VERSION "dbc-export 1 2025.20.8"

NS_ :

BS_:

BU_: APP APS DAS EPAS3S EPASTS ESP GTW IBST IDB PARK RADC RCM RCM3 RCU TPMS USM

BO_ 841 DAS_warningMatrix2: 8 DAS
 SG_ DAS_w129_mainCamExtNotCal : 0|1@1+ (1,0) [0|1] "" Vector__XXX
 SG_ DAS_w130_narrowCamExtNotCal : 1|1@1+ (1,0) [0|1] "" Vector__XXX
 SG_ DAS_w131_mainCamCalSaved : 2|1@1+ (1,0) [0|1] "" Vector__XXX
 SG_ DAS_w132_narrowCamCalSaved : 3|1@1+ (1,0) [0|1] "" Vector__XXX
 SG_ DAS_w133_mainCamInitFault : 4|1@1+ (1,0) [0|1] "" Vector__XXX
 SG_ DAS_w134_narrowCamInitFault : 5|1@1+ (1,0) [0|1] "" Vector__XXX
 SG_ DAS_w135_fisheyeCamInitFault : 6|1@1+ (1,0) [0|1] "" Vector__XXX
 SG_ DAS_w136_lPillarCamInitFault : 7|1@1+ (1,0) [0|1] "" Vector__XXX
 SG_ DAS_w137_rPillarCamInitFault : 8|1@1+ (1,0) [0|1] "" Vector__XXX
 SG_ DAS_w138_lRepeatCamInitFault : 9|1@1+ (1,0) [0|1] "" Vector__XXX
 SG_ DAS_w139_rRepeatCamInitFault : 10|1@1+ (1,0) [0|1] "" Vector__XXX
 SG_ DAS_w140_backupCamInitFault : 11|1@1+ (1,0) [0|1] "" Vector__XXX
 SG_ DAS_w141_ECU_Thermal_Issue : 12|1@1+ (1,0) [0|1] "" Vector__XXX
 SG_ DAS_w142_fwdCamPitchProblem : 13|1@1+ (1,0) [0|1] "" Vector__XXX
 SG_ DAS_w143_IDF_event : 14|1@1+ (1,0) [0|1] "" Vector__XXX
 SG_ DAS_w144_selfieCamInitFault : 15|1@1+ (1,0) [0|1] "" Vector__XXX
 SG_ DAS_w171_fisheyeCamExtNotCal : 42|1@1+ (1,0) [0|1] "" Vector__XXX
 SG_ DAS_w172_lPillarCamExtNotCal : 43|1@1+ (1,0) [0|1] "" Vector__XXX
 SG_ DAS_w173_rPillarCamExtNotCal : 44|1@1+ (1,0) [0|1] "" Vector__XXX
 SG_ DAS_w174_lRepeatCamExtNotCal : 45|1@1+ (1,0) [0|1] "" Vector__XXX
 SG_ DAS_w175_rRepeatCamExtNotCal : 46|1@1+ (1,0) [0|1] "" Vector__XXX
 SG_ DAS_w177_fisheyeCamCalSaved : 48|1@1+ (1,0) [0|1] "" Vector__XXX
 SG_ DAS_w178_lPillarCamCalSaved : 49|1@1+ (1,0) [0|1] "" Vector__XXX
 SG_ DAS_w179_rPillarCamCalSaved : 50|1@1+ (1,0) [0|1] "" Vector__XXX
 SG_ DAS_w180_lRepeatCamCalSaved : 51|1@1+ (1,0) [0|1] "" Vector__XXX
 SG_ DAS_w181_rRepeatCamCalSaved : 52|1@1+ (1,0) [0|1] "" Vector__XXX

BO_ 1082 DAS_warningMatrix3: 8 DAS
 SG_ DAS_w193_camWindshieldUnclean : 0|1@1+ (1,0) [0|1] "" Vector__XXX
 SG_ DAS_w194_accDriverResumeRqrd : 1|1@1+ (1,0) [0|1] "" Vector__XXX
 SG_ DAS_w195_scwUnavailable : 2|1@1+ (1,0) [0|1] "" Vector__XXX
 SG_ DAS_w196_stopSignWarning : 3|1@1+ (1,0) [0|1] "" Vector__XXX
 SG_ DAS_w197_redLightWarning : 4|1@1+ (1,0) [0|1] "" Vector__XXX
 SG_ DAS_w198_tsrUnavailable : 5|1@1+ (1,0) [0|1] "" Vector__XXX
 SG_ DAS_w199_apcAbort : 6|1@1+ (1,0) [0|1] "" Vector__XXX
 SG_ DAS_w200_lcSlowdown : 7|1@1+ (1,0) [0|1] "" Vector__XXX
 SG_ DAS_w201_lcAborting : 8|1@1+ (1,0) [0|1] "" Vector__XXX
 SG_ DAS_w202_scwNoisyEnvironment : 9|1@1+ (1,0) [0|1] "" Vector__XXX
 SG_ DAS_w203_apcActivation : 10|1@1+ (1,0) [0|1] "" Vector__XXX
 SG_ DAS_w204_apcFinalFront : 11|1@1+ (1,0) [0|1] "" Vector__XXX
 SG_ DAS_w205_apcFinalRear : 12|1@1+ (1,0) [0|1] "" Vector__XXX
 SG_ DAS_w206_autosteerNotEnabled : 13|1@1+ (1,0) [0|1] "" Vector__XXX
 SG_ DAS_w207_autosteerUnavailable : 14|1@1+ (1,0) [0|1] "" Vector__XXX
 SG_ DAS_w208_rackDetected : 15|1@1+ (1,0) [0|1] "" Vector__XXX
 SG_ DAS_w209_autoSummonRequest : 16|1@1+ (1,0) [0|1] "" Vector__XXX
 SG_ DAS_w210_camObstrcted : 17|1@1+ (1,0) [0|1] "" Vector__XXX
 SG_ DAS_w211_accNoSeatBelt : 18|1@1+ (1,0) [0|1] "" Vector__XXX
 SG_ DAS_w212_lcUnavailableStrikeOut : 19|1@1+ (1,0) [0|1] "" Vector__XXX
 SG_ DAS_w213_autosteerStruckOut : 20|1@1+ (1,0) [0|1] "" Vector__XXX
 SG_ DAS_w214_driverNotIntracting : 21|1@1+ (1,0) [0|1] "" Vector__XXX
 SG_ DAS_w215_contDriverNotIntracting : 22|1@1+ (1,0) [0|1] "" Vector__XXX
 SG_ DAS_w216_driverOverriding : 23|1@1+ (1,0) [0|1] "" Vector__XXX
 SG_ DAS_w217_lcUnavailableSpeeding : 24|1@1+ (1,0) [0|1] "" Vector__XXX
 SG_ DAS_w218_lcSpeedExceededLimit : 25|1@1+ (1,0) [0|1] "" Vector__XXX
 SG_ DAS_w219_lcTempUnavailableSpeed : 26|1@1+ (1,0) [0|1] "" Vector__XXX
 SG_ DAS_w220_lcTempUnavailableRoad : 27|1@1+ (1,0) [0|1] "" Vector__XXX
 SG_ DAS_w221_accRadarBlind : 28|1@1+ (1,0) [0|1] "" Vector__XXX
 SG_ DAS_w222_accCameraBlind : 29|1@1+ (1,0) [0|1] "" Vector__XXX
 SG_ DAS_w223_accObjectInPath : 30|1@1+ (1,0) [0|1] "" Vector__XXX
 SG_ DAS_w224_accCameraCalibration : 31|1@1+ (1,0) [0|1] "" Vector__XXX
 SG_ DAS_w225_lcDegradedVisSpeedLmt : 32|1@1+ (1,0) [0|1] "" Vector__XXX
 SG_ DAS_w226_lcCamCalNeededSpeedLmt : 33|1@1+ (1,0) [0|1] "" Vector__XXX
 SG_ DAS_w227_virtualWallBlocked : 34|1@1+ (1,0) [0|1] "" Vector__XXX
 SG_ DAS_w228_DEPRECATED : 35|1@1+ (1,0) [0|1] "" Vector__XXX
 SG_ DAS_w229_alcUltrasoundDamaged : 36|1@1+ (1,0) [0|1] "" Vector__XXX
 SG_ DAS_w230_alcUltrasoundBlocked : 37|1@1+ (1,0) [0|1] "" Vector__XXX
 SG_ DAS_w231_idfEvent : 38|1@1+ (1,0) [0|1] "" Vector__XXX
 SG_ DAS_w232_laneChangeRequested : 39|1@1+ (1,0) [0|1] "" Vector__XXX

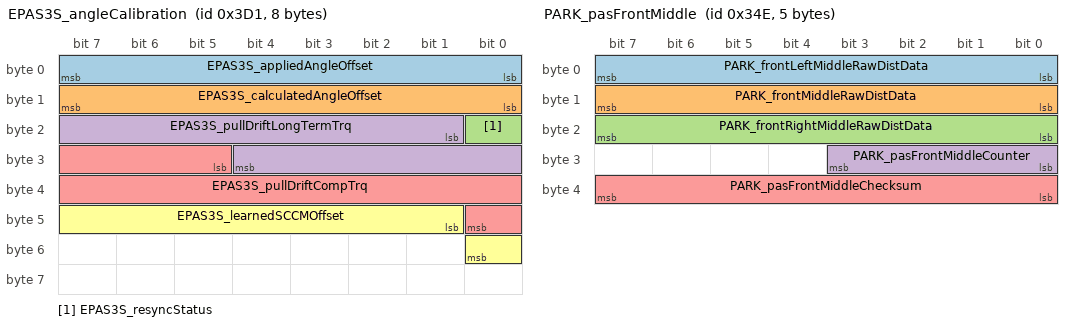
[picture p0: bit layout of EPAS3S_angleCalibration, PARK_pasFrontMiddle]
BO_ 977 EPAS3S_angleCalibration: 8 EPAS3S
 SG_ EPAS3S_appliedAngleOffset : 0|8@1+ (0.1,-12.8) [-12.8|12.7] "deg" Vector__XXX
 SG_ EPAS3S_calculatedAngleOffset : 8|8@1+ (0.1,-12.8) [-12.8|12.7] "deg" Vector__XXX
 SG_ EPAS3S_resyncStatus : 16|1@1+ (1,0) [0|1] "" Vector__XXX
 SG_ EPAS3S_pullDriftLongTermTrq : 17|12@1+ (0.01,-10) [-10|10] "Nm" Vector__XXX
 SG_ EPAS3S_pullDriftCompTrq : 29|12@1+ (0.01,-10) [-10|10] "Nm" Vector__XXX
 SG_ EPAS3S_learnedSCCMOffset : 41|8@1+ (0.1,-12.8) [-12.8|12.7] "deg" Vector__XXX

BO_ 785 EPAS3S_info: 8 EPAS3S
 SG_ EPAS3S_infoIndex M : 0|8@1+ (1,0) [0|255] "" Vector__XXX
 SG_ EPAS3S_infoBuildType m10 : 8|8@1+ (1,0) [0|255] "" Vector__XXX
 SG_ EPAS3S_infoComponentID m10 : 48|16@1+ (1,0) [0|65535] "" Vector__XXX
 SG_ EPAS3S_infoPcbaID m11 : 16|8@1+ (1,0) [0|255] "" Vector__XXX
 SG_ EPAS3S_infoAssemblyID m11 : 24|8@1+ (1,0) [0|255] "" Vector__XXX
 SG_ EPAS3S_infoUsageID m11 : 32|16@1+ (1,0) [0|65535] "" Vector__XXX
 SG_ EPAS3S_infoApplicationCRC m13 : 32|32@1+ (1,0) [0|4294967295] "" Vector__XXX
 SG_ EPAS3S_infoBootUdsProtoVersion m20 : 8|8@1+ (1,0) [0|255] "" Vector__XXX
 SG_ EPAS3S_infoBootloaderCRC m20 : 32|32@1+ (1,0) [0|4294967295] "" Vector__XXX
 SG_ EPAS3S_infoSubcomponent2 m23 : 32|32@1+ (1,0) [0|4294967295] "" Vector__XXX

BO_ 920 EPASTS_alertMatrix: 8 EPASTS
 SG_ EPASTS_matrixIndex M : 0|4@1+ (1,0) [0|15] "" Vector__XXX
 SG_ EPASTS_a001_adcCalibrationOrInit m0 : 4|1@1+ (1,0) [0|1] "" Vector__XXX
 SG_ EPASTS_a002_adcMuxErr m0 : 5|1@1+ (1,0) [0|1] "" Vector__XXX
 SG_ EPASTS_a003_pspInvalidParamset m0 : 6|1@1+ (1,0) [0|1] "" Vector__XXX
 SG_ EPASTS_a004_scpInputMia m0 : 7|1@1+ (1,0) [0|1] "" Vector__XXX
 SG_ EPASTS_a005_scpUnknownResetSourc m0 : 8|1@1+ (1,0) [0|1] "" Vector__XXX
 SG_ EPASTS_a006_swrhResetByInvalidEr m0 : 9|1@1+ (1,0) [0|1] "" Vector__XXX
 SG_ EPASTS_a007_tsmcCoreTempDiff m0 : 10|1@1+ (1,0) [0|1] "" Vector__XXX
 SG_ EPASTS_a008_psdcPlatformShutdown m0 : 11|1@1+ (1,0) [0|1] "" Vector__XXX
 SG_ EPASTS_a009_mcusscLbistPermanent m0 : 12|1@1+ (1,0) [0|1] "" Vector__XXX
 SG_ EPASTS_a010_svcIncompatibleSwVer m0 : 13|1@1+ (1,0) [0|1] "" Vector__XXX
 SG_ EPASTS_a011_mcusscMonbistErr m0 : 14|1@1+ (1,0) [0|1] "" Vector__XXX
 SG_ EPASTS_a012_mcusscMbistEccErr m0 : 15|1@1+ (1,0) [0|1] "" Vector__XXX
 SG_ EPASTS_a013_mcusscSffMonitoringF m0 : 16|1@1+ (1,0) [0|1] "" Vector__XXX
 SG_ EPASTS_a014_mcusscSffMonitoringM m0 : 17|1@1+ (1,0) [0|1] "" Vector__XXX
 SG_ EPASTS_a015_mcusscCsErrorCheckFa m0 : 18|1@1+ (1,0) [0|1] "" Vector__XXX
 SG_ EPASTS_a016_mcufcCsErrorCheckFai m0 : 19|1@1+ (1,0) [0|1] "" Vector__XXX
 SG_ EPASTS_a017_stmdStmPlausibilityC m0 : 20|1@1+ (1,0) [0|1] "" Vector__XXX
 SG_ EPASTS_a018_exchCsErrorCheck m0 : 21|1@1+ (1,0) [0|1] "" Vector__XXX
 SG_ EPASTS_a019_rsthHwResetInfoCorru m0 : 22|1@1+ (1,0) [0|1] "" Vector__XXX
 SG_ EPASTS_a020_mcusscEolEcuIdIntegr m0 : 23|1@1+ (1,0) [0|1] "" Vector__XXX
 SG_ EPASTS_a021_osehCsErrorCheck m0 : 24|1@1+ (1,0) [0|1] "" Vector__XXX
 SG_ EPASTS_a022_swrhSwResetInfoCorru m0 : 25|1@1+ (1,0) [0|1] "" Vector__XXX
 SG_ EPASTS_a023_btarcCorruptionCheck m0 : 26|1@1+ (1,0) [0|1] "" Vector__XXX
 SG_ EPASTS_a024_srhCsErrorCheckFail m0 : 27|1@1+ (1,0) [0|1] "" Vector__XXX
 SG_ EPASTS_a025_btarcCorruptionCheck m0 : 28|1@1+ (1,0) [0|1] "" Vector__XXX
 SG_ EPASTS_a026_mrccCsErrorCheckFail m0 : 29|1@1+ (1,0) [0|1] "" Vector__XXX
 SG_ EPASTS_a027_mcusscDmuHfErr m0 : 30|1@1+ (1,0) [0|1] "" Vector__XXX
 SG_ EPASTS_a028_smuhNonInitDataCorru m0 : 31|1@1+ (1,0) [0|1] "" Vector__XXX
 SG_ EPASTS_a029_smuhSmuCoreCntErrorT m0 : 32|1@1+ (1,0) [0|1] "" Vector__XXX
 SG_ EPASTS_a030_rsthClockReset m0 : 33|1@1+ (1,0) [0|1] "" Vector__XXX
 SG_ EPASTS_a031_pmsProductionModeFai m0 : 34|1@1+ (1,0) [0|1] "" Vector__XXX
 SG_ EPASTS_a032_eolpEolCheckFailed m0 : 35|1@1+ (1,0) [0|1] "" Vector__XXX
 SG_ EPASTS_a033_icsvcPswVersionMisma m0 : 36|1@1+ (1,0) [0|1] "" Vector__XXX
 SG_ EPASTS_a034_sbchReadbackRegFail m0 : 37|1@1+ (1,0) [0|1] "" Vector__XXX
 SG_ EPASTS_a035_sbchChipIdFail m0 : 38|1@1+ (1,0) [0|1] "" Vector__XXX
 SG_ EPASTS_a036_sbcmSbcBistFailed m0 : 39|1@1+ (1,0) [0|1] "" Vector__XXX
 SG_ EPASTS_a037_epmV5P2Fail m0 : 40|1@1+ (1,0) [0|1] "" Vector__XXX
 SG_ EPASTS_a038_csohCh1CsErrorErrAtR m0 : 41|1@1+ (1,0) [0|1] "" Vector__XXX
 SG_ EPASTS_a039_csohCh2CsErrorErrAtR m0 : 42|1@1+ (1,0) [0|1] "" Vector__XXX
 SG_ EPASTS_a040_swrhLimitedResetRetr m0 : 43|1@1+ (1,0) [0|1] "" Vector__XXX
 SG_ EPASTS_a041_imcmCoreConfiguratio m0 : 44|1@1+ (1,0) [0|1] "" Vector__XXX
 SG_ EPASTS_a042_wdhWdTestFail m0 : 45|1@1+ (1,0) [0|1] "" Vector__XXX
 SG_ EPASTS_a043_sbcmWdStateDisabled m0 : 46|1@1+ (1,0) [0|1] "" Vector__XXX
 SG_ EPASTS_a044_sbcmSbcEepromFail m0 : 47|1@1+ (1,0) [0|1] "" Vector__XXX
 SG_ EPASTS_a045_psumSbcBandgapVoltEr m0 : 48|1@1+ (1,0) [0|1] "" Vector__XXX
 SG_ EPASTS_a046_mcusscOscillatorNotR m0 : 49|1@1+ (1,0) [0|1] "" Vector__XXX
 SG_ EPASTS_a047_epmVregVoltFail m0 : 50|1@1+ (1,0) [0|1] "" Vector__XXX
 SG_ EPASTS_a048_epmVcpVoltFail m0 : 51|1@1+ (1,0) [0|1] "" Vector__XXX
 SG_ EPASTS_a049_epmLgFail m0 : 52|1@1+ (1,0) [0|1] "" Vector__XXX
 SG_ EPASTS_a050_erlErr m0 : 53|1@1+ (1,0) [0|1] "" Vector__XXX
 SG_ EPASTS_a051_ermMessageErr m0 : 54|1@1+ (1,0) [0|1] "" Vector__XXX
 SG_ EPASTS_a052_ermSdcInputBufferOve m0 : 55|1@1+ (1,0) [0|1] "" Vector__XXX
 SG_ EPASTS_a053_adcUnexpectedNumOfDa m0 : 56|1@1+ (1,0) [0|1] "" Vector__XXX
 SG_ EPASTS_a054_adcUnexpectedData m0 : 57|1@1+ (1,0) [0|1] "" Vector__XXX
 SG_ EPASTS_a055_amExtendedGduTest m0 : 58|1@1+ (1,0) [0|1] "" Vector__XXX
 SG_ EPASTS_a056_amGduConfigCsErrorCh m0 : 59|1@1+ (1,0) [0|1] "" Vector__XXX
 SG_ EPASTS_a057_amGduVds m0 : 60|1@1+ (1,0) [0|1] "" Vector__XXX
 SG_ EPASTS_a058_amIntVgsUndervtgErr m0 : 61|1@1+ (1,0) [0|1] "" Vector__XXX
 SG_ EPASTS_a059_amStartupTestFailed m0 : 62|1@1+ (1,0) [0|1] "" Vector__XXX
 SG_ EPASTS_a060_amGduFail m0 : 63|1@1+ (1,0) [0|1] "" Vector__XXX
 SG_ EPASTS_a061_amIntSerialErr m1 : 4|1@1+ (1,0) [0|1] "" Vector__XXX
 SG_ EPASTS_a062_amPhaseBridgeCheck m1 : 5|1@1+ (1,0) [0|1] "" Vector__XXX
 SG_ EPASTS_a063_amIntRegulatorErr m1 : 6|1@1+ (1,0) [0|1] "" Vector__XXX
 SG_ EPASTS_a064_amBridgeShort m1 : 7|1@1+ (1,0) [0|1] "" Vector__XXX
 SG_ EPASTS_a065_amGduJuncTemp m1 : 8|1@1+ (1,0) [0|1] "" Vector__XXX
 SG_ EPASTS_a066_amVoltQfErr m1 : 9|1@1+ (1,0) [0|1] "" Vector__XXX
 SG_ EPASTS_a067_tspmPowermoduleTempI m1 : 10|1@1+ (1,0) [0|1] "" Vector__XXX
 SG_ EPASTS_a068_rsthCoreRedundancyEr m1 : 11|1@1+ (1,0) [0|1] "" Vector__XXX
 SG_ EPASTS_a069_rsthCoreTempOutOfRan m1 : 12|1@1+ (1,0) [0|1] "" Vector__XXX
 SG_ EPASTS_a070_rsthInternalLowVolt m1 : 13|1@1+ (1,0) [0|1] "" Vector__XXX
 SG_ EPASTS_a071_rsthInternalHighVolt m1 : 14|1@1+ (1,0) [0|1] "" Vector__XXX
 SG_ EPASTS_a072_rsthFlashUncorrEccOr m1 : 15|1@1+ (1,0) [0|1] "" Vector__XXX
 SG_ EPASTS_a073_rsthOtherEdcEcc m1 : 16|1@1+ (1,0) [0|1] "" Vector__XXX
 SG_ EPASTS_a074_rsthUnexpectedAlarm m1 : 17|1@1+ (1,0) [0|1] "" Vector__XXX
 SG_ EPASTS_a075_rsthUnusedOtherModul m1 : 18|1@1+ (1,0) [0|1] "" Vector__XXX
 SG_ EPASTS_a076_exchGeneralException m1 : 19|1@1+ (1,0) [0|1] "" Vector__XXX
 SG_ EPASTS_a077_dmDeadlineViolation m1 : 20|1@1+ (1,0) [0|1] "" Vector__XXX
 SG_ EPASTS_a078_dmDeadlineViolation m1 : 21|1@1+ (1,0) [0|1] "" Vector__XXX
 SG_ EPASTS_a079_gduhComErr m1 : 22|1@1+ (1,0) [0|1] "" Vector__XXX
 SG_ EPASTS_a080_pwmTimerSyncCheck m1 : 23|1@1+ (1,0) [0|1] "" Vector__XXX
 SG_ EPASTS_a081_exchFloatingPointExc m1 : 24|1@1+ (1,0) [0|1] "" Vector__XXX
 SG_ EPASTS_a082_adcTriggerTimeChk m1 : 25|1@1+ (1,0) [0|1] "" Vector__XXX
 SG_ EPASTS_a083_tdaDclinkcapacitorTe m1 : 26|1@1+ (1,0) [0|1] "" Vector__XXX
 SG_ EPASTS_a084_adcTriggerCheck m1 : 27|1@1+ (1,0) [0|1] "" Vector__XXX
 SG_ EPASTS_a085_amGduSwitchOffTestBy m1 : 28|1@1+ (1,0) [0|1] "" Vector__XXX
 SG_ EPASTS_a086_rsthRamUncorrEcc m1 : 29|1@1+ (1,0) [0|1] "" Vector__XXX
 SG_ EPASTS_a087_rsthFlashConfigErr m1 : 30|1@1+ (1,0) [0|1] "" Vector__XXX
 SG_ EPASTS_a088_tedMainboardTempChec m1 : 31|1@1+ (1,0) [0|1] "" Vector__XXX
 SG_ EPASTS_a089_tedRevercebattfetjun m1 : 32|1@1+ (1,0) [0|1] "" Vector__XXX
 SG_ EPASTS_a090_etsmWarning m1 : 33|1@1+ (1,0) [0|1] "" Vector__XXX
 SG_ EPASTS_a091_bvpBattVoltCrossChkF m1 : 34|1@1+ (1,0) [0|1] "" Vector__XXX
 SG_ EPASTS_a092_amGduSwitchOffTestBy m1 : 35|1@1+ (1,0) [0|1] "" Vector__XXX
 SG_ EPASTS_a093_sctpTsuSingleStaticF m1 : 36|1@1+ (1,0) [0|1] "" Vector__XXX
 SG_ EPASTS_a094_sctpTsuMultipleStati m1 : 37|1@1+ (1,0) [0|1] "" Vector__XXX
 SG_ EPASTS_a095_mdModelBasedMotorInt m1 : 38|1@1+ (1,0) [0|1] "" Vector__XXX
 SG_ EPASTS_a096_rppRpsSingleStaticFa m1 : 39|1@1+ (1,0) [0|1] "" Vector__XXX
 SG_ EPASTS_a097_rppRpsMultipleStatic m1 : 40|1@1+ (1,0) [0|1] "" Vector__XXX
 SG_ EPASTS_a098_invErr m1 : 41|1@1+ (1,0) [0|1] "" Vector__XXX
 SG_ EPASTS_a099_mcdTorqueMismatchFau m1 : 42|1@1+ (1,0) [0|1] "" Vector__XXX
 SG_ EPASTS_a100_amVbrgLssFault m1 : 43|1@1+ (1,0) [0|1] "" Vector__XXX
 SG_ EPASTS_a101_sdrvSpcIdMismatch m1 : 44|1@1+ (1,0) [0|1] "" Vector__XXX
 SG_ EPASTS_a102_amPhasecurrentQosErr m1 : 45|1@1+ (1,0) [0|1] "" Vector__XXX
 SG_ EPASTS_a103_exhaUnusedInterruptC m1 : 46|1@1+ (1,0) [0|1] "" Vector__XXX
 SG_ EPASTS_a104_exhaBusMpuException m1 : 47|1@1+ (1,0) [0|1] "" Vector__XXX
 SG_ EPASTS_a105_exhaSriBusErrExcepti m1 : 48|1@1+ (1,0) [0|1] "" Vector__XXX
 SG_ EPASTS_a106_exhaSpbBusErrExcepti m1 : 49|1@1+ (1,0) [0|1] "" Vector__XXX
 SG_ EPASTS_a107_exhaOtherNmiExceptio m1 : 50|1@1+ (1,0) [0|1] "" Vector__XXX
 SG_ EPASTS_a108_exhaInternalProtecti m1 : 51|1@1+ (1,0) [0|1] "" Vector__XXX
 SG_ EPASTS_a109_exhaSysBusOrPeriphEr m1 : 52|1@1+ (1,0) [0|1] "" Vector__XXX
 SG_ EPASTS_a110_amPhaseRelaySwitchOf m1 : 53|1@1+ (1,0) [0|1] "" Vector__XXX
 SG_ EPASTS_a111_amCurrentSensingDisc m1 : 54|1@1+ (1,0) [0|1] "" Vector__XXX
 SG_ EPASTS_a112_rsthSafetyFlipflopEr m1 : 55|1@1+ (1,0) [0|1] "" Vector__XXX
 SG_ EPASTS_a113_rsthUncorrectableEnd m1 : 56|1@1+ (1,0) [0|1] "" Vector__XXX
 SG_ EPASTS_a114_osehOsErr m1 : 57|1@1+ (1,0) [0|1] "" Vector__XXX
 SG_ EPASTS_a115_mcusscLbistSingleFai m1 : 58|1@1+ (1,0) [0|1] "" Vector__XXX
 SG_ EPASTS_a116_mrccStartupRegCsErro m1 : 59|1@1+ (1,0) [0|1] "" Vector__XXX
 SG_ EPASTS_a117_mrccStartupRegCsErro m1 : 60|1@1+ (1,0) [0|1] "" Vector__XXX
 SG_ EPASTS_a118_mcusscFlashCsErrorEr m1 : 61|1@1+ (1,0) [0|1] "" Vector__XXX
 SG_ EPASTS_a119_mcusscFlashEccCritic m1 : 62|1@1+ (1,0) [0|1] "" Vector__XXX
 SG_ EPASTS_a120_mcusscFlashEccLatent m1 : 63|1@1+ (1,0) [0|1] "" Vector__XXX
 SG_ EPASTS_a121_mcusscMbistEccErr m2 : 4|1@1+ (1,0) [0|1] "" Vector__XXX
 SG_ EPASTS_a122_pcpBridgeFetShort m2 : 5|1@1+ (1,0) [0|1] "" Vector__XXX
 SG_ EPASTS_a123_imcmCommErr m2 : 6|1@1+ (1,0) [0|1] "" Vector__XXX
 SG_ EPASTS_a124_mcusscMbistEccTransi m2 : 7|1@1+ (1,0) [0|1] "" Vector__XXX
 SG_ EPASTS_a125_mcusscMbistMiaErr m2 : 8|1@1+ (1,0) [0|1] "" Vector__XXX
 SG_ EPASTS_a126_mcusscMonbistMiaErr m2 : 9|1@1+ (1,0) [0|1] "" Vector__XXX
 SG_ EPASTS_a127_exchAdditionalExcept m2 : 10|1@1+ (1,0) [0|1] "" Vector__XXX
 SG_ EPASTS_a128_exchExceptionStopRes m2 : 11|1@1+ (1,0) [0|1] "" Vector__XXX
 SG_ EPASTS_a129_exchAdditionalExcept m2 : 12|1@1+ (1,0) [0|1] "" Vector__XXX
 SG_ EPASTS_a130_mrccConfigCsErrorErr m2 : 13|1@1+ (1,0) [0|1] "" Vector__XXX
 SG_ EPASTS_a131_exchGuardedResetAfte m2 : 14|1@1+ (1,0) [0|1] "" Vector__XXX
 SG_ EPASTS_a132_mcusscNotSupportedMc m2 : 15|1@1+ (1,0) [0|1] "" Vector__XXX
 SG_ EPASTS_a133_mcusscLbistEcuIdIsNo m2 : 16|1@1+ (1,0) [0|1] "" Vector__XXX
 SG_ EPASTS_a134_osehGuardedResetAfte m2 : 17|1@1+ (1,0) [0|1] "" Vector__XXX
 SG_ EPASTS_a135_tmpsfetjCalculationO m2 : 18|1@1+ (1,0) [0|1] "" Vector__XXX
 SG_ EPASTS_a136_ftElectricalAngleQf m2 : 19|1@1+ (1,0) [0|1] "" Vector__XXX
 SG_ EPASTS_a137_osehErrWithoutImmedi m2 : 20|1@1+ (1,0) [0|1] "" Vector__XXX
 SG_ EPASTS_a138_osehAdditionalErrWit m2 : 21|1@1+ (1,0) [0|1] "" Vector__XXX
 SG_ EPASTS_a139_osehAdditionalOsErr m2 : 22|1@1+ (1,0) [0|1] "" Vector__XXX
 SG_ EPASTS_a140_imcmConfigurationErr m2 : 23|1@1+ (1,0) [0|1] "" Vector__XXX
 SG_ EPASTS_a141_amFetShortTest m2 : 24|1@1+ (1,0) [0|1] "" Vector__XXX
 SG_ EPASTS_a142_tedEmifilterDmcTempC m2 : 25|1@1+ (1,0) [0|1] "" Vector__XXX
 SG_ EPASTS_a143_tedEmifilterCmcTempC m2 : 26|1@1+ (1,0) [0|1] "" Vector__XXX
 SG_ EPASTS_a144_mriCoreRaminitFailed m2 : 27|1@1+ (1,0) [0|1] "" Vector__XXX
 SG_ EPASTS_a145_mriPeripheralRaminit m2 : 28|1@1+ (1,0) [0|1] "" Vector__XXX
 SG_ EPASTS_a146_btarcRcCircuitCheck m2 : 29|1@1+ (1,0) [0|1] "" Vector__XXX
 SG_ EPASTS_a147_amDcLinkShortedFail m2 : 30|1@1+ (1,0) [0|1] "" Vector__XXX
 SG_ EPASTS_a148_mrccExitFromStandbyD m2 : 31|1@1+ (1,0) [0|1] "" Vector__XXX
 SG_ EPASTS_a149_amReversibleEmergenc m2 : 32|1@1+ (1,0) [0|1] "" Vector__XXX
 SG_ EPASTS_a150_amExternalEmergencyO m2 : 33|1@1+ (1,0) [0|1] "" Vector__XXX
 SG_ EPASTS_a151_amPermanentEmergency m2 : 34|1@1+ (1,0) [0|1] "" Vector__XXX
 SG_ EPASTS_a152_exchFlashEccExceptio m2 : 35|1@1+ (1,0) [0|1] "" Vector__XXX
 SG_ EPASTS_a153_sdsmBlockSelectorInv m2 : 36|1@1+ (1,0) [0|1] "" Vector__XXX
 SG_ EPASTS_a154_sdsmCsErrorInvalidPr m2 : 37|1@1+ (1,0) [0|1] "" Vector__XXX
 SG_ EPASTS_a155_sdsmDataInvalidAll m2 : 38|1@1+ (1,0) [0|1] "" Vector__XXX
 SG_ EPASTS_a156_amIntSerialErrSafety m2 : 39|1@1+ (1,0) [0|1] "" Vector__XXX
 SG_ EPASTS_a157_mcudcpInvalidEcuId m2 : 40|1@1+ (1,0) [0|1] "" Vector__XXX
 SG_ EPASTS_a158_amGduFailDuringRecov m2 : 41|1@1+ (1,0) [0|1] "" Vector__XXX
 SG_ EPASTS_a159_exchFlashWordlineTra m2 : 42|1@1+ (1,0) [0|1] "" Vector__XXX
 SG_ EPASTS_a160_rsthCpu1UnexpectedAl m2 : 43|1@1+ (1,0) [0|1] "" Vector__XXX
 SG_ EPASTS_a161_tdaRelayfetjunctionT m2 : 44|1@1+ (1,0) [0|1] "" Vector__XXX
 SG_ EPASTS_a162_tdaBridgefetjunction m2 : 45|1@1+ (1,0) [0|1] "" Vector__XXX
 SG_ EPASTS_a163_tdaPowermoduleTempCh m2 : 46|1@1+ (1,0) [0|1] "" Vector__XXX
 SG_ EPASTS_a164_tdaBattfetjunctionTe m2 : 47|1@1+ (1,0) [0|1] "" Vector__XXX
 SG_ EPASTS_a165_tdaDcbusshuntTempChe m2 : 48|1@1+ (1,0) [0|1] "" Vector__XXX
 SG_ EPASTS_a166_tdaPhasecurrentshunt m2 : 49|1@1+ (1,0) [0|1] "" Vector__XXX
 SG_ EPASTS_a167_iccd1ErrQueueOverflo m2 : 50|1@1+ (1,0) [0|1] "" Vector__XXX
 SG_ EPASTS_a168_c1csInvalidC1App m2 : 51|1@1+ (1,0) [0|1] "" Vector__XXX
 SG_ EPASTS_a169_scpSafetyReset m2 : 52|1@1+ (1,0) [0|1] "" Vector__XXX
 SG_ EPASTS_a170_pmpDcvoltAge m2 : 53|1@1+ (1,0) [0|1] "" Vector__XXX
 SG_ EPASTS_a171_pmpKgvalueAge m2 : 54|1@1+ (1,0) [0|1] "" Vector__XXX
 SG_ EPASTS_a172_pmpElangMotorcurrent m2 : 55|1@1+ (1,0) [0|1] "" Vector__XXX
 SG_ EPASTS_a173_pmpRotorspeedAge m2 : 56|1@1+ (1,0) [0|1] "" Vector__XXX
 SG_ EPASTS_a174_pmpPhasecurrentAge m2 : 57|1@1+ (1,0) [0|1] "" Vector__XXX
 SG_ EPASTS_a175_exchFlashStoredConfi m2 : 58|1@1+ (1,0) [0|1] "" Vector__XXX
 SG_ EPASTS_a176_exchCpu1ExceptionRes m2 : 59|1@1+ (1,0) [0|1] "" Vector__XXX
 SG_ EPASTS_a177_etsrInvalidated m2 : 60|1@1+ (1,0) [0|1] "" Vector__XXX
 SG_ EPASTS_a178_exchWdtException m2 : 61|1@1+ (1,0) [0|1] "" Vector__XXX
 SG_ EPASTS_a179_tedMotorcoilTempChec m2 : 62|1@1+ (1,0) [0|1] "" Vector__XXX
 SG_ EPASTS_a180_dmDeadlineViolationC m2 : 63|1@1+ (1,0) [0|1] "" Vector__XXX
 SG_ EPASTS_a181_dmDeadlineViolationC m3 : 4|1@1+ (1,0) [0|1] "" Vector__XXX
 SG_ EPASTS_a182_mcdInputMia m3 : 5|1@1+ (1,0) [0|1] "" Vector__XXX
 SG_ EPASTS_a183_sbchCommErrSbcToMcu m3 : 6|1@1+ (1,0) [0|1] "" Vector__XXX
 SG_ EPASTS_a184_sbcmCommBufferOverfl m3 : 7|1@1+ (1,0) [0|1] "" Vector__XXX
 SG_ EPASTS_a185_sbcscpQAWatchdogRese m3 : 8|1@1+ (1,0) [0|1] "" Vector__XXX
 SG_ EPASTS_a186_wdhCommBufferOverflo m3 : 9|1@1+ (1,0) [0|1] "" Vector__XXX
 SG_ EPASTS_a187_epmVoltFail m3 : 10|1@1+ (1,0) [0|1] "" Vector__XXX
 SG_ EPASTS_a188_epmCommBufferOverflo m3 : 11|1@1+ (1,0) [0|1] "" Vector__XXX
 SG_ EPASTS_a189_sbchCommErrMcuToSbc m3 : 12|1@1+ (1,0) [0|1] "" Vector__XXX
 SG_ EPASTS_a190_sbchCommBufferOverfl m3 : 13|1@1+ (1,0) [0|1] "" Vector__XXX
 SG_ EPASTS_a191_sbcscpVcp2VucVoltFai m3 : 14|1@1+ (1,0) [0|1] "" Vector__XXX
 SG_ EPASTS_a192_osumC0CsaNearFull m3 : 15|1@1+ (1,0) [0|1] "" Vector__XXX
 SG_ EPASTS_a193_osumC0StackNearFull m3 : 16|1@1+ (1,0) [0|1] "" Vector__XXX
 SG_ EPASTS_a194_amNvdataLoss m3 : 17|1@1+ (1,0) [0|1] "" Vector__XXX
 SG_ EPASTS_a195_imcmCommErrC1 m3 : 18|1@1+ (1,0) [0|1] "" Vector__XXX
 SG_ EPASTS_a196_topEolTasOffsetInval m3 : 19|1@1+ (1,0) [0|1] "" Vector__XXX
 SG_ EPASTS_a197_difpDifactorInvalid m3 : 20|1@1+ (1,0) [0|1] "" Vector__XXX
 SG_ EPASTS_a198_osumC1CsaNearFull m3 : 21|1@1+ (1,0) [0|1] "" Vector__XXX
 SG_ EPASTS_a199_osumC1StackNearFull m3 : 22|1@1+ (1,0) [0|1] "" Vector__XXX
 SG_ EPASTS_a200_ammInputBufferOverfl m3 : 23|1@1+ (1,0) [0|1] "" Vector__XXX
 SG_ EPASTS_a201_ammOutputBufferOverf m3 : 24|1@1+ (1,0) [0|1] "" Vector__XXX
 SG_ EPASTS_a202_ohnvmpStoredOffsetLo m3 : 25|1@1+ (1,0) [0|1] "" Vector__XXX
 SG_ EPASTS_a203_ctcInterfaceErr m3 : 26|1@1+ (1,0) [0|1] "" Vector__XXX
 SG_ EPASTS_a204_fdpPrevTrqErr m3 : 27|1@1+ (1,0) [0|1] "" Vector__XXX
 SG_ EPASTS_a205_fdrOclFail m3 : 28|1@1+ (1,0) [0|1] "" Vector__XXX
 SG_ EPASTS_a206_fdrOclPartialBlockin m3 : 29|1@1+ (1,0) [0|1] "" Vector__XXX
 SG_ EPASTS_a207_fdrOclFreezing m3 : 30|1@1+ (1,0) [0|1] "" Vector__XXX
 SG_ EPASTS_a208_fdrLowSeverityBlocki m3 : 31|1@1+ (1,0) [0|1] "" Vector__XXX
 SG_ EPASTS_a209_fdrLowSeverityFreezi m3 : 32|1@1+ (1,0) [0|1] "" Vector__XXX
 SG_ EPASTS_a210_fdrTotalBlocking m3 : 33|1@1+ (1,0) [0|1] "" Vector__XXX
 SG_ EPASTS_a211_frmInternalErr m3 : 34|1@1+ (1,0) [0|1] "" Vector__XXX
 SG_ EPASTS_a212_frmDataLost m3 : 35|1@1+ (1,0) [0|1] "" Vector__XXX
 SG_ EPASTS_a213_frmHighFrictionDetec m3 : 36|1@1+ (1,0) [0|1] "" Vector__XXX
 SG_ EPASTS_a214_velInterfaceErr m3 : 37|1@1+ (1,0) [0|1] "" Vector__XXX
 SG_ EPASTS_a215_vsgSafeViolErr m3 : 38|1@1+ (1,0) [0|1] "" Vector__XXX
 SG_ EPASTS_a216_isdgImproperShutdown m3 : 39|1@1+ (1,0) [0|1] "" Vector__XXX
 SG_ EPASTS_a217_msdMasterSilentErr m3 : 40|1@1+ (1,0) [0|1] "" Vector__XXX
 SG_ EPASTS_a218_aadApplicationStateE m3 : 41|1@1+ (1,0) [0|1] "" Vector__XXX
 SG_ EPASTS_a219_frhFastRestartFailed m3 : 42|1@1+ (1,0) [0|1] "" Vector__XXX
 SG_ EPASTS_a220_transceiverInputqueu m3 : 43|1@1+ (1,0) [0|1] "" Vector__XXX
 SG_ EPASTS_a221_apsCntError m3 : 44|1@1+ (1,0) [0|1] "" Vector__XXX
 SG_ EPASTS_a222_apsCsError m3 : 45|1@1+ (1,0) [0|1] "" Vector__XXX
 SG_ EPASTS_a223_apsMia m3 : 46|1@1+ (1,0) [0|1] "" Vector__XXX
 SG_ EPASTS_a224_dasCntError m3 : 47|1@1+ (1,0) [0|1] "" Vector__XXX
 SG_ EPASTS_a225_dasCsError m3 : 48|1@1+ (1,0) [0|1] "" Vector__XXX
 SG_ EPASTS_a226_dasMia m3 : 49|1@1+ (1,0) [0|1] "" Vector__XXX
 SG_ EPASTS_a227_dirTorqueCntError m3 : 50|1@1+ (1,0) [0|1] "" Vector__XXX
 SG_ EPASTS_a228_dirTorqueCsError m3 : 51|1@1+ (1,0) [0|1] "" Vector__XXX
 SG_ EPASTS_a229_dirTorqueMia m3 : 52|1@1+ (1,0) [0|1] "" Vector__XXX
 SG_ EPASTS_a230_diSpdCntError m3 : 53|1@1+ (1,0) [0|1] "" Vector__XXX
 SG_ EPASTS_a231_diSpdCsError m3 : 54|1@1+ (1,0) [0|1] "" Vector__XXX
 SG_ EPASTS_a232_diSpdMia m3 : 55|1@1+ (1,0) [0|1] "" Vector__XXX
 SG_ EPASTS_a233_ecu1StatCntError m3 : 56|1@1+ (1,0) [0|1] "" Vector__XXX
 SG_ EPASTS_a234_ecu1StatCsError m3 : 57|1@1+ (1,0) [0|1] "" Vector__XXX
 SG_ EPASTS_a235_ecu1StatMia m3 : 58|1@1+ (1,0) [0|1] "" Vector__XXX
 SG_ EPASTS_a236_espWrCntError m3 : 59|1@1+ (1,0) [0|1] "" Vector__XXX
 SG_ EPASTS_a237_espWrCsError m3 : 60|1@1+ (1,0) [0|1] "" Vector__XXX
 SG_ EPASTS_a238_espWrMia m3 : 61|1@1+ (1,0) [0|1] "" Vector__XXX
 SG_ EPASTS_a239_espWsCntError m3 : 62|1@1+ (1,0) [0|1] "" Vector__XXX
 SG_ EPASTS_a240_espWsCsError m3 : 63|1@1+ (1,0) [0|1] "" Vector__XXX
 SG_ EPASTS_a241_espWsMia m4 : 4|1@1+ (1,0) [0|1] "" Vector__XXX
 SG_ EPASTS_a242_gtwConfigMia m4 : 5|1@1+ (1,0) [0|1] "" Vector__XXX
 SG_ EPASTS_a243_rcmCntError m4 : 6|1@1+ (1,0) [0|1] "" Vector__XXX
 SG_ EPASTS_a244_rcmCsError m4 : 7|1@1+ (1,0) [0|1] "" Vector__XXX
 SG_ EPASTS_a245_rcmMia m4 : 8|1@1+ (1,0) [0|1] "" Vector__XXX
 SG_ EPASTS_a246_sccmCntError m4 : 9|1@1+ (1,0) [0|1] "" Vector__XXX
 SG_ EPASTS_a247_sccmCsError m4 : 10|1@1+ (1,0) [0|1] "" Vector__XXX
 SG_ EPASTS_a248_sccmMia m4 : 11|1@1+ (1,0) [0|1] "" Vector__XXX
 SG_ EPASTS_a249_uiTuneReqCntError m4 : 12|1@1+ (1,0) [0|1] "" Vector__XXX
 SG_ EPASTS_a250_uiTuneReqCsError m4 : 13|1@1+ (1,0) [0|1] "" Vector__XXX
 SG_ EPASTS_a251_uiTuneReqMia m4 : 14|1@1+ (1,0) [0|1] "" Vector__XXX
 SG_ EPASTS_a252_vcFrontCntError m4 : 15|1@1+ (1,0) [0|1] "" Vector__XXX
 SG_ EPASTS_a253_vcFrontCsError m4 : 16|1@1+ (1,0) [0|1] "" Vector__XXX
 SG_ EPASTS_a254_vcFrontMia m4 : 17|1@1+ (1,0) [0|1] "" Vector__XXX
 SG_ EPASTS_a255_pmState2Mia m4 : 18|1@1+ (1,0) [0|1] "" Vector__XXX
 SG_ EPASTS_a256_dcvmOverVolt m4 : 19|1@1+ (1,0) [0|1] "" Vector__XXX
 SG_ EPASTS_a257_dcvmUnderVolt m4 : 20|1@1+ (1,0) [0|1] "" Vector__XXX
 SG_ EPASTS_a258_pspInvalidProjectPar m4 : 21|1@1+ (1,0) [0|1] "" Vector__XXX
 SG_ EPASTS_a259_scoCanBusOff m4 : 22|1@1+ (1,0) [0|1] "" Vector__XXX
 SG_ EPASTS_a260_scoPrivateBusOff m4 : 23|1@1+ (1,0) [0|1] "" Vector__XXX
 SG_ EPASTS_a261_sccmStatusError m4 : 24|1@1+ (1,0) [0|1] "" Vector__XXX
 SG_ EPASTS_a262_yawRateStatus m4 : 25|1@1+ (1,0) [0|1] "" Vector__XXX
 SG_ EPASTS_a263_espWsStatus m4 : 26|1@1+ (1,0) [0|1] "" Vector__XXX
 SG_ EPASTS_a264_assistTorqueLimited m4 : 27|1@1+ (1,0) [0|1] "" Vector__XXX
 SG_ EPASTS_a265_overheatProtect m4 : 28|1@1+ (1,0) [0|1] "" Vector__XXX
 SG_ EPASTS_a266_overloadProtect m4 : 29|1@1+ (1,0) [0|1] "" Vector__XXX
 SG_ EPASTS_a267_safeSpeedAssist m4 : 30|1@1+ (1,0) [0|1] "" Vector__XXX
 SG_ EPASTS_a268_eacCancelled m4 : 31|1@1+ (1,0) [0|1] "" Vector__XXX
 SG_ EPASTS_a269_assistTorqueDisabled m4 : 32|1@1+ (1,0) [0|1] "" Vector__XXX
 SG_ EPASTS_a270_oscillationCompTrqLi m4 : 33|1@1+ (1,0) [0|1] "" Vector__XXX

BO_ 805 ESP_info: 8 ESP
 SG_ ESP_infoIndex M : 0|8@1+ (1,0) [0|255] "" Vector__XXX
 SG_ ESP_infoBuildType m10 : 8|8@1+ (1,0) [0|255] "" Vector__XXX
 SG_ ESP_vehFlashMode m10 : 24|1@1+ (1,0) [0|1] "" Vector__XXX
 SG_ ESP_infoComponentID m10 : 48|16@1+ (1,0) [0|65535] "" Vector__XXX
 SG_ ESP_infoPcbaID m11 : 16|8@1+ (1,0) [0|255] "" Vector__XXX
 SG_ ESP_infoAssemblyID m11 : 24|8@1+ (1,0) [0|255] "" Vector__XXX
 SG_ ESP_infoUsageID m11 : 32|16@1+ (1,0) [0|65535] "" Vector__XXX
 SG_ ESP_infoSubUsageID m11 : 48|16@1+ (1,0) [0|65535] "" Vector__XXX
 SG_ ESP_infoApplicationCRC m13 : 39|32@0+ (1,0) [0|4294967295] "" Vector__XXX
 SG_ ESP_infoVehicleVariant m16 : 16|8@1+ (1,0) [0|255] "" Vector__XXX
 SG_ ESP_infoSubcomponent1 m16 : 32|32@1+ (1,0) [0|4294967295] "" Vector__XXX
 SG_ ESP_infoBootUdsProtoVersion m20 : 8|8@1+ (1,0) [0|255] "" Vector__XXX
 SG_ ESP_infoBootloaderCRC m20 : 32|32@1+ (1,0) [0|4294967295] "" Vector__XXX
 SG_ ESP_infoVariantCRC m22 : 39|32@0+ (1,0) [0|4294967295] "" Vector__XXX

BO_ 813 IBST_info: 8 IBST
 SG_ IBST_infoIndex M : 0|8@1+ (1,0) [0|255] "" Vector__XXX
 SG_ IBST_infoBuildType m10 : 8|8@1+ (1,0) [0|255] "" Vector__XXX
 SG_ IBST_infoComponentID m10 : 55|16@0+ (1,0) [0|65535] "" Vector__XXX
 SG_ IBST_infoPcbaID m11 : 16|8@1+ (1,0) [0|255] "" Vector__XXX
 SG_ IBST_infoAssemblyID m11 : 24|8@1+ (1,0) [0|255] "" Vector__XXX
 SG_ IBST_infoUsageID m11 : 32|16@1+ (1,0) [0|65535] "" Vector__XXX
 SG_ IBST_infoSubUsageID m11 : 48|16@1+ (1,0) [0|65535] "" Vector__XXX
 SG_ IBST_infoApplicationCRC m13 : 32|32@1+ (1,0) [0|4294967295] "" Vector__XXX
 SG_ IBST_infoBootUdsProtoVersion m20 : 8|8@1+ (1,0) [0|255] "" Vector__XXX
 SG_ IBST_infoBootloaderCRC m20 : 32|32@1+ (1,0) [0|4294967295] "" Vector__XXX
 SG_ IBST_infoVariantCRC m22 : 32|32@1+ (1,0) [0|4294967295] "" Vector__XXX

BO_ 828 IDB_info: 8 IDB
 SG_ IDB_infoIndex M : 0|8@1+ (1,0) [0|255] "" Vector__XXX
 SG_ IDB_infoPcbaID m11 : 16|8@1+ (1,0) [0|255] "" Vector__XXX
 SG_ IDB_infoAssemblyID m11 : 24|8@1+ (1,0) [0|255] "" Vector__XXX
 SG_ IDB_infoUsageID m11 : 32|16@1+ (1,0) [0|65535] "" Vector__XXX
 SG_ IDB_infoSubUsageID m11 : 48|16@1+ (1,0) [0|65535] "" Vector__XXX

BO_ 1486 PARK_alertLog: 8 PARK
 SG_ PARK_alertID M : 0|7@1+ (1,0) [0|127] "" Vector__XXX
 SG_ PARK_alertState : 15|1@1+ (1,0) [0|1] "" Vector__XXX
 SG_ PARK_sw001_sensorTemperature m1 : 16|16@1+ (0.1,-40) [-40|6513.5] "deg" Vector__XXX
 SG_ PARK_sw002_membraneDisconct m2 : 16|1@1+ (1,0) [0|1] "" Vector__XXX
 SG_ PARK_sw002_dampResistorFail m2 : 17|1@1+ (1,0) [0|1] "" Vector__XXX
 SG_ PARK_sw002_resonanceDrift m2 : 18|1@1+ (1,0) [0|1] "" Vector__XXX
 SG_ PARK_sw002_sensorCRC m2 : 19|1@1+ (1,0) [0|1] "" Vector__XXX
 SG_ PARK_sw002_recieveFailure m2 : 20|1@1+ (1,0) [0|1] "" Vector__XXX
 SG_ PARK_sw002_diagnosticTransferErr m2 : 21|1@1+ (1,0) [0|1] "" Vector__XXX
 SG_ PARK_sw003_linError m3 : 16|1@1+ (1,0) [0|1] "" Vector__XXX
 SG_ PARK_sw003_linBusError m3 : 17|1@1+ (1,0) [0|1] "" Vector__XXX
 SG_ PARK_sw003_linFrameCountError m3 : 18|1@1+ (1,0) [0|1] "" Vector__XXX
 SG_ PARK_sw004_reverbPeriod m4 : 16|16@1+ (1,0) [0|65535] "microseconds" Vector__XXX
 SG_ PARK_sw004_reverbTime m4 : 32|16@1+ (1,0) [0|65535] "microseconds" Vector__XXX
 SG_ PARK_sw004_highAttenTime m4 : 48|1@1+ (1,0) [0|1] "" Vector__XXX
 SG_ PARK_sw004_closeConstEcho m4 : 49|1@1+ (1,0) [0|1] "" Vector__XXX
 SG_ PARK_sw004_lowAttenTime m4 : 50|1@1+ (1,0) [0|1] "" Vector__XXX
 SG_ PARK_sw004_attenTimeJitter m4 : 51|1@1+ (1,0) [0|1] "" Vector__XXX
 SG_ PARK_sw004_reverbFreqJitter m4 : 52|1@1+ (1,0) [0|1] "" Vector__XXX
 SG_ PARK_sw006_sensorTemperature m6 : 16|16@1+ (0.1,-40) [-40|6513.5] "deg" Vector__XXX
 SG_ PARK_sw007_membraneDisconct m7 : 16|1@1+ (1,0) [0|1] "" Vector__XXX
 SG_ PARK_sw007_dampResistorFail m7 : 17|1@1+ (1,0) [0|1] "" Vector__XXX
 SG_ PARK_sw007_resonanceDrift m7 : 18|1@1+ (1,0) [0|1] "" Vector__XXX
 SG_ PARK_sw007_sensorCRC m7 : 19|1@1+ (1,0) [0|1] "" Vector__XXX
 SG_ PARK_sw007_recieveFailure m7 : 20|1@1+ (1,0) [0|1] "" Vector__XXX
 SG_ PARK_sw007_diagnosticTransferErr m7 : 21|1@1+ (1,0) [0|1] "" Vector__XXX
 SG_ PARK_sw008_linError m8 : 16|1@1+ (1,0) [0|1] "" Vector__XXX
 SG_ PARK_sw008_linBusError m8 : 17|1@1+ (1,0) [0|1] "" Vector__XXX
 SG_ PARK_sw008_linFrameCountError m8 : 18|1@1+ (1,0) [0|1] "" Vector__XXX
 SG_ PARK_sw009_reverbPeriod m9 : 16|16@1+ (1,0) [0|65535] "microseconds" Vector__XXX
 SG_ PARK_sw009_reverbTime m9 : 32|16@1+ (1,0) [0|65535] "microseconds" Vector__XXX
 SG_ PARK_sw009_highAttenTime m9 : 48|1@1+ (1,0) [0|1] "" Vector__XXX
 SG_ PARK_sw009_closeConstEcho m9 : 49|1@1+ (1,0) [0|1] "" Vector__XXX
 SG_ PARK_sw009_lowAttenTime m9 : 50|1@1+ (1,0) [0|1] "" Vector__XXX
 SG_ PARK_sw009_attenTimeJitter m9 : 51|1@1+ (1,0) [0|1] "" Vector__XXX
 SG_ PARK_sw009_reverbFreqJitter m9 : 52|1@1+ (1,0) [0|1] "" Vector__XXX
 SG_ PARK_sw011_sensorTemperature m11 : 16|16@1+ (0.1,-40) [-40|6513.5] "deg" Vector__XXX
 SG_ PARK_sw012_membraneDisconct m12 : 16|1@1+ (1,0) [0|1] "" Vector__XXX
 SG_ PARK_sw012_dampResistorFail m12 : 17|1@1+ (1,0) [0|1] "" Vector__XXX
 SG_ PARK_sw012_resonanceDrift m12 : 18|1@1+ (1,0) [0|1] "" Vector__XXX
 SG_ PARK_sw012_sensorCRC m12 : 19|1@1+ (1,0) [0|1] "" Vector__XXX
 SG_ PARK_sw012_recieveFailure m12 : 20|1@1+ (1,0) [0|1] "" Vector__XXX
 SG_ PARK_sw012_diagnosticTransferErr m12 : 21|1@1+ (1,0) [0|1] "" Vector__XXX
 SG_ PARK_sw013_linError m13 : 16|1@1+ (1,0) [0|1] "" Vector__XXX
 SG_ PARK_sw013_linBusError m13 : 17|1@1+ (1,0) [0|1] "" Vector__XXX
 SG_ PARK_sw013_linFrameCountError m13 : 18|1@1+ (1,0) [0|1] "" Vector__XXX
 SG_ PARK_sw014_reverbPeriod m14 : 16|16@1+ (1,0) [0|65535] "microseconds" Vector__XXX
 SG_ PARK_sw014_reverbTime m14 : 32|16@1+ (1,0) [0|65535] "microseconds" Vector__XXX
 SG_ PARK_sw014_highAttenTime m14 : 48|1@1+ (1,0) [0|1] "" Vector__XXX
 SG_ PARK_sw014_closeConstEcho m14 : 49|1@1+ (1,0) [0|1] "" Vector__XXX
 SG_ PARK_sw014_lowAttenTime m14 : 50|1@1+ (1,0) [0|1] "" Vector__XXX
 SG_ PARK_sw014_attenTimeJitter m14 : 51|1@1+ (1,0) [0|1] "" Vector__XXX
 SG_ PARK_sw014_reverbFreqJitter m14 : 52|1@1+ (1,0) [0|1] "" Vector__XXX
 SG_ PARK_sw016_sensorTemperature m16 : 16|16@1+ (0.1,-40) [-40|6513.5] "deg" Vector__XXX
 SG_ PARK_sw017_membraneDisconct m17 : 16|1@1+ (1,0) [0|1] "" Vector__XXX
 SG_ PARK_sw017_dampResistorFail m17 : 17|1@1+ (1,0) [0|1] "" Vector__XXX
 SG_ PARK_sw017_resonanceDrift m17 : 18|1@1+ (1,0) [0|1] "" Vector__XXX
 SG_ PARK_sw017_sensorCRC m17 : 19|1@1+ (1,0) [0|1] "" Vector__XXX
 SG_ PARK_sw017_recieveFailure m17 : 20|1@1+ (1,0) [0|1] "" Vector__XXX
 SG_ PARK_sw017_diagnosticTransferErr m17 : 21|1@1+ (1,0) [0|1] "" Vector__XXX
 SG_ PARK_sw018_linError m18 : 16|1@1+ (1,0) [0|1] "" Vector__XXX
 SG_ PARK_sw018_linBusError m18 : 17|1@1+ (1,0) [0|1] "" Vector__XXX
 SG_ PARK_sw018_linFrameCountError m18 : 18|1@1+ (1,0) [0|1] "" Vector__XXX
 SG_ PARK_sw019_reverbPeriod m19 : 16|16@1+ (1,0) [0|65535] "microseconds" Vector__XXX
 SG_ PARK_sw019_reverbTime m19 : 32|16@1+ (1,0) [0|65535] "microseconds" Vector__XXX
 SG_ PARK_sw019_highAttenTime m19 : 48|1@1+ (1,0) [0|1] "" Vector__XXX
 SG_ PARK_sw019_closeConstEcho m19 : 49|1@1+ (1,0) [0|1] "" Vector__XXX
 SG_ PARK_sw019_lowAttenTime m19 : 50|1@1+ (1,0) [0|1] "" Vector__XXX
 SG_ PARK_sw019_attenTimeJitter m19 : 51|1@1+ (1,0) [0|1] "" Vector__XXX
 SG_ PARK_sw019_reverbFreqJitter m19 : 52|1@1+ (1,0) [0|1] "" Vector__XXX
 SG_ PARK_sw021_sensorTemperature m21 : 16|16@1+ (0.1,-40) [-40|6513.5] "deg" Vector__XXX
 SG_ PARK_sw022_membraneDisconct m22 : 16|1@1+ (1,0) [0|1] "" Vector__XXX
 SG_ PARK_sw022_dampResistorFail m22 : 17|1@1+ (1,0) [0|1] "" Vector__XXX
 SG_ PARK_sw022_resonanceDrift m22 : 18|1@1+ (1,0) [0|1] "" Vector__XXX
 SG_ PARK_sw022_sensorCRC m22 : 19|1@1+ (1,0) [0|1] "" Vector__XXX
 SG_ PARK_sw022_recieveFailure m22 : 20|1@1+ (1,0) [0|1] "" Vector__XXX
 SG_ PARK_sw022_diagnosticTransferErr m22 : 21|1@1+ (1,0) [0|1] "" Vector__XXX
 SG_ PARK_sw023_linError m23 : 16|1@1+ (1,0) [0|1] "" Vector__XXX
 SG_ PARK_sw023_linBusError m23 : 17|1@1+ (1,0) [0|1] "" Vector__XXX
 SG_ PARK_sw023_linFrameCountError m23 : 18|1@1+ (1,0) [0|1] "" Vector__XXX
 SG_ PARK_sw024_reverbPeriod m24 : 16|16@1+ (1,0) [0|65535] "microseconds" Vector__XXX
 SG_ PARK_sw024_reverbTime m24 : 32|16@1+ (1,0) [0|65535] "microseconds" Vector__XXX
 SG_ PARK_sw024_highAttenTime m24 : 48|1@1+ (1,0) [0|1] "" Vector__XXX
 SG_ PARK_sw024_closeConstEcho m24 : 49|1@1+ (1,0) [0|1] "" Vector__XXX
 SG_ PARK_sw024_lowAttenTime m24 : 50|1@1+ (1,0) [0|1] "" Vector__XXX
 SG_ PARK_sw024_attenTimeJitter m24 : 51|1@1+ (1,0) [0|1] "" Vector__XXX
 SG_ PARK_sw024_reverbFreqJitter m24 : 52|1@1+ (1,0) [0|1] "" Vector__XXX
 SG_ PARK_sw026_sensorTemperature m26 : 16|16@1+ (0.1,-40) [-40|6513.5] "deg" Vector__XXX
 SG_ PARK_sw027_membraneDisconct m27 : 16|1@1+ (1,0) [0|1] "" Vector__XXX
 SG_ PARK_sw027_dampResistorFail m27 : 17|1@1+ (1,0) [0|1] "" Vector__XXX
 SG_ PARK_sw027_resonanceDrift m27 : 18|1@1+ (1,0) [0|1] "" Vector__XXX
 SG_ PARK_sw027_sensorCRC m27 : 19|1@1+ (1,0) [0|1] "" Vector__XXX
 SG_ PARK_sw027_recieveFailure m27 : 20|1@1+ (1,0) [0|1] "" Vector__XXX
 SG_ PARK_sw027_diagnosticTransferErr m27 : 21|1@1+ (1,0) [0|1] "" Vector__XXX
 SG_ PARK_sw028_linError m28 : 16|1@1+ (1,0) [0|1] "" Vector__XXX
 SG_ PARK_sw028_linBusError m28 : 17|1@1+ (1,0) [0|1] "" Vector__XXX
 SG_ PARK_sw028_linFrameCountError m28 : 18|1@1+ (1,0) [0|1] "" Vector__XXX
 SG_ PARK_sw029_reverbPeriod m29 : 16|16@1+ (1,0) [0|65535] "microseconds" Vector__XXX
 SG_ PARK_sw029_reverbTime m29 : 32|16@1+ (1,0) [0|65535] "microseconds" Vector__XXX
 SG_ PARK_sw029_highAttenTime m29 : 48|1@1+ (1,0) [0|1] "" Vector__XXX
 SG_ PARK_sw029_closeConstEcho m29 : 49|1@1+ (1,0) [0|1] "" Vector__XXX
 SG_ PARK_sw029_lowAttenTime m29 : 50|1@1+ (1,0) [0|1] "" Vector__XXX
 SG_ PARK_sw029_attenTimeJitter m29 : 51|1@1+ (1,0) [0|1] "" Vector__XXX
 SG_ PARK_sw029_reverbFreqJitter m29 : 52|1@1+ (1,0) [0|1] "" Vector__XXX
 SG_ PARK_sw031_sensorTemperature m31 : 16|16@1+ (0.1,-40) [-40|6513.5] "deg" Vector__XXX
 SG_ PARK_sw032_membraneDisconct m32 : 16|1@1+ (1,0) [0|1] "" Vector__XXX
 SG_ PARK_sw032_dampResistorFail m32 : 17|1@1+ (1,0) [0|1] "" Vector__XXX
 SG_ PARK_sw032_resonanceDrift m32 : 18|1@1+ (1,0) [0|1] "" Vector__XXX
 SG_ PARK_sw032_sensorCRC m32 : 19|1@1+ (1,0) [0|1] "" Vector__XXX
 SG_ PARK_sw032_recieveFailure m32 : 20|1@1+ (1,0) [0|1] "" Vector__XXX
 SG_ PARK_sw032_diagnosticTransferErr m32 : 21|1@1+ (1,0) [0|1] "" Vector__XXX
 SG_ PARK_sw033_linError m33 : 16|1@1+ (1,0) [0|1] "" Vector__XXX
 SG_ PARK_sw033_linBusError m33 : 17|1@1+ (1,0) [0|1] "" Vector__XXX
 SG_ PARK_sw033_linFrameCountError m33 : 18|1@1+ (1,0) [0|1] "" Vector__XXX
 SG_ PARK_sw034_reverbPeriod m34 : 16|16@1+ (1,0) [0|65535] "microseconds" Vector__XXX
 SG_ PARK_sw034_reverbTime m34 : 32|16@1+ (1,0) [0|65535] "microseconds" Vector__XXX
 SG_ PARK_sw034_highAttenTime m34 : 48|1@1+ (1,0) [0|1] "" Vector__XXX
 SG_ PARK_sw034_closeConstEcho m34 : 49|1@1+ (1,0) [0|1] "" Vector__XXX
 SG_ PARK_sw034_lowAttenTime m34 : 50|1@1+ (1,0) [0|1] "" Vector__XXX
 SG_ PARK_sw034_attenTimeJitter m34 : 51|1@1+ (1,0) [0|1] "" Vector__XXX
 SG_ PARK_sw034_reverbFreqJitter m34 : 52|1@1+ (1,0) [0|1] "" Vector__XXX
 SG_ PARK_sw036_sensorTemperature m36 : 16|16@1+ (0.1,-40) [-40|6513.5] "deg" Vector__XXX
 SG_ PARK_sw037_membraneDisconct m37 : 16|1@1+ (1,0) [0|1] "" Vector__XXX
 SG_ PARK_sw037_dampResistorFail m37 : 17|1@1+ (1,0) [0|1] "" Vector__XXX
 SG_ PARK_sw037_resonanceDrift m37 : 18|1@1+ (1,0) [0|1] "" Vector__XXX
 SG_ PARK_sw037_sensorCRC m37 : 19|1@1+ (1,0) [0|1] "" Vector__XXX
 SG_ PARK_sw037_recieveFailure m37 : 20|1@1+ (1,0) [0|1] "" Vector__XXX
 SG_ PARK_sw037_diagnosticTransferErr m37 : 21|1@1+ (1,0) [0|1] "" Vector__XXX
 SG_ PARK_sw038_linError m38 : 16|1@1+ (1,0) [0|1] "" Vector__XXX
 SG_ PARK_sw038_linBusError m38 : 17|1@1+ (1,0) [0|1] "" Vector__XXX
 SG_ PARK_sw038_linFrameCountError m38 : 18|1@1+ (1,0) [0|1] "" Vector__XXX
 SG_ PARK_sw039_reverbPeriod m39 : 16|16@1+ (1,0) [0|65535] "microseconds" Vector__XXX
 SG_ PARK_sw039_reverbTime m39 : 32|16@1+ (1,0) [0|65535] "microseconds" Vector__XXX
 SG_ PARK_sw039_highAttenTime m39 : 48|1@1+ (1,0) [0|1] "" Vector__XXX
 SG_ PARK_sw039_closeConstEcho m39 : 49|1@1+ (1,0) [0|1] "" Vector__XXX
 SG_ PARK_sw039_lowAttenTime m39 : 50|1@1+ (1,0) [0|1] "" Vector__XXX
 SG_ PARK_sw039_attenTimeJitter m39 : 51|1@1+ (1,0) [0|1] "" Vector__XXX
 SG_ PARK_sw039_reverbFreqJitter m39 : 52|1@1+ (1,0) [0|1] "" Vector__XXX
 SG_ PARK_sw041_sensorTemperature m41 : 16|16@1+ (0.1,-40) [-40|6513.5] "deg" Vector__XXX
 SG_ PARK_sw042_membraneDisconct m42 : 16|1@1+ (1,0) [0|1] "" Vector__XXX
 SG_ PARK_sw042_dampResistorFail m42 : 17|1@1+ (1,0) [0|1] "" Vector__XXX
 SG_ PARK_sw042_resonanceDrift m42 : 18|1@1+ (1,0) [0|1] "" Vector__XXX
 SG_ PARK_sw042_sensorCRC m42 : 19|1@1+ (1,0) [0|1] "" Vector__XXX
 SG_ PARK_sw042_recieveFailure m42 : 20|1@1+ (1,0) [0|1] "" Vector__XXX
 SG_ PARK_sw042_diagnosticTransferErr m42 : 21|1@1+ (1,0) [0|1] "" Vector__XXX
 SG_ PARK_sw043_linError m43 : 16|1@1+ (1,0) [0|1] "" Vector__XXX
 SG_ PARK_sw043_linBusError m43 : 17|1@1+ (1,0) [0|1] "" Vector__XXX
 SG_ PARK_sw043_linFrameCountError m43 : 18|1@1+ (1,0) [0|1] "" Vector__XXX
 SG_ PARK_sw044_reverbPeriod m44 : 16|16@1+ (1,0) [0|65535] "microseconds" Vector__XXX
 SG_ PARK_sw044_reverbTime m44 : 32|16@1+ (1,0) [0|65535] "microseconds" Vector__XXX
 SG_ PARK_sw044_highAttenTime m44 : 48|1@1+ (1,0) [0|1] "" Vector__XXX
 SG_ PARK_sw044_closeConstEcho m44 : 49|1@1+ (1,0) [0|1] "" Vector__XXX
 SG_ PARK_sw044_lowAttenTime m44 : 50|1@1+ (1,0) [0|1] "" Vector__XXX
 SG_ PARK_sw044_attenTimeJitter m44 : 51|1@1+ (1,0) [0|1] "" Vector__XXX
 SG_ PARK_sw044_reverbFreqJitter m44 : 52|1@1+ (1,0) [0|1] "" Vector__XXX
 SG_ PARK_sw046_sensorTemperature m46 : 16|16@1+ (0.1,-40) [-40|6513.5] "deg" Vector__XXX
 SG_ PARK_sw047_membraneDisconct m47 : 16|1@1+ (1,0) [0|1] "" Vector__XXX
 SG_ PARK_sw047_dampResistorFail m47 : 17|1@1+ (1,0) [0|1] "" Vector__XXX
 SG_ PARK_sw047_resonanceDrift m47 : 18|1@1+ (1,0) [0|1] "" Vector__XXX
 SG_ PARK_sw047_sensorCRC m47 : 19|1@1+ (1,0) [0|1] "" Vector__XXX
 SG_ PARK_sw047_recieveFailure m47 : 20|1@1+ (1,0) [0|1] "" Vector__XXX
 SG_ PARK_sw047_diagnosticTransferErr m47 : 21|1@1+ (1,0) [0|1] "" Vector__XXX
 SG_ PARK_sw048_linError m48 : 16|1@1+ (1,0) [0|1] "" Vector__XXX
 SG_ PARK_sw048_linBusError m48 : 17|1@1+ (1,0) [0|1] "" Vector__XXX
 SG_ PARK_sw048_linFrameCountError m48 : 18|1@1+ (1,0) [0|1] "" Vector__XXX
 SG_ PARK_sw049_reverbPeriod m49 : 16|16@1+ (1,0) [0|65535] "microseconds" Vector__XXX
 SG_ PARK_sw049_reverbTime m49 : 32|16@1+ (1,0) [0|65535] "microseconds" Vector__XXX
 SG_ PARK_sw049_highAttenTime m49 : 48|1@1+ (1,0) [0|1] "" Vector__XXX
 SG_ PARK_sw049_closeConstEcho m49 : 49|1@1+ (1,0) [0|1] "" Vector__XXX
 SG_ PARK_sw049_lowAttenTime m49 : 50|1@1+ (1,0) [0|1] "" Vector__XXX
 SG_ PARK_sw049_attenTimeJitter m49 : 51|1@1+ (1,0) [0|1] "" Vector__XXX
 SG_ PARK_sw049_reverbFreqJitter m49 : 52|1@1+ (1,0) [0|1] "" Vector__XXX
 SG_ PARK_sw051_sensorTemperature m51 : 16|16@1+ (0.1,-40) [-40|6513.5] "deg" Vector__XXX
 SG_ PARK_sw052_membraneDisconct m52 : 16|1@1+ (1,0) [0|1] "" Vector__XXX
 SG_ PARK_sw052_dampResistorFail m52 : 17|1@1+ (1,0) [0|1] "" Vector__XXX
 SG_ PARK_sw052_resonanceDrift m52 : 18|1@1+ (1,0) [0|1] "" Vector__XXX
 SG_ PARK_sw052_sensorCRC m52 : 19|1@1+ (1,0) [0|1] "" Vector__XXX
 SG_ PARK_sw052_recieveFailure m52 : 20|1@1+ (1,0) [0|1] "" Vector__XXX
 SG_ PARK_sw052_diagnosticTransferErr m52 : 21|1@1+ (1,0) [0|1] "" Vector__XXX
 SG_ PARK_sw053_linError m53 : 16|1@1+ (1,0) [0|1] "" Vector__XXX
 SG_ PARK_sw053_linBusError m53 : 17|1@1+ (1,0) [0|1] "" Vector__XXX
 SG_ PARK_sw053_linFrameCountError m53 : 18|1@1+ (1,0) [0|1] "" Vector__XXX
 SG_ PARK_sw054_reverbPeriod m54 : 16|16@1+ (1,0) [0|65535] "microseconds" Vector__XXX
 SG_ PARK_sw054_reverbTime m54 : 32|16@1+ (1,0) [0|65535] "microseconds" Vector__XXX
 SG_ PARK_sw054_highAttenTime m54 : 48|1@1+ (1,0) [0|1] "" Vector__XXX
 SG_ PARK_sw054_closeConstEcho m54 : 49|1@1+ (1,0) [0|1] "" Vector__XXX
 SG_ PARK_sw054_lowAttenTime m54 : 50|1@1+ (1,0) [0|1] "" Vector__XXX
 SG_ PARK_sw054_attenTimeJitter m54 : 51|1@1+ (1,0) [0|1] "" Vector__XXX
 SG_ PARK_sw054_reverbFreqJitter m54 : 52|1@1+ (1,0) [0|1] "" Vector__XXX
 SG_ PARK_sw056_sensorTemperature m56 : 16|16@1+ (0.1,-40) [-40|6513.5] "deg" Vector__XXX
 SG_ PARK_sw057_membraneDisconct m57 : 16|1@1+ (1,0) [0|1] "" Vector__XXX
 SG_ PARK_sw057_dampResistorFail m57 : 17|1@1+ (1,0) [0|1] "" Vector__XXX
 SG_ PARK_sw057_resonanceDrift m57 : 18|1@1+ (1,0) [0|1] "" Vector__XXX
 SG_ PARK_sw057_sensorCRC m57 : 19|1@1+ (1,0) [0|1] "" Vector__XXX
 SG_ PARK_sw057_recieveFailure m57 : 20|1@1+ (1,0) [0|1] "" Vector__XXX
 SG_ PARK_sw057_diagnosticTransferErr m57 : 21|1@1+ (1,0) [0|1] "" Vector__XXX
 SG_ PARK_sw058_linError m58 : 16|1@1+ (1,0) [0|1] "" Vector__XXX
 SG_ PARK_sw058_linBusError m58 : 17|1@1+ (1,0) [0|1] "" Vector__XXX
 SG_ PARK_sw058_linFrameCountError m58 : 18|1@1+ (1,0) [0|1] "" Vector__XXX
 SG_ PARK_sw059_reverbPeriod m59 : 16|16@1+ (1,0) [0|65535] "microseconds" Vector__XXX
 SG_ PARK_sw059_reverbTime m59 : 32|16@1+ (1,0) [0|65535] "microseconds" Vector__XXX
 SG_ PARK_sw059_highAttenTime m59 : 48|1@1+ (1,0) [0|1] "" Vector__XXX
 SG_ PARK_sw059_closeConstEcho m59 : 49|1@1+ (1,0) [0|1] "" Vector__XXX
 SG_ PARK_sw059_lowAttenTime m59 : 50|1@1+ (1,0) [0|1] "" Vector__XXX
 SG_ PARK_sw059_attenTimeJitter m59 : 51|1@1+ (1,0) [0|1] "" Vector__XXX
 SG_ PARK_sw059_reverbFreqJitter m59 : 52|1@1+ (1,0) [0|1] "" Vector__XXX
 SG_ PARK_sw061_voltage m61 : 16|16@1+ (0.1,0) [0|6553.5] "volts" Vector__XXX
 SG_ PARK_sw063_voltage m63 : 16|16@1+ (0.1,0) [0|6553.5] "volts" Vector__XXX
 SG_ PARK_sw064_faultCode m64 : 16|8@1+ (1,0) [0|255] "" Vector__XXX
 SG_ PARK_sw065_expectedCRC m65 : 16|16@1+ (1,0) [0|65535] "" Vector__XXX
 SG_ PARK_sw065_calculatedCRC m65 : 32|16@1+ (1,0) [0|65535] "" Vector__XXX
 SG_ PARK_sw066_placeHolder m66 : 16|1@1+ (1,0) [0|1] "" Vector__XXX
 SG_ PARK_sw068_placeHolder m68 : 16|1@1+ (1,0) [0|1] "" Vector__XXX
 SG_ PARK_sw069_messageID m69 : 16|16@1+ (1,0) [0|65535] "" Vector__XXX
 SG_ PARK_sw070_messageID m70 : 16|16@1+ (1,0) [0|65535] "" Vector__XXX
 SG_ PARK_sw071_messageID m71 : 16|16@1+ (1,0) [0|65535] "" Vector__XXX
 SG_ PARK_sw072_messageID m72 : 16|16@1+ (1,0) [0|65535] "" Vector__XXX
 SG_ PARK_sw073_messageID m73 : 16|16@1+ (1,0) [0|65535] "" Vector__XXX
 SG_ PARK_sw074_messageID m74 : 16|16@1+ (1,0) [0|65535] "" Vector__XXX
 SG_ PARK_sw075_messageID m75 : 16|16@1+ (1,0) [0|65535] "" Vector__XXX
 SG_ PARK_sw076_messageID m76 : 16|16@1+ (1,0) [0|65535] "" Vector__XXX
 SG_ PARK_sw077_errorExp m77 : 16|8@1+ (1,0) [0|255] "" Vector__XXX
 SG_ PARK_sw077_errorRx m77 : 24|8@1+ (1,0) [0|255] "" Vector__XXX
 SG_ PARK_sw077_messageID m77 : 32|12@1+ (1,0) [0|4095] "" Vector__XXX
 SG_ PARK_sw077_errorType m77 : 44|3@1+ (1,0) [0|7] "" Vector__XXX
 SG_ PARK_sw078_errorExp m78 : 16|8@1+ (1,0) [0|255] "" Vector__XXX
 SG_ PARK_sw078_errorRx m78 : 24|8@1+ (1,0) [0|255] "" Vector__XXX
 SG_ PARK_sw078_messageID m78 : 32|12@1+ (1,0) [0|4095] "" Vector__XXX
 SG_ PARK_sw078_errorType m78 : 44|3@1+ (1,0) [0|7] "" Vector__XXX
 SG_ PARK_sw079_errorExp m79 : 16|8@1+ (1,0) [0|255] "" Vector__XXX
 SG_ PARK_sw079_errorRx m79 : 24|8@1+ (1,0) [0|255] "" Vector__XXX
 SG_ PARK_sw079_messageID m79 : 32|12@1+ (1,0) [0|4095] "" Vector__XXX
 SG_ PARK_sw079_errorType m79 : 44|3@1+ (1,0) [0|7] "" Vector__XXX
 SG_ PARK_sw080_errorExp m80 : 16|8@1+ (1,0) [0|255] "" Vector__XXX
 SG_ PARK_sw080_errorRx m80 : 24|8@1+ (1,0) [0|255] "" Vector__XXX
 SG_ PARK_sw080_messageID m80 : 32|12@1+ (1,0) [0|4095] "" Vector__XXX
 SG_ PARK_sw080_errorType m80 : 44|3@1+ (1,0) [0|7] "" Vector__XXX
 SG_ PARK_sw081_errorExp m81 : 16|8@1+ (1,0) [0|255] "" Vector__XXX
 SG_ PARK_sw081_errorRx m81 : 24|8@1+ (1,0) [0|255] "" Vector__XXX
 SG_ PARK_sw081_messageID m81 : 32|12@1+ (1,0) [0|4095] "" Vector__XXX
 SG_ PARK_sw081_errorType m81 : 44|3@1+ (1,0) [0|7] "" Vector__XXX
 SG_ PARK_sw082_errorExp m82 : 16|8@1+ (1,0) [0|255] "" Vector__XXX
 SG_ PARK_sw082_errorRx m82 : 24|8@1+ (1,0) [0|255] "" Vector__XXX
 SG_ PARK_sw082_messageID m82 : 32|12@1+ (1,0) [0|4095] "" Vector__XXX
 SG_ PARK_sw082_errorType m82 : 44|3@1+ (1,0) [0|7] "" Vector__XXX
 SG_ PARK_sw083_errorExp m83 : 16|8@1+ (1,0) [0|255] "" Vector__XXX
 SG_ PARK_sw083_errorRx m83 : 24|8@1+ (1,0) [0|255] "" Vector__XXX
 SG_ PARK_sw083_messageID m83 : 32|12@1+ (1,0) [0|4095] "" Vector__XXX
 SG_ PARK_sw083_errorType m83 : 44|3@1+ (1,0) [0|7] "" Vector__XXX
 SG_ PARK_sw084_errorExp m84 : 16|8@1+ (1,0) [0|255] "" Vector__XXX
 SG_ PARK_sw084_errorRx m84 : 24|8@1+ (1,0) [0|255] "" Vector__XXX
 SG_ PARK_sw084_messageID m84 : 32|12@1+ (1,0) [0|4095] "" Vector__XXX
 SG_ PARK_sw084_errorType m84 : 44|3@1+ (1,0) [0|7] "" Vector__XXX
 SG_ PARK_sw086_writeRetryCounter m86 : 16|8@1+ (1,0) [0|255] "" Vector__XXX
 SG_ PARK_sw086_readRetryCounter m86 : 24|8@1+ (1,0) [0|255] "" Vector__XXX
 SG_ PARK_sw086_currentErrorCode m86 : 32|8@1+ (1,0) [0|255] "" Vector__XXX
 SG_ PARK_sw087_s1_sensorType m87 : 16|2@1+ (1,0) [0|2] "" Vector__XXX
 SG_ PARK_sw087_s2_sensorType m87 : 18|2@1+ (1,0) [0|2] "" Vector__XXX
 SG_ PARK_sw087_s3_sensorType m87 : 20|2@1+ (1,0) [0|2] "" Vector__XXX
 SG_ PARK_sw087_s4_sensorType m87 : 22|2@1+ (1,0) [0|2] "" Vector__XXX
 SG_ PARK_sw087_s5_sensorType m87 : 24|2@1+ (1,0) [0|2] "" Vector__XXX
 SG_ PARK_sw087_s6_sensorType m87 : 26|2@1+ (1,0) [0|2] "" Vector__XXX
 SG_ PARK_sw087_s7_sensorType m87 : 28|2@1+ (1,0) [0|2] "" Vector__XXX
 SG_ PARK_sw087_s8_sensorType m87 : 30|2@1+ (1,0) [0|2] "" Vector__XXX
 SG_ PARK_sw087_s9_sensorType m87 : 32|2@1+ (1,0) [0|2] "" Vector__XXX
 SG_ PARK_sw087_s10_sensorType m87 : 34|2@1+ (1,0) [0|2] "" Vector__XXX
 SG_ PARK_sw087_s11_sensorType m87 : 36|2@1+ (1,0) [0|2] "" Vector__XXX
 SG_ PARK_sw087_s12_sensorType m87 : 38|2@1+ (1,0) [0|2] "" Vector__XXX

BO_ 806 PARK_info: 8 PARK
 SG_ PARK_infoIndex M : 0|8@1+ (1,0) [0|255] "" Vector__XXX
 SG_ PARK_infoBuildType m10 : 8|8@1+ (1,0) [0|255] "" Vector__XXX
 SG_ PARK_infoComponentID m10 : 48|16@1+ (1,0) [0|65535] "" Vector__XXX
 SG_ PARK_infoPcbaID m11 : 16|8@1+ (1,0) [0|255] "" Vector__XXX
 SG_ PARK_infoAssemblyID m11 : 24|8@1+ (1,0) [0|255] "" Vector__XXX
 SG_ PARK_infoUsageID m11 : 32|16@1+ (1,0) [0|65535] "" Vector__XXX
 SG_ PARK_infoApplicationCRC m13 : 32|32@1+ (1,0) [0|4294967295] "" Vector__XXX
 SG_ PARK_infoBootUdsProtoVersion m20 : 8|8@1+ (1,0) [0|255] "" Vector__XXX
 SG_ PARK_infoBootloaderCRC m20 : 32|32@1+ (1,0) [0|4294967295] "" Vector__XXX

BO_ 846 PARK_pasFrontMiddle: 5 PARK
 SG_ PARK_frontLeftMiddleRawDistData : 0|8@1+ (1,0) [0|254] "cm" Vector__XXX
 SG_ PARK_frontMiddleRawDistData : 8|8@1+ (1,0) [0|254] "cm" Vector__XXX
 SG_ PARK_frontRightMiddleRawDistData : 16|8@1+ (1,0) [0|254] "cm" Vector__XXX
 SG_ PARK_pasFrontMiddleCounter : 24|4@1+ (1,0) [0|15] "" Vector__XXX
 SG_ PARK_pasFrontMiddleChecksum : 32|8@1+ (1,0) [0|255] "" Vector__XXX

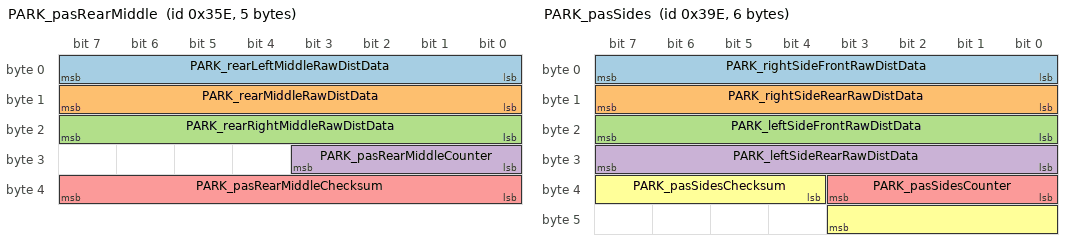
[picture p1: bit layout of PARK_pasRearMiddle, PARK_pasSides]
BO_ 862 PARK_pasRearMiddle: 5 PARK
 SG_ PARK_rearLeftMiddleRawDistData : 0|8@1+ (1,0) [0|254] "cm" Vector__XXX
 SG_ PARK_rearMiddleRawDistData : 8|8@1+ (1,0) [0|254] "cm" Vector__XXX
 SG_ PARK_rearRightMiddleRawDistData : 16|8@1+ (1,0) [0|254] "cm" Vector__XXX
 SG_ PARK_pasRearMiddleCounter : 24|4@1+ (1,0) [0|15] "" Vector__XXX
 SG_ PARK_pasRearMiddleChecksum : 32|8@1+ (1,0) [0|255] "" Vector__XXX

BO_ 926 PARK_pasSides: 6 PARK
 SG_ PARK_rightSideFrontRawDistData : 0|8@1+ (1,0) [0|254] "cm" Vector__XXX
 SG_ PARK_rightSideRearRawDistData : 8|8@1+ (1,0) [0|254] "cm" Vector__XXX
 SG_ PARK_leftSideFrontRawDistData : 16|8@1+ (1,0) [0|254] "cm" Vector__XXX
 SG_ PARK_leftSideRearRawDistData : 24|8@1+ (1,0) [0|254] "cm" Vector__XXX
 SG_ PARK_pasSidesCounter : 32|4@1+ (1,0) [0|15] "" Vector__XXX
 SG_ PARK_pasSidesChecksum : 36|8@1+ (1,0) [0|255] "" Vector__XXX

BO_ 606 PARK_pscEnvSlot: 8 PARK
 SG_ PARK_pscEnvSlotType M : 0|2@1+ (1,0) [0|3] "" Vector__XXX
 SG_ PARK_pscLeftParallelObj1X m0 : 3|11@1+ (2,-2048) [-2048|2044] "cm" Vector__XXX
 SG_ PARK_pscLeftParallelObj1Y m0 : 14|11@1+ (2,-2048) [-2048|2044] "cm" Vector__XXX
 SG_ PARK_pscLeftParallelObj1Alpha m0 : 25|7@1+ (2,-128) [-128|124] "deg" Vector__XXX
 SG_ PARK_pscLeftParallelObj2Y m0 : 35|11@1+ (2,-2048) [-2048|2044] "cm" Vector__XXX
 SG_ PARK_pscLeftParallelObj2X m0 : 46|11@1+ (2,-2048) [-2048|2044] "cm" Vector__XXX
 SG_ PARK_pscLeftParallelObj2Alpha m0 : 57|7@1+ (2,-128) [-128|124] "deg" Vector__XXX
 SG_ PARK_pscLeftCrossObj1X m1 : 3|11@1+ (2,-2048) [-2048|2044] "cm" Vector__XXX
 SG_ PARK_pscLeftCrossObj1Y m1 : 14|11@1+ (2,-2048) [-2048|2044] "cm" Vector__XXX
 SG_ PARK_pscLeftCrossObj1Alpha m1 : 25|7@1+ (2,-128) [-128|124] "deg" Vector__XXX
 SG_ PARK_pscLeftCrossObj2Y m1 : 35|11@1+ (2,-2048) [-2048|2044] "cm" Vector__XXX
 SG_ PARK_pscLeftCrossObj2X m1 : 46|11@1+ (2,-2048) [-2048|2044] "cm" Vector__XXX
 SG_ PARK_pscLeftCrossObj2Alpha m1 : 57|7@1+ (2,-128) [-128|124] "deg" Vector__XXX
 SG_ PARK_pscRightParallelObj1X m2 : 3|11@1+ (2,-2048) [-2048|2044] "cm" Vector__XXX
 SG_ PARK_pscRightParallelObj1Y m2 : 14|11@1+ (2,-2048) [-2048|2044] "cm" Vector__XXX
 SG_ PARK_pscRightParallelObj1Alpha m2 : 25|7@1+ (2,-128) [-128|124] "deg" Vector__XXX
 SG_ PARK_pscRightParallelObj2Y m2 : 35|11@1+ (2,-2048) [-2048|2044] "cm" Vector__XXX
 SG_ PARK_pscRightParallelObj2X m2 : 46|11@1+ (2,-2048) [-2048|2044] "cm" Vector__XXX
 SG_ PARK_pscRightParallelObj2Alpha m2 : 57|7@1+ (2,-128) [-128|124] "deg" Vector__XXX
 SG_ PARK_pscRightCrossObj1X m3 : 3|11@1+ (2,-2048) [-2048|2044] "cm" Vector__XXX
 SG_ PARK_pscRightCrossObj1Y m3 : 14|11@1+ (2,-2048) [-2048|2044] "cm" Vector__XXX
 SG_ PARK_pscRightCrossObj1Alpha m3 : 25|7@1+ (2,-128) [-128|124] "deg" Vector__XXX
 SG_ PARK_pscRightCrossObj2Y m3 : 35|11@1+ (2,-2048) [-2048|2044] "cm" Vector__XXX
 SG_ PARK_pscRightCrossObj2X m3 : 46|11@1+ (2,-2048) [-2048|2044] "cm" Vector__XXX
 SG_ PARK_pscRightCrossObj2Alpha m3 : 57|7@1+ (2,-128) [-128|124] "deg" Vector__XXX

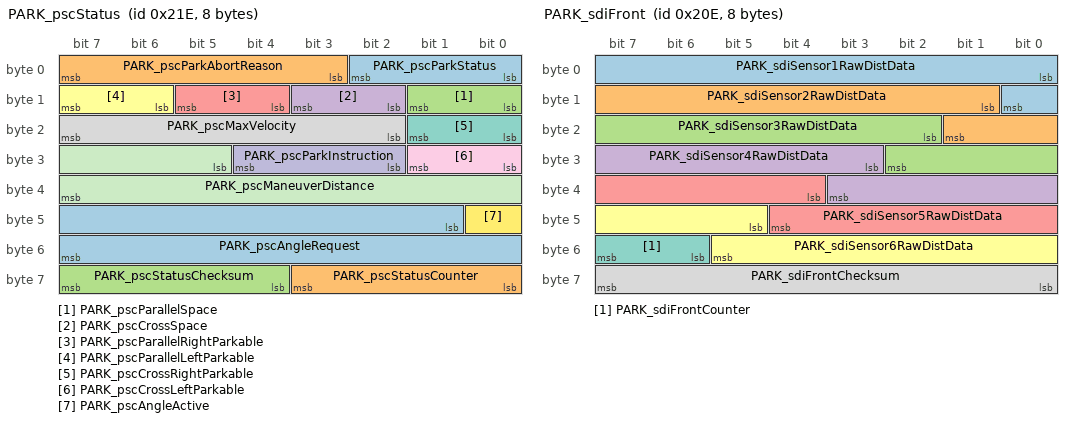
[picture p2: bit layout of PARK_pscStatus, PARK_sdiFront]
BO_ 542 PARK_pscStatus: 8 PARK
 SG_ PARK_pscParkStatus : 0|3@1+ (1,0) [0|6] "" Vector__XXX
 SG_ PARK_pscParkAbortReason : 3|5@1+ (1,0) [0|30] "" Vector__XXX
 SG_ PARK_pscParallelSpace : 8|2@1+ (1,0) [0|3] "" Vector__XXX
 SG_ PARK_pscCrossSpace : 10|2@1+ (1,0) [0|3] "" Vector__XXX
 SG_ PARK_pscParallelRightParkable : 12|2@1+ (1,0) [0|2] "" Vector__XXX
 SG_ PARK_pscParallelLeftParkable : 14|2@1+ (1,0) [0|2] "" Vector__XXX
 SG_ PARK_pscCrossRightParkable : 16|2@1+ (1,0) [0|2] "" Vector__XXX
 SG_ PARK_pscMaxVelocity : 18|6@1+ (0.1,0) [0|6.2] "kph" Vector__XXX
 SG_ PARK_pscCrossLeftParkable : 24|2@1+ (1,0) [0|2] "" Vector__XXX
 SG_ PARK_pscParkInstruction : 26|3@1+ (1,0) [0|6] "" Vector__XXX
 SG_ PARK_pscManeuverDistance : 29|11@1+ (1,0) [0|2046] "cm" Vector__XXX
 SG_ PARK_pscAngleActive : 40|1@1+ (1,0) [0|1] "" Vector__XXX
 SG_ PARK_pscAngleRequest : 41|15@1+ (0.1,-1638.4) [-1638.4|1638.3] "deg" Vector__XXX
 SG_ PARK_pscStatusCounter : 56|4@1+ (1,0) [0|15] "" Vector__XXX
 SG_ PARK_pscStatusChecksum : 60|4@1+ (1,0) [0|15] "" Vector__XXX

BO_ 590 PARK_pscVehSlot: 8 PARK
 SG_ PARK_pscVehSlotType M : 0|2@1+ (1,0) [0|3] "" Vector__XXX
 SG_ PARK_pscLeftParallelVehX m0 : 5|11@1+ (2,-2048) [-2048|2044] "cm" Vector__XXX
 SG_ PARK_pscLeftParallelVehY m0 : 16|11@1+ (2,-2048) [-2048|2044] "cm" Vector__XXX
 SG_ PARK_pscLeftParallelPsi m0 : 32|13@1+ (0.0009765625,0) [0|7.998046875] "radians" Vector__XXX
 SG_ PARK_pscLeftParallelSizeX m0 : 48|8@1+ (4,0) [0|1016] "cm" Vector__XXX
 SG_ PARK_pscLeftParallelSizeY m0 : 56|8@1+ (4,0) [0|1016] "cm" Vector__XXX
 SG_ PARK_pscLeftCrossVehX m1 : 5|11@1+ (2,-2048) [-2048|2044] "cm" Vector__XXX
 SG_ PARK_pscLeftCrossVehY m1 : 16|11@1+ (2,-2048) [-2048|2044] "cm" Vector__XXX
 SG_ PARK_pscLeftCrossPsi m1 : 32|13@1+ (0.0009765625,0) [0|7.998046875] "radians" Vector__XXX
 SG_ PARK_pscLeftCrossSizeX m1 : 48|8@1+ (4,0) [0|1016] "cm" Vector__XXX
 SG_ PARK_pscLeftCrossSizeY m1 : 56|8@1+ (4,0) [0|1016] "cm" Vector__XXX
 SG_ PARK_pscRightParallelVehX m2 : 5|11@1+ (2,-2048) [-2048|2044] "cm" Vector__XXX
 SG_ PARK_pscRightParallelVehY m2 : 16|11@1+ (2,-2048) [-2048|2044] "cm" Vector__XXX
 SG_ PARK_pscRightParallelPsi m2 : 32|13@1+ (0.0009765625,0) [0|7.998046875] "radians" Vector__XXX
 SG_ PARK_pscRightParallelSizeX m2 : 48|8@1+ (4,0) [0|1016] "cm" Vector__XXX
 SG_ PARK_pscRightParallelSizeY m2 : 56|8@1+ (4,0) [0|1016] "cm" Vector__XXX
 SG_ PARK_pscRightCrossVehX m3 : 5|11@1+ (2,-2048) [-2048|2044] "cm" Vector__XXX
 SG_ PARK_pscRightCrossVehY m3 : 16|11@1+ (2,-2048) [-2048|2044] "cm" Vector__XXX
 SG_ PARK_pscRightCrossPsi m3 : 32|13@1+ (0.0009765625,0) [0|7.998046875] "radians" Vector__XXX
 SG_ PARK_pscRightCrossSizeX m3 : 48|8@1+ (4,0) [0|1016] "cm" Vector__XXX
 SG_ PARK_pscRightCrossSizeY m3 : 56|8@1+ (4,0) [0|1016] "cm" Vector__XXX

BO_ 526 PARK_sdiFront: 8 PARK
 SG_ PARK_sdiSensor1RawDistData : 0|9@1+ (1,0) [0|510] "cm" Vector__XXX
 SG_ PARK_sdiSensor2RawDistData : 9|9@1+ (1,0) [0|510] "cm" Vector__XXX
 SG_ PARK_sdiSensor3RawDistData : 18|9@1+ (1,0) [0|510] "cm" Vector__XXX
 SG_ PARK_sdiSensor4RawDistData : 27|9@1+ (1,0) [0|510] "cm" Vector__XXX
 SG_ PARK_sdiSensor5RawDistData : 36|9@1+ (1,0) [0|510] "cm" Vector__XXX
 SG_ PARK_sdiSensor6RawDistData : 45|9@1+ (1,0) [0|510] "cm" Vector__XXX
 SG_ PARK_sdiFrontCounter : 54|2@1+ (1,0) [0|3] "" Vector__XXX
 SG_ PARK_sdiFrontChecksum : 56|8@1+ (1,0) [0|255] "" Vector__XXX

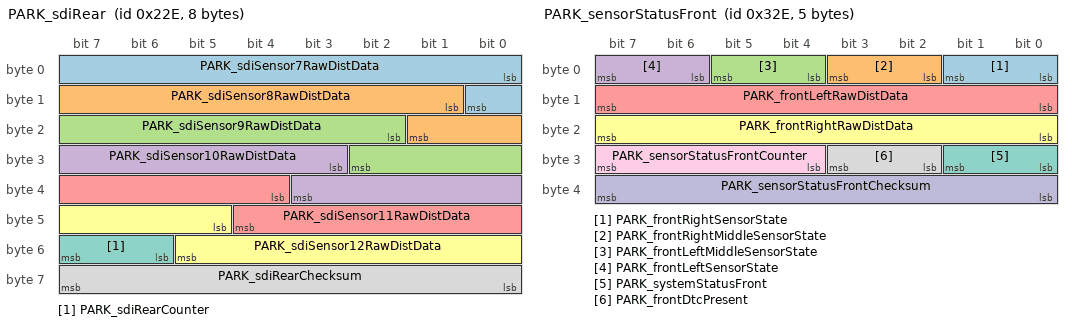
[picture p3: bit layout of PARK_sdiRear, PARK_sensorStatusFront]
BO_ 558 PARK_sdiRear: 8 PARK
 SG_ PARK_sdiSensor7RawDistData : 0|9@1+ (1,0) [0|510] "cm" Vector__XXX
 SG_ PARK_sdiSensor8RawDistData : 9|9@1+ (1,0) [0|510] "cm" Vector__XXX
 SG_ PARK_sdiSensor9RawDistData : 18|9@1+ (1,0) [0|510] "cm" Vector__XXX
 SG_ PARK_sdiSensor10RawDistData : 27|9@1+ (1,0) [0|510] "cm" Vector__XXX
 SG_ PARK_sdiSensor11RawDistData : 36|9@1+ (1,0) [0|510] "cm" Vector__XXX
 SG_ PARK_sdiSensor12RawDistData : 45|9@1+ (1,0) [0|510] "cm" Vector__XXX
 SG_ PARK_sdiRearCounter : 54|2@1+ (1,0) [0|3] "" Vector__XXX
 SG_ PARK_sdiRearChecksum : 56|8@1+ (1,0) [0|255] "" Vector__XXX

BO_ 814 PARK_sensorStatusFront: 5 PARK
 SG_ PARK_frontRightSensorState : 0|2@1+ (1,0) [0|2] "" Vector__XXX
 SG_ PARK_frontRightMiddleSensorState : 2|2@1+ (1,0) [0|2] "" Vector__XXX
 SG_ PARK_frontLeftMiddleSensorState : 4|2@1+ (1,0) [0|2] "" Vector__XXX
 SG_ PARK_frontLeftSensorState : 6|2@1+ (1,0) [0|2] "" Vector__XXX
 SG_ PARK_frontLeftRawDistData : 8|8@1+ (1,0) [0|254] "cm" Vector__XXX
 SG_ PARK_frontRightRawDistData : 16|8@1+ (1,0) [0|254] "cm" Vector__XXX
 SG_ PARK_systemStatusFront : 24|2@1+ (1,0) [0|2] "" Vector__XXX
 SG_ PARK_frontDtcPresent : 26|2@1+ (1,0) [0|2] "" Vector__XXX
 SG_ PARK_sensorStatusFrontCounter : 28|4@1+ (1,0) [0|15] "" Vector__XXX
 SG_ PARK_sensorStatusFrontChecksum : 32|8@1+ (1,0) [0|255] "" Vector__XXX

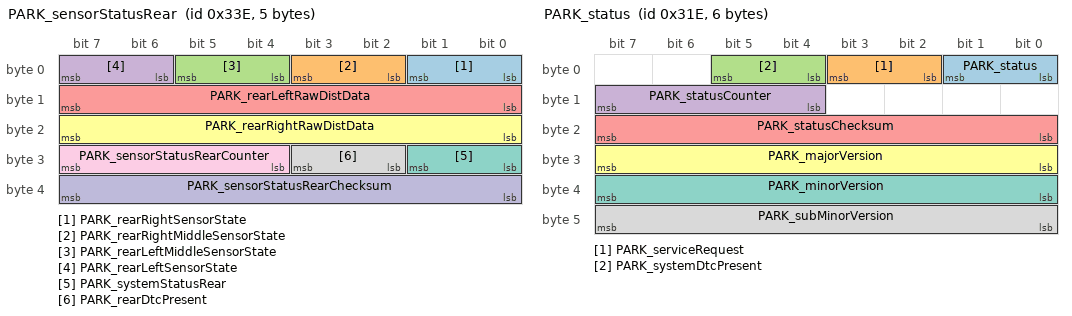
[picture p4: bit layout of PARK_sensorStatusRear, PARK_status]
BO_ 830 PARK_sensorStatusRear: 5 PARK
 SG_ PARK_rearRightSensorState : 0|2@1+ (1,0) [0|2] "" Vector__XXX
 SG_ PARK_rearRightMiddleSensorState : 2|2@1+ (1,0) [0|2] "" Vector__XXX
 SG_ PARK_rearLeftMiddleSensorState : 4|2@1+ (1,0) [0|2] "" Vector__XXX
 SG_ PARK_rearLeftSensorState : 6|2@1+ (1,0) [0|2] "" Vector__XXX
 SG_ PARK_rearLeftRawDistData : 8|8@1+ (1,0) [0|254] "cm" Vector__XXX
 SG_ PARK_rearRightRawDistData : 16|8@1+ (1,0) [0|254] "cm" Vector__XXX
 SG_ PARK_systemStatusRear : 24|2@1+ (1,0) [0|2] "" Vector__XXX
 SG_ PARK_rearDtcPresent : 26|2@1+ (1,0) [0|2] "" Vector__XXX
 SG_ PARK_sensorStatusRearCounter : 28|4@1+ (1,0) [0|15] "" Vector__XXX
 SG_ PARK_sensorStatusRearChecksum : 32|8@1+ (1,0) [0|255] "" Vector__XXX

BO_ 798 PARK_status: 6 PARK
 SG_ PARK_status : 0|2@1+ (1,0) [0|2] "" Vector__XXX
 SG_ PARK_serviceRequest : 2|2@1+ (1,0) [0|2] "" Vector__XXX
 SG_ PARK_systemDtcPresent : 4|2@1+ (1,0) [0|2] "" Vector__XXX
 SG_ PARK_statusCounter : 12|4@1+ (1,0) [0|15] "" Vector__XXX
 SG_ PARK_statusChecksum : 16|8@1+ (1,0) [0|255] "" Vector__XXX
 SG_ PARK_majorVersion : 24|8@1+ (1,0) [0|254] "" Vector__XXX
 SG_ PARK_minorVersion : 32|8@1+ (1,0) [0|254] "" Vector__XXX
 SG_ PARK_subMinorVersion : 40|8@1+ (1,0) [0|254] "" Vector__XXX

BO_TX_BU_ 841 : DAS;
BO_TX_BU_ 1082 : DAS;
BO_TX_BU_ 977 : EPAS3S;
BO_TX_BU_ 785 : EPAS3S;
BO_TX_BU_ 920 : EPASTS;
BO_TX_BU_ 805 : ESP;
BO_TX_BU_ 813 : IBST;
BO_TX_BU_ 828 : IDB;
BO_TX_BU_ 1486 : PARK;
BO_TX_BU_ 806 : PARK;
BO_TX_BU_ 846 : PARK;
BO_TX_BU_ 862 : PARK;
BO_TX_BU_ 926 : PARK;
BO_TX_BU_ 606 : PARK;
BO_TX_BU_ 542 : PARK;
BO_TX_BU_ 590 : PARK;
BO_TX_BU_ 526 : PARK;
BO_TX_BU_ 558 : PARK;
BO_TX_BU_ 814 : PARK;
BO_TX_BU_ 830 : PARK;
BO_TX_BU_ 798 : PARK;
CM_ BO_ 841 "Driver assistance computer message: warning matrix2; frame length from the layout, not yet observed on a vehicle bus";
CM_ SG_ 841 DAS_w129_mainCamExtNotCal "Driver assistance computer: w129 main cam ext not cal";
CM_ SG_ 841 DAS_w130_narrowCamExtNotCal "Driver assistance computer: w130 narrow cam ext not cal";
CM_ SG_ 841 DAS_w131_mainCamCalSaved "Driver assistance computer: w131 main cam cal saved";
CM_ SG_ 841 DAS_w132_narrowCamCalSaved "Driver assistance computer: w132 narrow cam cal saved";
CM_ SG_ 841 DAS_w133_mainCamInitFault "Driver assistance computer: w133 main cam init fault";
CM_ SG_ 841 DAS_w134_narrowCamInitFault "Driver assistance computer: w134 narrow cam init fault";
CM_ SG_ 841 DAS_w135_fisheyeCamInitFault "Driver assistance computer: w135 fisheye cam init fault";
CM_ SG_ 841 DAS_w136_lPillarCamInitFault "Driver assistance computer: w136 l pillar cam init fault";
CM_ SG_ 841 DAS_w137_rPillarCamInitFault "Driver assistance computer: w137 r pillar cam init fault";
CM_ SG_ 841 DAS_w138_lRepeatCamInitFault "Driver assistance computer: w138 l repeat cam init fault";
CM_ SG_ 841 DAS_w139_rRepeatCamInitFault "Driver assistance computer: w139 r repeat cam init fault";
CM_ SG_ 841 DAS_w140_backupCamInitFault "Driver assistance computer: w140 backup cam init fault";
CM_ SG_ 841 DAS_w141_ECU_Thermal_Issue "Driver assistance computer: w141 ECU thermal issue";
CM_ SG_ 841 DAS_w142_fwdCamPitchProblem "Driver assistance computer: w142 fwd cam pitch problem";
CM_ SG_ 841 DAS_w143_IDF_event "Driver assistance computer: w143 IDF event";
CM_ SG_ 841 DAS_w144_selfieCamInitFault "Driver assistance computer: w144 selfie cam init fault";
CM_ SG_ 841 DAS_w171_fisheyeCamExtNotCal "Driver assistance computer: w171 fisheye cam ext not cal";
CM_ SG_ 841 DAS_w172_lPillarCamExtNotCal "Driver assistance computer: w172 l pillar cam ext not cal";
CM_ SG_ 841 DAS_w173_rPillarCamExtNotCal "Driver assistance computer: w173 r pillar cam ext not cal";
CM_ SG_ 841 DAS_w174_lRepeatCamExtNotCal "Driver assistance computer: w174 l repeat cam ext not cal";
CM_ SG_ 841 DAS_w175_rRepeatCamExtNotCal "Driver assistance computer: w175 r repeat cam ext not cal";
CM_ SG_ 841 DAS_w177_fisheyeCamCalSaved "Driver assistance computer: w177 fisheye cam cal saved";
CM_ SG_ 841 DAS_w178_lPillarCamCalSaved "Driver assistance computer: w178 l pillar cam cal saved";
CM_ SG_ 841 DAS_w179_rPillarCamCalSaved "Driver assistance computer: w179 r pillar cam cal saved";
CM_ SG_ 841 DAS_w180_lRepeatCamCalSaved "Driver assistance computer: w180 l repeat cam cal saved";
CM_ SG_ 841 DAS_w181_rRepeatCamCalSaved "Driver assistance computer: w181 r repeat cam cal saved";
CM_ BO_ 1082 "Driver assistance computer message: warning matrix3; frame length from the layout, not yet observed on a vehicle bus";
CM_ SG_ 1082 DAS_w193_camWindshieldUnclean "Driver assistance computer: w193 cam windshield unclean";
CM_ SG_ 1082 DAS_w194_accDriverResumeRqrd "Driver assistance computer: w194 acc driver resume rqrd";
CM_ SG_ 1082 DAS_w195_scwUnavailable "Driver assistance computer: w195 scw unavailable";
CM_ SG_ 1082 DAS_w196_stopSignWarning "Driver assistance computer: w196 stop sign warning";
CM_ SG_ 1082 DAS_w197_redLightWarning "Driver assistance computer: w197 red light warning";
CM_ SG_ 1082 DAS_w198_tsrUnavailable "Driver assistance computer: w198 tsr unavailable";
CM_ SG_ 1082 DAS_w199_apcAbort "Driver assistance computer: w199 apc abort";
CM_ SG_ 1082 DAS_w200_lcSlowdown "Driver assistance computer: w200 lc slowdown";
CM_ SG_ 1082 DAS_w201_lcAborting "Driver assistance computer: w201 lc aborting";
CM_ SG_ 1082 DAS_w202_scwNoisyEnvironment "Driver assistance computer: w202 scw noisy environment";
CM_ SG_ 1082 DAS_w203_apcActivation "Driver assistance computer: w203 apc activation";
CM_ SG_ 1082 DAS_w204_apcFinalFront "Driver assistance computer: w204 apc final front";
CM_ SG_ 1082 DAS_w205_apcFinalRear "Driver assistance computer: w205 apc final rear";
CM_ SG_ 1082 DAS_w206_autosteerNotEnabled "Driver assistance computer: w206 autosteer not enabled";
CM_ SG_ 1082 DAS_w207_autosteerUnavailable "Driver assistance computer: w207 autosteer unavailable";
CM_ SG_ 1082 DAS_w208_rackDetected "Driver assistance computer: w208 rack detected";
CM_ SG_ 1082 DAS_w209_autoSummonRequest "Driver assistance computer: w209 auto summon request";
CM_ SG_ 1082 DAS_w210_camObstrcted "Driver assistance computer: w210 cam obstrcted";
CM_ SG_ 1082 DAS_w211_accNoSeatBelt "Driver assistance computer: w211 acc no seat belt";
CM_ SG_ 1082 DAS_w212_lcUnavailableStrikeOut "Driver assistance computer: w212 lc unavailable strike out";
CM_ SG_ 1082 DAS_w213_autosteerStruckOut "Driver assistance computer: w213 autosteer struck out";
CM_ SG_ 1082 DAS_w214_driverNotIntracting "Driver assistance computer: w214 driver not intracting";
CM_ SG_ 1082 DAS_w215_contDriverNotIntracting "Driver assistance computer: w215 cont driver not intracting";
CM_ SG_ 1082 DAS_w216_driverOverriding "Driver assistance computer: w216 driver overriding";
CM_ SG_ 1082 DAS_w217_lcUnavailableSpeeding "Driver assistance computer: w217 lc unavailable speeding";
CM_ SG_ 1082 DAS_w218_lcSpeedExceededLimit "Driver assistance computer: w218 lc speed exceeded limit";
CM_ SG_ 1082 DAS_w219_lcTempUnavailableSpeed "Driver assistance computer: w219 lc temp unavailable speed";
CM_ SG_ 1082 DAS_w220_lcTempUnavailableRoad "Driver assistance computer: w220 lc temp unavailable road";
CM_ SG_ 1082 DAS_w221_accRadarBlind "Driver assistance computer: w221 acc radar blind";
CM_ SG_ 1082 DAS_w222_accCameraBlind "Driver assistance computer: w222 acc camera blind";
CM_ SG_ 1082 DAS_w223_accObjectInPath "Driver assistance computer: w223 acc object in path";
CM_ SG_ 1082 DAS_w224_accCameraCalibration "Driver assistance computer: w224 acc camera calibration";
CM_ SG_ 1082 DAS_w225_lcDegradedVisSpeedLmt "Driver assistance computer: w225 lc degraded vis speed lmt";
CM_ SG_ 1082 DAS_w226_lcCamCalNeededSpeedLmt "Driver assistance computer: w226 lc cam cal needed speed lmt";
CM_ SG_ 1082 DAS_w227_virtualWallBlocked "Driver assistance computer: w227 virtual wall blocked";
CM_ SG_ 1082 DAS_w228_DEPRECATED "Driver assistance computer: w228 DEPRECATED";
CM_ SG_ 1082 DAS_w229_alcUltrasoundDamaged "Driver assistance computer: w229 alc ultrasound damaged";
CM_ SG_ 1082 DAS_w230_alcUltrasoundBlocked "Driver assistance computer: w230 alc ultrasound blocked";
CM_ SG_ 1082 DAS_w231_idfEvent "Driver assistance computer: w231 idf event";
CM_ SG_ 1082 DAS_w232_laneChangeRequested "Driver assistance computer: w232 lane change requested";
CM_ BO_ 977 "Electric power steering (secondary) message: angle calibration; frame length from the layout, not yet observed on a vehicle bus";
CM_ SG_ 977 EPAS3S_appliedAngleOffset "This represents the angle delta between the absolute steering angle reference and what EPAS estimates to be straight ahead. The steering angle offset can change up to 5deg at the beginning of each drive cycle.";
CM_ SG_ 977 EPAS3S_calculatedAngleOffset "Reports the calculated steering angle offset learned between the Steering Column Control Module (SCCM) and the Electronic Power Assist Steering (EPAS) steering angle.";
CM_ SG_ 977 EPAS3S_resyncStatus "Electric power steering (secondary): resync status";
CM_ SG_ 977 EPAS3S_pullDriftLongTermTrq "The learned, long term pull drift or road crown compensation torque that the rack is applying to the steering wheel.";
CM_ SG_ 977 EPAS3S_pullDriftCompTrq "The current pull drift or road crown compensation torque that the rack is applying to the steering wheel.";
CM_ SG_ 977 EPAS3S_learnedSCCMOffset "Electric power steering (secondary): learned SCCM offset";
CM_ BO_ 785 "Electric power steering (secondary) message: info; frame length from the layout, not yet observed on a vehicle bus";
CM_ SG_ 785 EPAS3S_infoIndex "Electric power steering (secondary): info index";
CM_ SG_ 785 EPAS3S_infoBuildType "Electric power steering (secondary): info build type";
CM_ SG_ 785 EPAS3S_infoComponentID "Electric power steering (secondary): info component ID";
CM_ SG_ 785 EPAS3S_infoPcbaID "Electric power steering (secondary): info pcba ID";
CM_ SG_ 785 EPAS3S_infoAssemblyID "Electric power steering (secondary): info assembly ID";
CM_ SG_ 785 EPAS3S_infoUsageID "Electric power steering (secondary): info usage ID";
CM_ SG_ 785 EPAS3S_infoApplicationCRC "Electric power steering (secondary): info application CRC";
CM_ SG_ 785 EPAS3S_infoBootUdsProtoVersion "Electric power steering (secondary): info boot uds proto version";
CM_ SG_ 785 EPAS3S_infoBootloaderCRC "Electric power steering (secondary): info bootloader CRC";
CM_ SG_ 785 EPAS3S_infoSubcomponent2 "Electric power steering (secondary): info subcomponent2";
CM_ BO_ 920 "EPASTS ECU message: alert matrix; frame length from the layout, not yet observed on a vehicle bus";
CM_ SG_ 920 EPASTS_matrixIndex "EPASTS ECU: matrix index";
CM_ SG_ 920 EPASTS_a001_adcCalibrationOrInit "EPASTS ECU: a001 adc calibration or init fail";
CM_ SG_ 920 EPASTS_a002_adcMuxErr "EPASTS ECU: a002 adc mux err";
CM_ SG_ 920 EPASTS_a003_pspInvalidParamset "EPASTS ECU: a003 psp invalid paramset";
CM_ SG_ 920 EPASTS_a004_scpInputMia "EPASTS ECU: a004 scp input mia";
CM_ SG_ 920 EPASTS_a005_scpUnknownResetSourc "EPASTS ECU: a005 scp unknown reset source";
CM_ SG_ 920 EPASTS_a006_swrhResetByInvalidEr "EPASTS ECU: a006 swrh reset by invalid errid";
CM_ SG_ 920 EPASTS_a007_tsmcCoreTempDiff "EPASTS ECU: a007 tsmc core temp diff";
CM_ SG_ 920 EPASTS_a008_psdcPlatformShutdown "EPASTS ECU: a008 psdc platform shutdown";
CM_ SG_ 920 EPASTS_a009_mcusscLbistPermanent "EPASTS ECU: a009 mcussc lbist permanent fail";
CM_ SG_ 920 EPASTS_a010_svcIncompatibleSwVer "EPASTS ECU: a010 svc incompatible sw versions";
CM_ SG_ 920 EPASTS_a011_mcusscMonbistErr "EPASTS ECU: a011 mcussc monbist err";
CM_ SG_ 920 EPASTS_a012_mcusscMbistEccErr "EPASTS ECU: a012 mcussc mbist ecc err";
CM_ SG_ 920 EPASTS_a013_mcusscSffMonitoringF "EPASTS ECU: a013 mcussc sff monitoring failed";
CM_ SG_ 920 EPASTS_a014_mcusscSffMonitoringM "EPASTS ECU: a014 mcussc sff monitoring mia";
CM_ SG_ 920 EPASTS_a015_mcusscCsErrorCheckFa "EPASTS ECU: a015 mcussc cs error check fail";
CM_ SG_ 920 EPASTS_a016_mcufcCsErrorCheckFai "EPASTS ECU: a016 mcufc cs error check fail";
CM_ SG_ 920 EPASTS_a017_stmdStmPlausibilityC "EPASTS ECU: a017 stmd stm plausibility check err";
CM_ SG_ 920 EPASTS_a018_exchCsErrorCheck "EPASTS ECU: a018 exch cs error check";
CM_ SG_ 920 EPASTS_a019_rsthHwResetInfoCorru "EPASTS ECU: a019 rsth hw reset info corruption check";
CM_ SG_ 920 EPASTS_a020_mcusscEolEcuIdIntegr "EPASTS ECU: a020 mcussc eol ecu id integritiy fail";
CM_ SG_ 920 EPASTS_a021_osehCsErrorCheck "EPASTS ECU: a021 oseh cs error check";
CM_ SG_ 920 EPASTS_a022_swrhSwResetInfoCorru "EPASTS ECU: a022 swrh sw reset info corruption check";
CM_ SG_ 920 EPASTS_a023_btarcCorruptionCheck "EPASTS ECU: a023 btarc corruption check";
CM_ SG_ 920 EPASTS_a024_srhCsErrorCheckFail "EPASTS ECU: a024 srh cs error check fail";
CM_ SG_ 920 EPASTS_a025_btarcCorruptionCheck "EPASTS ECU: a025 btarc corruption check";
CM_ SG_ 920 EPASTS_a026_mrccCsErrorCheckFail "EPASTS ECU: a026 mrcc cs error check fail";
CM_ SG_ 920 EPASTS_a027_mcusscDmuHfErr "EPASTS ECU: a027 mcussc dmu hf err";
CM_ SG_ 920 EPASTS_a028_smuhNonInitDataCorru "EPASTS ECU: a028 smuh non init data corruption";
CM_ SG_ 920 EPASTS_a029_smuhSmuCoreCntErrorT "EPASTS ECU: a029 smuh smu core cnt error test fail";
CM_ SG_ 920 EPASTS_a030_rsthClockReset "EPASTS ECU: a030 rsth clock reset";
CM_ SG_ 920 EPASTS_a031_pmsProductionModeFai "EPASTS ECU: a031 pms production mode failed";
CM_ SG_ 920 EPASTS_a032_eolpEolCheckFailed "EPASTS ECU: a032 eolp eol check failed";
CM_ SG_ 920 EPASTS_a033_icsvcPswVersionMisma "EPASTS ECU: a033 icsvc psw version mismatch";
CM_ SG_ 920 EPASTS_a034_sbchReadbackRegFail "EPASTS ECU: a034 sbch readback reg fail";
CM_ SG_ 920 EPASTS_a035_sbchChipIdFail "EPASTS ECU: a035 sbch chip id fail";
CM_ SG_ 920 EPASTS_a036_sbcmSbcBistFailed "EPASTS ECU: a036 sbcm sbc bist failed";
CM_ SG_ 920 EPASTS_a037_epmV5P2Fail "EPASTS ECU: a037 epm V5 P2 fail";
CM_ SG_ 920 EPASTS_a038_csohCh1CsErrorErrAtR "EPASTS ECU: a038 csoh ch1 cs error err at reset";
CM_ SG_ 920 EPASTS_a039_csohCh2CsErrorErrAtR "EPASTS ECU: a039 csoh ch2 cs error err at reset";
CM_ SG_ 920 EPASTS_a040_swrhLimitedResetRetr "EPASTS ECU: a040 swrh limited reset retries expired";
CM_ SG_ 920 EPASTS_a041_imcmCoreConfiguratio "EPASTS ECU: a041 imcm core configuration mismatch";
CM_ SG_ 920 EPASTS_a042_wdhWdTestFail "EPASTS ECU: a042 wdh wd test fail";
CM_ SG_ 920 EPASTS_a043_sbcmWdStateDisabled "EPASTS ECU: a043 sbcm wd state disabled";
CM_ SG_ 920 EPASTS_a044_sbcmSbcEepromFail "EPASTS ECU: a044 sbcm sbc eeprom fail";
CM_ SG_ 920 EPASTS_a045_psumSbcBandgapVoltEr "EPASTS ECU: a045 psum sbc bandgap volt err";
CM_ SG_ 920 EPASTS_a046_mcusscOscillatorNotR "EPASTS ECU: a046 mcussc oscillator not reliable";
CM_ SG_ 920 EPASTS_a047_epmVregVoltFail "EPASTS ECU: a047 epm vreg volt fail";
CM_ SG_ 920 EPASTS_a048_epmVcpVoltFail "EPASTS ECU: a048 epm vcp volt fail";
CM_ SG_ 920 EPASTS_a049_epmLgFail "EPASTS ECU: a049 epm lg fail";
CM_ SG_ 920 EPASTS_a050_erlErr "EPASTS ECU: a050 erl err";
CM_ SG_ 920 EPASTS_a051_ermMessageErr "EPASTS ECU: a051 erm message err";
CM_ SG_ 920 EPASTS_a052_ermSdcInputBufferOve "EPASTS ECU: a052 erm sdc input buffer overflow";
CM_ SG_ 920 EPASTS_a053_adcUnexpectedNumOfDa "EPASTS ECU: a053 adc unexpected num of data";
CM_ SG_ 920 EPASTS_a054_adcUnexpectedData "EPASTS ECU: a054 adc unexpected data";
CM_ SG_ 920 EPASTS_a055_amExtendedGduTest "EPASTS ECU: a055 am extended gdu test";
CM_ SG_ 920 EPASTS_a056_amGduConfigCsErrorCh "EPASTS ECU: a056 am gdu config cs error check";
CM_ SG_ 920 EPASTS_a057_amGduVds "EPASTS ECU: a057 am gdu vds";
CM_ SG_ 920 EPASTS_a058_amIntVgsUndervtgErr "EPASTS ECU: a058 am int vgs undervtg err";
CM_ SG_ 920 EPASTS_a059_amStartupTestFailed "EPASTS ECU: a059 am startup test failed";
CM_ SG_ 920 EPASTS_a060_amGduFail "EPASTS ECU: a060 am gdu fail";
CM_ SG_ 920 EPASTS_a061_amIntSerialErr "EPASTS ECU: a061 am int serial err";
CM_ SG_ 920 EPASTS_a062_amPhaseBridgeCheck "EPASTS ECU: a062 am phase bridge check";
CM_ SG_ 920 EPASTS_a063_amIntRegulatorErr "EPASTS ECU: a063 am int regulator err";
CM_ SG_ 920 EPASTS_a064_amBridgeShort "EPASTS ECU: a064 am bridge short";
CM_ SG_ 920 EPASTS_a065_amGduJuncTemp "EPASTS ECU: a065 am gdu junc temp";
CM_ SG_ 920 EPASTS_a066_amVoltQfErr "EPASTS ECU: a066 am volt qf err";
CM_ SG_ 920 EPASTS_a067_tspmPowermoduleTempI "EPASTS ECU: a067 tspm powermodule temp implausible";
CM_ SG_ 920 EPASTS_a068_rsthCoreRedundancyEr "EPASTS ECU: a068 rsth core redundancy err";
CM_ SG_ 920 EPASTS_a069_rsthCoreTempOutOfRan "EPASTS ECU: a069 rsth core temp out of range hw check";
CM_ SG_ 920 EPASTS_a070_rsthInternalLowVolt "EPASTS ECU: a070 rsth internal low volt";
CM_ SG_ 920 EPASTS_a071_rsthInternalHighVolt "EPASTS ECU: a071 rsth internal high volt";
CM_ SG_ 920 EPASTS_a072_rsthFlashUncorrEccOr "EPASTS ECU: a072 rsth flash uncorr ecc or ovfl";
CM_ SG_ 920 EPASTS_a073_rsthOtherEdcEcc "EPASTS ECU: a073 rsth other edc ecc";
CM_ SG_ 920 EPASTS_a074_rsthUnexpectedAlarm "EPASTS ECU: a074 rsth unexpected alarm";
CM_ SG_ 920 EPASTS_a075_rsthUnusedOtherModul "EPASTS ECU: a075 rsth unused other module alarm";
CM_ SG_ 920 EPASTS_a076_exchGeneralException "EPASTS ECU: a076 exch general exception";
CM_ SG_ 920 EPASTS_a077_dmDeadlineViolation "EPASTS ECU: a077 dm deadline violation";
CM_ SG_ 920 EPASTS_a078_dmDeadlineViolation "EPASTS ECU: a078 dm deadline violation";
CM_ SG_ 920 EPASTS_a079_gduhComErr "EPASTS ECU: a079 gduh com err";
CM_ SG_ 920 EPASTS_a080_pwmTimerSyncCheck "EPASTS ECU: a080 pwm timer sync check";
CM_ SG_ 920 EPASTS_a081_exchFloatingPointExc "EPASTS ECU: a081 exch floating point exception";
CM_ SG_ 920 EPASTS_a082_adcTriggerTimeChk "EPASTS ECU: a082 adc trigger time chk";
CM_ SG_ 920 EPASTS_a083_tdaDclinkcapacitorTe "EPASTS ECU: a083 tda dclinkcapacitor temp checker";
CM_ SG_ 920 EPASTS_a084_adcTriggerCheck "EPASTS ECU: a084 adc trigger check";
CM_ SG_ 920 EPASTS_a085_amGduSwitchOffTestBy "EPASTS ECU: a085 am gdu switch off test by mcu";
CM_ SG_ 920 EPASTS_a086_rsthRamUncorrEcc "EPASTS ECU: a086 rsth ram uncorr ecc";
CM_ SG_ 920 EPASTS_a087_rsthFlashConfigErr "EPASTS ECU: a087 rsth flash config err";
CM_ SG_ 920 EPASTS_a088_tedMainboardTempChec "EPASTS ECU: a088 ted mainboard temp checker";
CM_ SG_ 920 EPASTS_a089_tedRevercebattfetjun "EPASTS ECU: a089 ted revercebattfetjunction temp checker";
CM_ SG_ 920 EPASTS_a090_etsmWarning "EPASTS ECU: a090 etsm warning";
CM_ SG_ 920 EPASTS_a091_bvpBattVoltCrossChkF "EPASTS ECU: a091 bvp batt volt cross chk failed";
CM_ SG_ 920 EPASTS_a092_amGduSwitchOffTestBy "EPASTS ECU: a092 am gdu switch off test by sbc";
CM_ SG_ 920 EPASTS_a093_sctpTsuSingleStaticF "EPASTS ECU: a093 sctp tsu single static fail";
CM_ SG_ 920 EPASTS_a094_sctpTsuMultipleStati "EPASTS ECU: a094 sctp tsu multiple static fail";
CM_ SG_ 920 EPASTS_a095_mdModelBasedMotorInt "EPASTS ECU: a095 md model based motor integrity check";
CM_ SG_ 920 EPASTS_a096_rppRpsSingleStaticFa "EPASTS ECU: a096 rpp rps single static fail";
CM_ SG_ 920 EPASTS_a097_rppRpsMultipleStatic "EPASTS ECU: a097 rpp rps multiple static fail";
CM_ SG_ 920 EPASTS_a098_invErr "EPASTS ECU: a098 inv err";
CM_ SG_ 920 EPASTS_a099_mcdTorqueMismatchFau "EPASTS ECU: a099 mcd torque mismatch fault";
CM_ SG_ 920 EPASTS_a100_amVbrgLssFault "EPASTS ECU: a100 am vbrg lss fault";
CM_ SG_ 920 EPASTS_a101_sdrvSpcIdMismatch "EPASTS ECU: a101 sdrv spc id mismatch";
CM_ SG_ 920 EPASTS_a102_amPhasecurrentQosErr "EPASTS ECU: a102 am phasecurrent qos err";
CM_ SG_ 920 EPASTS_a103_exhaUnusedInterruptC "EPASTS ECU: a103 exha unused interrupt call exception";
CM_ SG_ 920 EPASTS_a104_exhaBusMpuException "EPASTS ECU: a104 exha bus mpu exception";
CM_ SG_ 920 EPASTS_a105_exhaSriBusErrExcepti "EPASTS ECU: a105 exha sri bus err exception";
CM_ SG_ 920 EPASTS_a106_exhaSpbBusErrExcepti "EPASTS ECU: a106 exha spb bus err exception";
CM_ SG_ 920 EPASTS_a107_exhaOtherNmiExceptio "EPASTS ECU: a107 exha other nmi exception";
CM_ SG_ 920 EPASTS_a108_exhaInternalProtecti "EPASTS ECU: a108 exha internal protection exception";
CM_ SG_ 920 EPASTS_a109_exhaSysBusOrPeriphEr "EPASTS ECU: a109 exha sys bus or periph err exception";
CM_ SG_ 920 EPASTS_a110_amPhaseRelaySwitchOf "EPASTS ECU: a110 am phase relay switch off test";
CM_ SG_ 920 EPASTS_a111_amCurrentSensingDisc "EPASTS ECU: a111 am current sensing disconnection";
CM_ SG_ 920 EPASTS_a112_rsthSafetyFlipflopEr "EPASTS ECU: a112 rsth safety flipflop err";
CM_ SG_ 920 EPASTS_a113_rsthUncorrectableEnd "EPASTS ECU: a113 rsth uncorrectable end to end bus err";
CM_ SG_ 920 EPASTS_a114_osehOsErr "EPASTS ECU: a114 oseh os err";
CM_ SG_ 920 EPASTS_a115_mcusscLbistSingleFai "EPASTS ECU: a115 mcussc lbist single fail";
CM_ SG_ 920 EPASTS_a116_mrccStartupRegCsErro "EPASTS ECU: a116 mrcc startup reg cs error static err";
CM_ SG_ 920 EPASTS_a117_mrccStartupRegCsErro "EPASTS ECU: a117 mrcc startup reg cs error transient err";
CM_ SG_ 920 EPASTS_a118_mcusscFlashCsErrorEr "EPASTS ECU: a118 mcussc flash cs error err";
CM_ SG_ 920 EPASTS_a119_mcusscFlashEccCritic "EPASTS ECU: a119 mcussc flash ecc critical err";
CM_ SG_ 920 EPASTS_a120_mcusscFlashEccLatent "EPASTS ECU: a120 mcussc flash ecc latent err";
CM_ SG_ 920 EPASTS_a121_mcusscMbistEccErr "EPASTS ECU: a121 mcussc mbist ecc err";
CM_ SG_ 920 EPASTS_a122_pcpBridgeFetShort "EPASTS ECU: a122 pcp bridge fet short";
CM_ SG_ 920 EPASTS_a123_imcmCommErr "EPASTS ECU: a123 imcm comm err";
CM_ SG_ 920 EPASTS_a124_mcusscMbistEccTransi "EPASTS ECU: a124 mcussc mbist ecc transient err";
CM_ SG_ 920 EPASTS_a125_mcusscMbistMiaErr "EPASTS ECU: a125 mcussc mbist mia err";
CM_ SG_ 920 EPASTS_a126_mcusscMonbistMiaErr "EPASTS ECU: a126 mcussc monbist mia err";
CM_ SG_ 920 EPASTS_a127_exchAdditionalExcept "EPASTS ECU: a127 exch additional exception after rst";
CM_ SG_ 920 EPASTS_a128_exchExceptionStopRes "EPASTS ECU: a128 exch exception stop restart";
CM_ SG_ 920 EPASTS_a129_exchAdditionalExcept "EPASTS ECU: a129 exch additional exception stop restart";
CM_ SG_ 920 EPASTS_a130_mrccConfigCsErrorErr "EPASTS ECU: a130 mrcc config cs error err";
CM_ SG_ 920 EPASTS_a131_exchGuardedResetAfte "EPASTS ECU: a131 exch guarded reset after partition stop";
CM_ SG_ 920 EPASTS_a132_mcusscNotSupportedMc "EPASTS ECU: a132 mcussc not supported mcu";
CM_ SG_ 920 EPASTS_a133_mcusscLbistEcuIdIsNo "EPASTS ECU: a133 mcussc lbist ecu id is not supported";
CM_ SG_ 920 EPASTS_a134_osehGuardedResetAfte "EPASTS ECU: a134 oseh guarded reset after err without reset";
CM_ SG_ 920 EPASTS_a135_tmpsfetjCalculationO "EPASTS ECU: a135 tmpsfetj calculation overflow err";
CM_ SG_ 920 EPASTS_a136_ftElectricalAngleQf "EPASTS ECU: a136 ft electrical angle qf";
CM_ SG_ 920 EPASTS_a137_osehErrWithoutImmedi "EPASTS ECU: a137 oseh err without immediate reset";
CM_ SG_ 920 EPASTS_a138_osehAdditionalErrWit "EPASTS ECU: a138 oseh additional err without imm reset";
CM_ SG_ 920 EPASTS_a139_osehAdditionalOsErr "EPASTS ECU: a139 oseh additional os err";
CM_ SG_ 920 EPASTS_a140_imcmConfigurationErr "EPASTS ECU: a140 imcm configuration err";
CM_ SG_ 920 EPASTS_a141_amFetShortTest "EPASTS ECU: a141 am fet short test";
CM_ SG_ 920 EPASTS_a142_tedEmifilterDmcTempC "EPASTS ECU: a142 ted emifilter dmc temp checker";
CM_ SG_ 920 EPASTS_a143_tedEmifilterCmcTempC "EPASTS ECU: a143 ted emifilter cmc temp checker";
CM_ SG_ 920 EPASTS_a144_mriCoreRaminitFailed "EPASTS ECU: a144 mri core raminit failed";
CM_ SG_ 920 EPASTS_a145_mriPeripheralRaminit "EPASTS ECU: a145 mri peripheral raminit failed";
CM_ SG_ 920 EPASTS_a146_btarcRcCircuitCheck "EPASTS ECU: a146 btarc rc circuit check";
CM_ SG_ 920 EPASTS_a147_amDcLinkShortedFail "EPASTS ECU: a147 am dc link shorted fail";
CM_ SG_ 920 EPASTS_a148_mrccExitFromStandbyD "EPASTS ECU: a148 mrcc exit from standby detected";
CM_ SG_ 920 EPASTS_a149_amReversibleEmergenc "EPASTS ECU: a149 am reversible emergency off requested";
CM_ SG_ 920 EPASTS_a150_amExternalEmergencyO "EPASTS ECU: a150 am external emergency off requested";
CM_ SG_ 920 EPASTS_a151_amPermanentEmergency "EPASTS ECU: a151 am permanent emergency off requested";
CM_ SG_ 920 EPASTS_a152_exchFlashEccExceptio "EPASTS ECU: a152 exch flash ecc exception";
CM_ SG_ 920 EPASTS_a153_sdsmBlockSelectorInv "EPASTS ECU: a153 sdsm block selector invalid";
CM_ SG_ 920 EPASTS_a154_sdsmCsErrorInvalidPr "EPASTS ECU: a154 sdsm cs error invalid primary";
CM_ SG_ 920 EPASTS_a155_sdsmDataInvalidAll "EPASTS ECU: a155 sdsm data invalid all";
CM_ SG_ 920 EPASTS_a156_amIntSerialErrSafety "EPASTS ECU: a156 am int serial err safety reset";
CM_ SG_ 920 EPASTS_a157_mcudcpInvalidEcuId "EPASTS ECU: a157 mcudcp invalid ecu id";
CM_ SG_ 920 EPASTS_a158_amGduFailDuringRecov "EPASTS ECU: a158 am gdu fail during recovery";
CM_ SG_ 920 EPASTS_a159_exchFlashWordlineTra "EPASTS ECU: a159 exch flash wordline transient err";
CM_ SG_ 920 EPASTS_a160_rsthCpu1UnexpectedAl "EPASTS ECU: a160 rsth cpu1 unexpected alarm";
CM_ SG_ 920 EPASTS_a161_tdaRelayfetjunctionT "EPASTS ECU: a161 tda relayfetjunction temp checker";
CM_ SG_ 920 EPASTS_a162_tdaBridgefetjunction "EPASTS ECU: a162 tda bridgefetjunction temp checker";
CM_ SG_ 920 EPASTS_a163_tdaPowermoduleTempCh "EPASTS ECU: a163 tda powermodule temp checker";
CM_ SG_ 920 EPASTS_a164_tdaBattfetjunctionTe "EPASTS ECU: a164 tda battfetjunction temp checker";
CM_ SG_ 920 EPASTS_a165_tdaDcbusshuntTempChe "EPASTS ECU: a165 tda dcbusshunt temp checker";
CM_ SG_ 920 EPASTS_a166_tdaPhasecurrentshunt "EPASTS ECU: a166 tda phasecurrentshunt temp checker";
CM_ SG_ 920 EPASTS_a167_iccd1ErrQueueOverflo "EPASTS ECU: a167 iccd1 err queue overflow";
CM_ SG_ 920 EPASTS_a168_c1csInvalidC1App "EPASTS ECU: a168 c1cs invalid C1 app";
CM_ SG_ 920 EPASTS_a169_scpSafetyReset "EPASTS ECU: a169 scp safety reset";
CM_ SG_ 920 EPASTS_a170_pmpDcvoltAge "EPASTS ECU: a170 pmp dcvolt age";
CM_ SG_ 920 EPASTS_a171_pmpKgvalueAge "EPASTS ECU: a171 pmp kgvalue age";
CM_ SG_ 920 EPASTS_a172_pmpElangMotorcurrent "EPASTS ECU: a172 pmp elang motorcurrent age";
CM_ SG_ 920 EPASTS_a173_pmpRotorspeedAge "EPASTS ECU: a173 pmp rotorspeed age";
CM_ SG_ 920 EPASTS_a174_pmpPhasecurrentAge "EPASTS ECU: a174 pmp phasecurrent age";
CM_ SG_ 920 EPASTS_a175_exchFlashStoredConfi "EPASTS ECU: a175 exch flash stored config err";
CM_ SG_ 920 EPASTS_a176_exchCpu1ExceptionRes "EPASTS ECU: a176 exch cpu1 exception reset";
CM_ SG_ 920 EPASTS_a177_etsrInvalidated "EPASTS ECU: a177 etsr invalidated";
CM_ SG_ 920 EPASTS_a178_exchWdtException "EPASTS ECU: a178 exch wdt exception";
CM_ SG_ 920 EPASTS_a179_tedMotorcoilTempChec "EPASTS ECU: a179 ted motorcoil temp checker";
CM_ SG_ 920 EPASTS_a180_dmDeadlineViolationC "EPASTS ECU: a180 dm deadline violation C1";
CM_ SG_ 920 EPASTS_a181_dmDeadlineViolationC "EPASTS ECU: a181 dm deadline violation C1";
CM_ SG_ 920 EPASTS_a182_mcdInputMia "EPASTS ECU: a182 mcd input mia";
CM_ SG_ 920 EPASTS_a183_sbchCommErrSbcToMcu "EPASTS ECU: a183 sbch comm err sbc to mcu";
CM_ SG_ 920 EPASTS_a184_sbcmCommBufferOverfl "EPASTS ECU: a184 sbcm comm buffer overflow";
CM_ SG_ 920 EPASTS_a185_sbcscpQAWatchdogRese "EPASTS ECU: a185 sbcscp QA watchdog reset";
CM_ SG_ 920 EPASTS_a186_wdhCommBufferOverflo "EPASTS ECU: a186 wdh comm buffer overflow";
CM_ SG_ 920 EPASTS_a187_epmVoltFail "EPASTS ECU: a187 epm volt fail";
CM_ SG_ 920 EPASTS_a188_epmCommBufferOverflo "EPASTS ECU: a188 epm comm buffer overflow";
CM_ SG_ 920 EPASTS_a189_sbchCommErrMcuToSbc "EPASTS ECU: a189 sbch comm err mcu to sbc";
CM_ SG_ 920 EPASTS_a190_sbchCommBufferOverfl "EPASTS ECU: a190 sbch comm buffer overflow";
CM_ SG_ 920 EPASTS_a191_sbcscpVcp2VucVoltFai "EPASTS ECU: a191 sbcscp vcp2 vuc volt fail";
CM_ SG_ 920 EPASTS_a192_osumC0CsaNearFull "EPASTS ECU: a192 osum C0 csa near full";
CM_ SG_ 920 EPASTS_a193_osumC0StackNearFull "EPASTS ECU: a193 osum C0 stack near full";
CM_ SG_ 920 EPASTS_a194_amNvdataLoss "EPASTS ECU: a194 am nvdata loss";
CM_ SG_ 920 EPASTS_a195_imcmCommErrC1 "EPASTS ECU: a195 imcm comm err C1";
CM_ SG_ 920 EPASTS_a196_topEolTasOffsetInval "EPASTS ECU: a196 top eol tas offset invalid";
CM_ SG_ 920 EPASTS_a197_difpDifactorInvalid "EPASTS ECU: a197 difp difactor invalid";
CM_ SG_ 920 EPASTS_a198_osumC1CsaNearFull "EPASTS ECU: a198 osum C1 csa near full";
CM_ SG_ 920 EPASTS_a199_osumC1StackNearFull "EPASTS ECU: a199 osum C1 stack near full";
CM_ SG_ 920 EPASTS_a200_ammInputBufferOverfl "EPASTS ECU: a200 amm input buffer overflow";
CM_ SG_ 920 EPASTS_a201_ammOutputBufferOverf "EPASTS ECU: a201 amm output buffer overflow";
CM_ SG_ 920 EPASTS_a202_ohnvmpStoredOffsetLo "EPASTS ECU: a202 ohnvmp stored offset lost";
CM_ SG_ 920 EPASTS_a203_ctcInterfaceErr "EPASTS ECU: a203 ctc interface err";
CM_ SG_ 920 EPASTS_a204_fdpPrevTrqErr "EPASTS ECU: a204 fdp prev trq err";
CM_ SG_ 920 EPASTS_a205_fdrOclFail "EPASTS ECU: a205 fdr ocl fail";
CM_ SG_ 920 EPASTS_a206_fdrOclPartialBlockin "EPASTS ECU: a206 fdr ocl partial blocking";
CM_ SG_ 920 EPASTS_a207_fdrOclFreezing "EPASTS ECU: a207 fdr ocl freezing";
CM_ SG_ 920 EPASTS_a208_fdrLowSeverityBlocki "EPASTS ECU: a208 fdr low severity blocking";
CM_ SG_ 920 EPASTS_a209_fdrLowSeverityFreezi "EPASTS ECU: a209 fdr low severity freezing";
CM_ SG_ 920 EPASTS_a210_fdrTotalBlocking "EPASTS ECU: a210 fdr total blocking";
CM_ SG_ 920 EPASTS_a211_frmInternalErr "EPASTS ECU: a211 frm internal err";
CM_ SG_ 920 EPASTS_a212_frmDataLost "EPASTS ECU: a212 frm data lost";
CM_ SG_ 920 EPASTS_a213_frmHighFrictionDetec "EPASTS ECU: a213 frm high friction detected";
CM_ SG_ 920 EPASTS_a214_velInterfaceErr "EPASTS ECU: a214 vel interface err";
CM_ SG_ 920 EPASTS_a215_vsgSafeViolErr "EPASTS ECU: a215 vsg safe viol err";
CM_ SG_ 920 EPASTS_a216_isdgImproperShutdown "EPASTS ECU: a216 isdg improper shutdown";
CM_ SG_ 920 EPASTS_a217_msdMasterSilentErr "EPASTS ECU: a217 msd master silent err";
CM_ SG_ 920 EPASTS_a218_aadApplicationStateE "EPASTS ECU: a218 aad application state err";
CM_ SG_ 920 EPASTS_a219_frhFastRestartFailed "EPASTS ECU: a219 frh fast restart failed";
CM_ SG_ 920 EPASTS_a220_transceiverInputqueu "EPASTS ECU: a220 transceiver inputqueue overflow";
CM_ SG_ 920 EPASTS_a221_apsCntError "EPASTS ECU: a221 aps cnt error";
CM_ SG_ 920 EPASTS_a222_apsCsError "EPASTS ECU: a222 aps cs error";
CM_ SG_ 920 EPASTS_a223_apsMia "EPASTS ECU: a223 aps mia";
CM_ SG_ 920 EPASTS_a224_dasCntError "EPASTS ECU: a224 das cnt error";
CM_ SG_ 920 EPASTS_a225_dasCsError "EPASTS ECU: a225 das cs error";
CM_ SG_ 920 EPASTS_a226_dasMia "EPASTS ECU: a226 das mia";
CM_ SG_ 920 EPASTS_a227_dirTorqueCntError "EPASTS ECU: a227 dir torque cnt error";
CM_ SG_ 920 EPASTS_a228_dirTorqueCsError "EPASTS ECU: a228 dir torque cs error";
CM_ SG_ 920 EPASTS_a229_dirTorqueMia "EPASTS ECU: a229 dir torque mia";
CM_ SG_ 920 EPASTS_a230_diSpdCntError "EPASTS ECU: a230 di spd cnt error";
CM_ SG_ 920 EPASTS_a231_diSpdCsError "EPASTS ECU: a231 di spd cs error";
CM_ SG_ 920 EPASTS_a232_diSpdMia "EPASTS ECU: a232 di spd mia";
CM_ SG_ 920 EPASTS_a233_ecu1StatCntError "EPASTS ECU: a233 ecu1 stat cnt error";
CM_ SG_ 920 EPASTS_a234_ecu1StatCsError "EPASTS ECU: a234 ecu1 stat cs error";
CM_ SG_ 920 EPASTS_a235_ecu1StatMia "EPASTS ECU: a235 ecu1 stat mia";
CM_ SG_ 920 EPASTS_a236_espWrCntError "EPASTS ECU: a236 esp wr cnt error";
CM_ SG_ 920 EPASTS_a237_espWrCsError "EPASTS ECU: a237 esp wr cs error";
CM_ SG_ 920 EPASTS_a238_espWrMia "EPASTS ECU: a238 esp wr mia";
CM_ SG_ 920 EPASTS_a239_espWsCntError "EPASTS ECU: a239 esp ws cnt error";
CM_ SG_ 920 EPASTS_a240_espWsCsError "EPASTS ECU: a240 esp ws cs error";
CM_ SG_ 920 EPASTS_a241_espWsMia "EPASTS ECU: a241 esp ws mia";
CM_ SG_ 920 EPASTS_a242_gtwConfigMia "EPASTS ECU: a242 gtw config mia";
CM_ SG_ 920 EPASTS_a243_rcmCntError "EPASTS ECU: a243 rcm cnt error";
CM_ SG_ 920 EPASTS_a244_rcmCsError "EPASTS ECU: a244 rcm cs error";
CM_ SG_ 920 EPASTS_a245_rcmMia "EPASTS ECU: a245 rcm mia";
CM_ SG_ 920 EPASTS_a246_sccmCntError "EPASTS ECU: a246 sccm cnt error";
CM_ SG_ 920 EPASTS_a247_sccmCsError "EPASTS ECU: a247 sccm cs error";
CM_ SG_ 920 EPASTS_a248_sccmMia "EPASTS ECU: a248 sccm mia";
CM_ SG_ 920 EPASTS_a249_uiTuneReqCntError "EPASTS ECU: a249 ui tune req cnt error";
CM_ SG_ 920 EPASTS_a250_uiTuneReqCsError "EPASTS ECU: a250 ui tune req cs error";
CM_ SG_ 920 EPASTS_a251_uiTuneReqMia "EPASTS ECU: a251 ui tune req mia";
CM_ SG_ 920 EPASTS_a252_vcFrontCntError "EPASTS ECU: a252 vc front cnt error";
CM_ SG_ 920 EPASTS_a253_vcFrontCsError "EPASTS ECU: a253 vc front cs error";
CM_ SG_ 920 EPASTS_a254_vcFrontMia "EPASTS ECU: a254 vc front mia";
CM_ SG_ 920 EPASTS_a255_pmState2Mia "EPASTS ECU: a255 pm state2 mia";
CM_ SG_ 920 EPASTS_a256_dcvmOverVolt "EPASTS ECU: a256 dcvm over volt";
CM_ SG_ 920 EPASTS_a257_dcvmUnderVolt "EPASTS ECU: a257 dcvm under volt";
CM_ SG_ 920 EPASTS_a258_pspInvalidProjectPar "EPASTS ECU: a258 psp invalid project paramset";
CM_ SG_ 920 EPASTS_a259_scoCanBusOff "EPASTS ECU: a259 sco can bus off";
CM_ SG_ 920 EPASTS_a260_scoPrivateBusOff "EPASTS ECU: a260 sco private bus off";
CM_ SG_ 920 EPASTS_a261_sccmStatusError "EPASTS ECU: a261 sccm status error";
CM_ SG_ 920 EPASTS_a262_yawRateStatus "EPASTS ECU: a262 yaw rate status";
CM_ SG_ 920 EPASTS_a263_espWsStatus "EPASTS ECU: a263 esp ws status";
CM_ SG_ 920 EPASTS_a264_assistTorqueLimited "EPASTS ECU: a264 assist torque limited";
CM_ SG_ 920 EPASTS_a265_overheatProtect "EPASTS ECU: a265 overheat protect";
CM_ SG_ 920 EPASTS_a266_overloadProtect "EPASTS ECU: a266 overload protect";
CM_ SG_ 920 EPASTS_a267_safeSpeedAssist "EPASTS ECU: a267 safe speed assist";
CM_ SG_ 920 EPASTS_a268_eacCancelled "EPASTS ECU: a268 eac cancelled";
CM_ SG_ 920 EPASTS_a269_assistTorqueDisabled "EPASTS ECU: a269 assist torque disabled";
CM_ SG_ 920 EPASTS_a270_oscillationCompTrqLi "EPASTS ECU: a270 oscillation comp trq lim reached";
CM_ BO_ 805 "Electronic stability control message: info; frame length from the layout, not yet observed on a vehicle bus";
CM_ SG_ 805 ESP_infoIndex "Electronic stability control: info index";
CM_ SG_ 805 ESP_infoBuildType "Electronic stability control: info build type";
CM_ SG_ 805 ESP_vehFlashMode "Electronic stability control: veh flash mode";
CM_ SG_ 805 ESP_infoComponentID "Electronic stability control: info component ID";
CM_ SG_ 805 ESP_infoPcbaID "Electronic stability control: info pcba ID";
CM_ SG_ 805 ESP_infoAssemblyID "Electronic stability control: info assembly ID";
CM_ SG_ 805 ESP_infoUsageID "Electronic stability control: info usage ID";
CM_ SG_ 805 ESP_infoSubUsageID "Electronic stability control: info sub usage ID";
CM_ SG_ 805 ESP_infoApplicationCRC "Indicating the Application CRC value of firmware running in system.";
CM_ SG_ 805 ESP_infoVehicleVariant "Electronic stability control: info vehicle variant";
CM_ SG_ 805 ESP_infoSubcomponent1 "Electronic stability control: info subcomponent1";
CM_ SG_ 805 ESP_infoBootUdsProtoVersion "Electronic stability control: info boot uds proto version";
CM_ SG_ 805 ESP_infoBootloaderCRC "Electronic stability control: info bootloader CRC";
CM_ SG_ 805 ESP_infoVariantCRC "Indicating the Calibration CRC value of firmware running in system.";
CM_ BO_ 813 "Electric brake booster message: info; frame length from the layout, not yet observed on a vehicle bus";
CM_ SG_ 813 IBST_infoIndex "Electric brake booster: info index";
CM_ SG_ 813 IBST_infoBuildType "Electric brake booster: info build type";
CM_ SG_ 813 IBST_infoComponentID "Electric brake booster: info component ID";
CM_ SG_ 813 IBST_infoPcbaID "Electric brake booster: info pcba ID";
CM_ SG_ 813 IBST_infoAssemblyID "Electric brake booster: info assembly ID";
CM_ SG_ 813 IBST_infoUsageID "Electric brake booster: info usage ID";
CM_ SG_ 813 IBST_infoSubUsageID "Electric brake booster: info sub usage ID";
CM_ SG_ 813 IBST_infoApplicationCRC "Indicating the Application CRC value of firmware running in system.";
CM_ SG_ 813 IBST_infoBootUdsProtoVersion "Electric brake booster: info boot uds proto version";
CM_ SG_ 813 IBST_infoBootloaderCRC "Electric brake booster: info bootloader CRC";
CM_ SG_ 813 IBST_infoVariantCRC "Indicating the Calibration CRC value of firmware running in system.";
CM_ BO_ 828 "IDB ECU message: info; frame length from the layout, not yet observed on a vehicle bus";
CM_ SG_ 828 IDB_infoIndex "IDB ECU: info index";
CM_ SG_ 828 IDB_infoPcbaID "IDB ECU: info pcba ID";
CM_ SG_ 828 IDB_infoAssemblyID "IDB ECU: info assembly ID";
CM_ SG_ 828 IDB_infoUsageID "IDB ECU: info usage ID";
CM_ SG_ 828 IDB_infoSubUsageID "IDB ECU: info sub usage ID";
CM_ BO_ 1486 "Parking assist sensors message: alert log; frame length from the layout, not yet observed on a vehicle bus";
CM_ SG_ 1486 PARK_alertID "Parking assist sensors: alert ID";
CM_ SG_ 1486 PARK_alertState "Parking assist sensors: alert state";
CM_ SG_ 1486 PARK_sw001_sensorTemperature "Parking assist sensors: sw001 sensor temperature";
CM_ SG_ 1486 PARK_sw002_membraneDisconct "Parking assist sensors: sw002 membrane disconct";
CM_ SG_ 1486 PARK_sw002_dampResistorFail "Parking assist sensors: sw002 damp resistor fail";
CM_ SG_ 1486 PARK_sw002_resonanceDrift "Parking assist sensors: sw002 resonance drift";
CM_ SG_ 1486 PARK_sw002_sensorCRC "Parking assist sensors: sw002 sensor CRC";
CM_ SG_ 1486 PARK_sw002_recieveFailure "Parking assist sensors: sw002 recieve failure";
CM_ SG_ 1486 PARK_sw002_diagnosticTransferErr "Parking assist sensors: sw002 diagnostic transfer error";
CM_ SG_ 1486 PARK_sw003_linError "Parking assist sensors: sw003 lin error";
CM_ SG_ 1486 PARK_sw003_linBusError "Parking assist sensors: sw003 lin bus error";
CM_ SG_ 1486 PARK_sw003_linFrameCountError "Parking assist sensors: sw003 lin frame count error";
CM_ SG_ 1486 PARK_sw004_reverbPeriod "Parking assist sensors: sw004 reverb period";
CM_ SG_ 1486 PARK_sw004_reverbTime "Parking assist sensors: sw004 reverb time";
CM_ SG_ 1486 PARK_sw004_highAttenTime "Parking assist sensors: sw004 high atten time";
CM_ SG_ 1486 PARK_sw004_closeConstEcho "Parking assist sensors: sw004 close const echo";
CM_ SG_ 1486 PARK_sw004_lowAttenTime "Parking assist sensors: sw004 low atten time";
CM_ SG_ 1486 PARK_sw004_attenTimeJitter "Parking assist sensors: sw004 atten time jitter";
CM_ SG_ 1486 PARK_sw004_reverbFreqJitter "Parking assist sensors: sw004 reverb freq jitter";
CM_ SG_ 1486 PARK_sw006_sensorTemperature "Parking assist sensors: sw006 sensor temperature";
CM_ SG_ 1486 PARK_sw007_membraneDisconct "Parking assist sensors: sw007 membrane disconct";
CM_ SG_ 1486 PARK_sw007_dampResistorFail "Parking assist sensors: sw007 damp resistor fail";
CM_ SG_ 1486 PARK_sw007_resonanceDrift "Parking assist sensors: sw007 resonance drift";
CM_ SG_ 1486 PARK_sw007_sensorCRC "Parking assist sensors: sw007 sensor CRC";
CM_ SG_ 1486 PARK_sw007_recieveFailure "Parking assist sensors: sw007 recieve failure";
CM_ SG_ 1486 PARK_sw007_diagnosticTransferErr "Parking assist sensors: sw007 diagnostic transfer error";
CM_ SG_ 1486 PARK_sw008_linError "Parking assist sensors: sw008 lin error";
CM_ SG_ 1486 PARK_sw008_linBusError "Parking assist sensors: sw008 lin bus error";
CM_ SG_ 1486 PARK_sw008_linFrameCountError "Parking assist sensors: sw008 lin frame count error";
CM_ SG_ 1486 PARK_sw009_reverbPeriod "Parking assist sensors: sw009 reverb period";
CM_ SG_ 1486 PARK_sw009_reverbTime "Parking assist sensors: sw009 reverb time";
CM_ SG_ 1486 PARK_sw009_highAttenTime "Parking assist sensors: sw009 high atten time";
CM_ SG_ 1486 PARK_sw009_closeConstEcho "Parking assist sensors: sw009 close const echo";
CM_ SG_ 1486 PARK_sw009_lowAttenTime "Parking assist sensors: sw009 low atten time";
CM_ SG_ 1486 PARK_sw009_attenTimeJitter "Parking assist sensors: sw009 atten time jitter";
CM_ SG_ 1486 PARK_sw009_reverbFreqJitter "Parking assist sensors: sw009 reverb freq jitter";
CM_ SG_ 1486 PARK_sw011_sensorTemperature "Parking assist sensors: sw011 sensor temperature";
CM_ SG_ 1486 PARK_sw012_membraneDisconct "Parking assist sensors: sw012 membrane disconct";
CM_ SG_ 1486 PARK_sw012_dampResistorFail "Parking assist sensors: sw012 damp resistor fail";
CM_ SG_ 1486 PARK_sw012_resonanceDrift "Parking assist sensors: sw012 resonance drift";
CM_ SG_ 1486 PARK_sw012_sensorCRC "Parking assist sensors: sw012 sensor CRC";
CM_ SG_ 1486 PARK_sw012_recieveFailure "Parking assist sensors: sw012 recieve failure";
CM_ SG_ 1486 PARK_sw012_diagnosticTransferErr "Parking assist sensors: sw012 diagnostic transfer error";
CM_ SG_ 1486 PARK_sw013_linError "Parking assist sensors: sw013 lin error";
CM_ SG_ 1486 PARK_sw013_linBusError "Parking assist sensors: sw013 lin bus error";
CM_ SG_ 1486 PARK_sw013_linFrameCountError "Parking assist sensors: sw013 lin frame count error";
CM_ SG_ 1486 PARK_sw014_reverbPeriod "Parking assist sensors: sw014 reverb period";
CM_ SG_ 1486 PARK_sw014_reverbTime "Parking assist sensors: sw014 reverb time";
CM_ SG_ 1486 PARK_sw014_highAttenTime "Parking assist sensors: sw014 high atten time";
CM_ SG_ 1486 PARK_sw014_closeConstEcho "Parking assist sensors: sw014 close const echo";
CM_ SG_ 1486 PARK_sw014_lowAttenTime "Parking assist sensors: sw014 low atten time";
CM_ SG_ 1486 PARK_sw014_attenTimeJitter "Parking assist sensors: sw014 atten time jitter";
CM_ SG_ 1486 PARK_sw014_reverbFreqJitter "Parking assist sensors: sw014 reverb freq jitter";
CM_ SG_ 1486 PARK_sw016_sensorTemperature "Parking assist sensors: sw016 sensor temperature";
CM_ SG_ 1486 PARK_sw017_membraneDisconct "Parking assist sensors: sw017 membrane disconct";
CM_ SG_ 1486 PARK_sw017_dampResistorFail "Parking assist sensors: sw017 damp resistor fail";
CM_ SG_ 1486 PARK_sw017_resonanceDrift "Parking assist sensors: sw017 resonance drift";
CM_ SG_ 1486 PARK_sw017_sensorCRC "Parking assist sensors: sw017 sensor CRC";
CM_ SG_ 1486 PARK_sw017_recieveFailure "Parking assist sensors: sw017 recieve failure";
CM_ SG_ 1486 PARK_sw017_diagnosticTransferErr "Parking assist sensors: sw017 diagnostic transfer error";
CM_ SG_ 1486 PARK_sw018_linError "Parking assist sensors: sw018 lin error";
CM_ SG_ 1486 PARK_sw018_linBusError "Parking assist sensors: sw018 lin bus error";
CM_ SG_ 1486 PARK_sw018_linFrameCountError "Parking assist sensors: sw018 lin frame count error";
CM_ SG_ 1486 PARK_sw019_reverbPeriod "Parking assist sensors: sw019 reverb period";
CM_ SG_ 1486 PARK_sw019_reverbTime "Parking assist sensors: sw019 reverb time";
CM_ SG_ 1486 PARK_sw019_highAttenTime "Parking assist sensors: sw019 high atten time";
CM_ SG_ 1486 PARK_sw019_closeConstEcho "Parking assist sensors: sw019 close const echo";
CM_ SG_ 1486 PARK_sw019_lowAttenTime "Parking assist sensors: sw019 low atten time";
CM_ SG_ 1486 PARK_sw019_attenTimeJitter "Parking assist sensors: sw019 atten time jitter";
CM_ SG_ 1486 PARK_sw019_reverbFreqJitter "Parking assist sensors: sw019 reverb freq jitter";
CM_ SG_ 1486 PARK_sw021_sensorTemperature "Parking assist sensors: sw021 sensor temperature";
CM_ SG_ 1486 PARK_sw022_membraneDisconct "Parking assist sensors: sw022 membrane disconct";
CM_ SG_ 1486 PARK_sw022_dampResistorFail "Parking assist sensors: sw022 damp resistor fail";
CM_ SG_ 1486 PARK_sw022_resonanceDrift "Parking assist sensors: sw022 resonance drift";
CM_ SG_ 1486 PARK_sw022_sensorCRC "Parking assist sensors: sw022 sensor CRC";
CM_ SG_ 1486 PARK_sw022_recieveFailure "Parking assist sensors: sw022 recieve failure";
CM_ SG_ 1486 PARK_sw022_diagnosticTransferErr "Parking assist sensors: sw022 diagnostic transfer error";
CM_ SG_ 1486 PARK_sw023_linError "Parking assist sensors: sw023 lin error";
CM_ SG_ 1486 PARK_sw023_linBusError "Parking assist sensors: sw023 lin bus error";
CM_ SG_ 1486 PARK_sw023_linFrameCountError "Parking assist sensors: sw023 lin frame count error";
CM_ SG_ 1486 PARK_sw024_reverbPeriod "Parking assist sensors: sw024 reverb period";
CM_ SG_ 1486 PARK_sw024_reverbTime "Parking assist sensors: sw024 reverb time";
CM_ SG_ 1486 PARK_sw024_highAttenTime "Parking assist sensors: sw024 high atten time";
CM_ SG_ 1486 PARK_sw024_closeConstEcho "Parking assist sensors: sw024 close const echo";
CM_ SG_ 1486 PARK_sw024_lowAttenTime "Parking assist sensors: sw024 low atten time";
CM_ SG_ 1486 PARK_sw024_attenTimeJitter "Parking assist sensors: sw024 atten time jitter";
CM_ SG_ 1486 PARK_sw024_reverbFreqJitter "Parking assist sensors: sw024 reverb freq jitter";
CM_ SG_ 1486 PARK_sw026_sensorTemperature "Parking assist sensors: sw026 sensor temperature";
CM_ SG_ 1486 PARK_sw027_membraneDisconct "Parking assist sensors: sw027 membrane disconct";
CM_ SG_ 1486 PARK_sw027_dampResistorFail "Parking assist sensors: sw027 damp resistor fail";
CM_ SG_ 1486 PARK_sw027_resonanceDrift "Parking assist sensors: sw027 resonance drift";
CM_ SG_ 1486 PARK_sw027_sensorCRC "Parking assist sensors: sw027 sensor CRC";
CM_ SG_ 1486 PARK_sw027_recieveFailure "Parking assist sensors: sw027 recieve failure";
CM_ SG_ 1486 PARK_sw027_diagnosticTransferErr "Parking assist sensors: sw027 diagnostic transfer error";
CM_ SG_ 1486 PARK_sw028_linError "Parking assist sensors: sw028 lin error";
CM_ SG_ 1486 PARK_sw028_linBusError "Parking assist sensors: sw028 lin bus error";
CM_ SG_ 1486 PARK_sw028_linFrameCountError "Parking assist sensors: sw028 lin frame count error";
CM_ SG_ 1486 PARK_sw029_reverbPeriod "Parking assist sensors: sw029 reverb period";
CM_ SG_ 1486 PARK_sw029_reverbTime "Parking assist sensors: sw029 reverb time";
CM_ SG_ 1486 PARK_sw029_highAttenTime "Parking assist sensors: sw029 high atten time";
CM_ SG_ 1486 PARK_sw029_closeConstEcho "Parking assist sensors: sw029 close const echo";
CM_ SG_ 1486 PARK_sw029_lowAttenTime "Parking assist sensors: sw029 low atten time";
CM_ SG_ 1486 PARK_sw029_attenTimeJitter "Parking assist sensors: sw029 atten time jitter";
CM_ SG_ 1486 PARK_sw029_reverbFreqJitter "Parking assist sensors: sw029 reverb freq jitter";
CM_ SG_ 1486 PARK_sw031_sensorTemperature "Parking assist sensors: sw031 sensor temperature";
CM_ SG_ 1486 PARK_sw032_membraneDisconct "Parking assist sensors: sw032 membrane disconct";
CM_ SG_ 1486 PARK_sw032_dampResistorFail "Parking assist sensors: sw032 damp resistor fail";
CM_ SG_ 1486 PARK_sw032_resonanceDrift "Parking assist sensors: sw032 resonance drift";
CM_ SG_ 1486 PARK_sw032_sensorCRC "Parking assist sensors: sw032 sensor CRC";
CM_ SG_ 1486 PARK_sw032_recieveFailure "Parking assist sensors: sw032 recieve failure";
CM_ SG_ 1486 PARK_sw032_diagnosticTransferErr "Parking assist sensors: sw032 diagnostic transfer error";
CM_ SG_ 1486 PARK_sw033_linError "Parking assist sensors: sw033 lin error";
CM_ SG_ 1486 PARK_sw033_linBusError "Parking assist sensors: sw033 lin bus error";
CM_ SG_ 1486 PARK_sw033_linFrameCountError "Parking assist sensors: sw033 lin frame count error";
CM_ SG_ 1486 PARK_sw034_reverbPeriod "Parking assist sensors: sw034 reverb period";
CM_ SG_ 1486 PARK_sw034_reverbTime "Parking assist sensors: sw034 reverb time";
CM_ SG_ 1486 PARK_sw034_highAttenTime "Parking assist sensors: sw034 high atten time";
CM_ SG_ 1486 PARK_sw034_closeConstEcho "Parking assist sensors: sw034 close const echo";
CM_ SG_ 1486 PARK_sw034_lowAttenTime "Parking assist sensors: sw034 low atten time";
CM_ SG_ 1486 PARK_sw034_attenTimeJitter "Parking assist sensors: sw034 atten time jitter";
CM_ SG_ 1486 PARK_sw034_reverbFreqJitter "Parking assist sensors: sw034 reverb freq jitter";
CM_ SG_ 1486 PARK_sw036_sensorTemperature "Parking assist sensors: sw036 sensor temperature";
CM_ SG_ 1486 PARK_sw037_membraneDisconct "Parking assist sensors: sw037 membrane disconct";
CM_ SG_ 1486 PARK_sw037_dampResistorFail "Parking assist sensors: sw037 damp resistor fail";
CM_ SG_ 1486 PARK_sw037_resonanceDrift "Parking assist sensors: sw037 resonance drift";
CM_ SG_ 1486 PARK_sw037_sensorCRC "Parking assist sensors: sw037 sensor CRC";
CM_ SG_ 1486 PARK_sw037_recieveFailure "Parking assist sensors: sw037 recieve failure";
CM_ SG_ 1486 PARK_sw037_diagnosticTransferErr "Parking assist sensors: sw037 diagnostic transfer error";
CM_ SG_ 1486 PARK_sw038_linError "Parking assist sensors: sw038 lin error";
CM_ SG_ 1486 PARK_sw038_linBusError "Parking assist sensors: sw038 lin bus error";
CM_ SG_ 1486 PARK_sw038_linFrameCountError "Parking assist sensors: sw038 lin frame count error";
CM_ SG_ 1486 PARK_sw039_reverbPeriod "Parking assist sensors: sw039 reverb period";
CM_ SG_ 1486 PARK_sw039_reverbTime "Parking assist sensors: sw039 reverb time";
CM_ SG_ 1486 PARK_sw039_highAttenTime "Parking assist sensors: sw039 high atten time";
CM_ SG_ 1486 PARK_sw039_closeConstEcho "Parking assist sensors: sw039 close const echo";
CM_ SG_ 1486 PARK_sw039_lowAttenTime "Parking assist sensors: sw039 low atten time";
CM_ SG_ 1486 PARK_sw039_attenTimeJitter "Parking assist sensors: sw039 atten time jitter";
CM_ SG_ 1486 PARK_sw039_reverbFreqJitter "Parking assist sensors: sw039 reverb freq jitter";
CM_ SG_ 1486 PARK_sw041_sensorTemperature "Parking assist sensors: sw041 sensor temperature";
CM_ SG_ 1486 PARK_sw042_membraneDisconct "Parking assist sensors: sw042 membrane disconct";
CM_ SG_ 1486 PARK_sw042_dampResistorFail "Parking assist sensors: sw042 damp resistor fail";
CM_ SG_ 1486 PARK_sw042_resonanceDrift "Parking assist sensors: sw042 resonance drift";
CM_ SG_ 1486 PARK_sw042_sensorCRC "Parking assist sensors: sw042 sensor CRC";
CM_ SG_ 1486 PARK_sw042_recieveFailure "Parking assist sensors: sw042 recieve failure";
CM_ SG_ 1486 PARK_sw042_diagnosticTransferErr "Parking assist sensors: sw042 diagnostic transfer error";
CM_ SG_ 1486 PARK_sw043_linError "Parking assist sensors: sw043 lin error";
CM_ SG_ 1486 PARK_sw043_linBusError "Parking assist sensors: sw043 lin bus error";
CM_ SG_ 1486 PARK_sw043_linFrameCountError "Parking assist sensors: sw043 lin frame count error";
CM_ SG_ 1486 PARK_sw044_reverbPeriod "Parking assist sensors: sw044 reverb period";
CM_ SG_ 1486 PARK_sw044_reverbTime "Parking assist sensors: sw044 reverb time";
CM_ SG_ 1486 PARK_sw044_highAttenTime "Parking assist sensors: sw044 high atten time";
CM_ SG_ 1486 PARK_sw044_closeConstEcho "Parking assist sensors: sw044 close const echo";
CM_ SG_ 1486 PARK_sw044_lowAttenTime "Parking assist sensors: sw044 low atten time";
CM_ SG_ 1486 PARK_sw044_attenTimeJitter "Parking assist sensors: sw044 atten time jitter";
CM_ SG_ 1486 PARK_sw044_reverbFreqJitter "Parking assist sensors: sw044 reverb freq jitter";
CM_ SG_ 1486 PARK_sw046_sensorTemperature "Parking assist sensors: sw046 sensor temperature";
CM_ SG_ 1486 PARK_sw047_membraneDisconct "Parking assist sensors: sw047 membrane disconct";
CM_ SG_ 1486 PARK_sw047_dampResistorFail "Parking assist sensors: sw047 damp resistor fail";
CM_ SG_ 1486 PARK_sw047_resonanceDrift "Parking assist sensors: sw047 resonance drift";
CM_ SG_ 1486 PARK_sw047_sensorCRC "Parking assist sensors: sw047 sensor CRC";
CM_ SG_ 1486 PARK_sw047_recieveFailure "Parking assist sensors: sw047 recieve failure";
CM_ SG_ 1486 PARK_sw047_diagnosticTransferErr "Parking assist sensors: sw047 diagnostic transfer error";
CM_ SG_ 1486 PARK_sw048_linError "Parking assist sensors: sw048 lin error";
CM_ SG_ 1486 PARK_sw048_linBusError "Parking assist sensors: sw048 lin bus error";
CM_ SG_ 1486 PARK_sw048_linFrameCountError "Parking assist sensors: sw048 lin frame count error";
CM_ SG_ 1486 PARK_sw049_reverbPeriod "Parking assist sensors: sw049 reverb period";
CM_ SG_ 1486 PARK_sw049_reverbTime "Parking assist sensors: sw049 reverb time";
CM_ SG_ 1486 PARK_sw049_highAttenTime "Parking assist sensors: sw049 high atten time";
CM_ SG_ 1486 PARK_sw049_closeConstEcho "Parking assist sensors: sw049 close const echo";
CM_ SG_ 1486 PARK_sw049_lowAttenTime "Parking assist sensors: sw049 low atten time";
CM_ SG_ 1486 PARK_sw049_attenTimeJitter "Parking assist sensors: sw049 atten time jitter";
CM_ SG_ 1486 PARK_sw049_reverbFreqJitter "Parking assist sensors: sw049 reverb freq jitter";
CM_ SG_ 1486 PARK_sw051_sensorTemperature "Parking assist sensors: sw051 sensor temperature";
CM_ SG_ 1486 PARK_sw052_membraneDisconct "Parking assist sensors: sw052 membrane disconct";
CM_ SG_ 1486 PARK_sw052_dampResistorFail "Parking assist sensors: sw052 damp resistor fail";
CM_ SG_ 1486 PARK_sw052_resonanceDrift "Parking assist sensors: sw052 resonance drift";
CM_ SG_ 1486 PARK_sw052_sensorCRC "Parking assist sensors: sw052 sensor CRC";
CM_ SG_ 1486 PARK_sw052_recieveFailure "Parking assist sensors: sw052 recieve failure";
CM_ SG_ 1486 PARK_sw052_diagnosticTransferErr "Parking assist sensors: sw052 diagnostic transfer error";
CM_ SG_ 1486 PARK_sw053_linError "Parking assist sensors: sw053 lin error";
CM_ SG_ 1486 PARK_sw053_linBusError "Parking assist sensors: sw053 lin bus error";
CM_ SG_ 1486 PARK_sw053_linFrameCountError "Parking assist sensors: sw053 lin frame count error";
CM_ SG_ 1486 PARK_sw054_reverbPeriod "Parking assist sensors: sw054 reverb period";
CM_ SG_ 1486 PARK_sw054_reverbTime "Parking assist sensors: sw054 reverb time";
CM_ SG_ 1486 PARK_sw054_highAttenTime "Parking assist sensors: sw054 high atten time";
CM_ SG_ 1486 PARK_sw054_closeConstEcho "Parking assist sensors: sw054 close const echo";
CM_ SG_ 1486 PARK_sw054_lowAttenTime "Parking assist sensors: sw054 low atten time";
CM_ SG_ 1486 PARK_sw054_attenTimeJitter "Parking assist sensors: sw054 atten time jitter";
CM_ SG_ 1486 PARK_sw054_reverbFreqJitter "Parking assist sensors: sw054 reverb freq jitter";
CM_ SG_ 1486 PARK_sw056_sensorTemperature "Parking assist sensors: sw056 sensor temperature";
CM_ SG_ 1486 PARK_sw057_membraneDisconct "Parking assist sensors: sw057 membrane disconct";
CM_ SG_ 1486 PARK_sw057_dampResistorFail "Parking assist sensors: sw057 damp resistor fail";
CM_ SG_ 1486 PARK_sw057_resonanceDrift "Parking assist sensors: sw057 resonance drift";
CM_ SG_ 1486 PARK_sw057_sensorCRC "Parking assist sensors: sw057 sensor CRC";
CM_ SG_ 1486 PARK_sw057_recieveFailure "Parking assist sensors: sw057 recieve failure";
CM_ SG_ 1486 PARK_sw057_diagnosticTransferErr "Parking assist sensors: sw057 diagnostic transfer error";
CM_ SG_ 1486 PARK_sw058_linError "Parking assist sensors: sw058 lin error";
CM_ SG_ 1486 PARK_sw058_linBusError "Parking assist sensors: sw058 lin bus error";
CM_ SG_ 1486 PARK_sw058_linFrameCountError "Parking assist sensors: sw058 lin frame count error";
CM_ SG_ 1486 PARK_sw059_reverbPeriod "Parking assist sensors: sw059 reverb period";
CM_ SG_ 1486 PARK_sw059_reverbTime "Parking assist sensors: sw059 reverb time";
CM_ SG_ 1486 PARK_sw059_highAttenTime "Parking assist sensors: sw059 high atten time";
CM_ SG_ 1486 PARK_sw059_closeConstEcho "Parking assist sensors: sw059 close const echo";
CM_ SG_ 1486 PARK_sw059_lowAttenTime "Parking assist sensors: sw059 low atten time";
CM_ SG_ 1486 PARK_sw059_attenTimeJitter "Parking assist sensors: sw059 atten time jitter";
CM_ SG_ 1486 PARK_sw059_reverbFreqJitter "Parking assist sensors: sw059 reverb freq jitter";
CM_ SG_ 1486 PARK_sw061_voltage "Parking assist sensors: sw061 voltage";
CM_ SG_ 1486 PARK_sw063_voltage "Parking assist sensors: sw063 voltage";
CM_ SG_ 1486 PARK_sw064_faultCode "Parking assist sensors: sw064 fault code";
CM_ SG_ 1486 PARK_sw065_expectedCRC "Parking assist sensors: sw065 expected CRC";
CM_ SG_ 1486 PARK_sw065_calculatedCRC "Parking assist sensors: sw065 calculated CRC";
CM_ SG_ 1486 PARK_sw066_placeHolder "Parking assist sensors: sw066 place holder";
CM_ SG_ 1486 PARK_sw068_placeHolder "Parking assist sensors: sw068 place holder";
CM_ SG_ 1486 PARK_sw069_messageID "Parking assist sensors: sw069 message ID";
CM_ SG_ 1486 PARK_sw070_messageID "Parking assist sensors: sw070 message ID";
CM_ SG_ 1486 PARK_sw071_messageID "Parking assist sensors: sw071 message ID";
CM_ SG_ 1486 PARK_sw072_messageID "Parking assist sensors: sw072 message ID";
CM_ SG_ 1486 PARK_sw073_messageID "Parking assist sensors: sw073 message ID";
CM_ SG_ 1486 PARK_sw074_messageID "Parking assist sensors: sw074 message ID";
CM_ SG_ 1486 PARK_sw075_messageID "Parking assist sensors: sw075 message ID";
CM_ SG_ 1486 PARK_sw076_messageID "Parking assist sensors: sw076 message ID";
CM_ SG_ 1486 PARK_sw077_errorExp "Parking assist sensors: sw077 error exp";
CM_ SG_ 1486 PARK_sw077_errorRx "Parking assist sensors: sw077 error rx";
CM_ SG_ 1486 PARK_sw077_messageID "Parking assist sensors: sw077 message ID";
CM_ SG_ 1486 PARK_sw077_errorType "Parking assist sensors: sw077 error type";
CM_ SG_ 1486 PARK_sw078_errorExp "Parking assist sensors: sw078 error exp";
CM_ SG_ 1486 PARK_sw078_errorRx "Parking assist sensors: sw078 error rx";
CM_ SG_ 1486 PARK_sw078_messageID "Parking assist sensors: sw078 message ID";
CM_ SG_ 1486 PARK_sw078_errorType "Parking assist sensors: sw078 error type";
CM_ SG_ 1486 PARK_sw079_errorExp "Parking assist sensors: sw079 error exp";
CM_ SG_ 1486 PARK_sw079_errorRx "Parking assist sensors: sw079 error rx";
CM_ SG_ 1486 PARK_sw079_messageID "Parking assist sensors: sw079 message ID";
CM_ SG_ 1486 PARK_sw079_errorType "Parking assist sensors: sw079 error type";
CM_ SG_ 1486 PARK_sw080_errorExp "Parking assist sensors: sw080 error exp";
CM_ SG_ 1486 PARK_sw080_errorRx "Parking assist sensors: sw080 error rx";
CM_ SG_ 1486 PARK_sw080_messageID "Parking assist sensors: sw080 message ID";
CM_ SG_ 1486 PARK_sw080_errorType "Parking assist sensors: sw080 error type";
CM_ SG_ 1486 PARK_sw081_errorExp "Parking assist sensors: sw081 error exp";
CM_ SG_ 1486 PARK_sw081_errorRx "Parking assist sensors: sw081 error rx";
CM_ SG_ 1486 PARK_sw081_messageID "Parking assist sensors: sw081 message ID";
CM_ SG_ 1486 PARK_sw081_errorType "Parking assist sensors: sw081 error type";
CM_ SG_ 1486 PARK_sw082_errorExp "Parking assist sensors: sw082 error exp";
CM_ SG_ 1486 PARK_sw082_errorRx "Parking assist sensors: sw082 error rx";
CM_ SG_ 1486 PARK_sw082_messageID "Parking assist sensors: sw082 message ID";
CM_ SG_ 1486 PARK_sw082_errorType "Parking assist sensors: sw082 error type";
CM_ SG_ 1486 PARK_sw083_errorExp "Parking assist sensors: sw083 error exp";
CM_ SG_ 1486 PARK_sw083_errorRx "Parking assist sensors: sw083 error rx";
CM_ SG_ 1486 PARK_sw083_messageID "Parking assist sensors: sw083 message ID";
CM_ SG_ 1486 PARK_sw083_errorType "Parking assist sensors: sw083 error type";
CM_ SG_ 1486 PARK_sw084_errorExp "Parking assist sensors: sw084 error exp";
CM_ SG_ 1486 PARK_sw084_errorRx "Parking assist sensors: sw084 error rx";
CM_ SG_ 1486 PARK_sw084_messageID "Parking assist sensors: sw084 message ID";
CM_ SG_ 1486 PARK_sw084_errorType "Parking assist sensors: sw084 error type";
CM_ SG_ 1486 PARK_sw086_writeRetryCounter "Parking assist sensors: sw086 write retry counter";
CM_ SG_ 1486 PARK_sw086_readRetryCounter "Parking assist sensors: sw086 read retry counter";
CM_ SG_ 1486 PARK_sw086_currentErrorCode "Parking assist sensors: sw086 current error code";
CM_ SG_ 1486 PARK_sw087_s1_sensorType "Parking assist sensors: sw087 s1 sensor type; raw 3 = signal not available (SNA)";
CM_ SG_ 1486 PARK_sw087_s2_sensorType "Parking assist sensors: sw087 s2 sensor type; raw 3 = signal not available (SNA)";
CM_ SG_ 1486 PARK_sw087_s3_sensorType "Parking assist sensors: sw087 s3 sensor type; raw 3 = signal not available (SNA)";
CM_ SG_ 1486 PARK_sw087_s4_sensorType "Parking assist sensors: sw087 s4 sensor type; raw 3 = signal not available (SNA)";
CM_ SG_ 1486 PARK_sw087_s5_sensorType "Parking assist sensors: sw087 s5 sensor type; raw 3 = signal not available (SNA)";
CM_ SG_ 1486 PARK_sw087_s6_sensorType "Parking assist sensors: sw087 s6 sensor type; raw 3 = signal not available (SNA)";
CM_ SG_ 1486 PARK_sw087_s7_sensorType "Parking assist sensors: sw087 s7 sensor type; raw 3 = signal not available (SNA)";
CM_ SG_ 1486 PARK_sw087_s8_sensorType "Parking assist sensors: sw087 s8 sensor type; raw 3 = signal not available (SNA)";
CM_ SG_ 1486 PARK_sw087_s9_sensorType "Parking assist sensors: sw087 s9 sensor type; raw 3 = signal not available (SNA)";
CM_ SG_ 1486 PARK_sw087_s10_sensorType "Parking assist sensors: sw087 s10 sensor type; raw 3 = signal not available (SNA)";
CM_ SG_ 1486 PARK_sw087_s11_sensorType "Parking assist sensors: sw087 s11 sensor type; raw 3 = signal not available (SNA)";
CM_ SG_ 1486 PARK_sw087_s12_sensorType "Parking assist sensors: sw087 s12 sensor type; raw 3 = signal not available (SNA)";
CM_ BO_ 806 "Parking assist sensors message: info; frame length from the layout, not yet observed on a vehicle bus";
CM_ SG_ 806 PARK_infoIndex "Parking assist sensors: info index";
CM_ SG_ 806 PARK_infoBuildType "Parking assist sensors: info build type";
CM_ SG_ 806 PARK_infoComponentID "Parking assist sensors: info component ID";
CM_ SG_ 806 PARK_infoPcbaID "Parking assist sensors: info pcba ID";
CM_ SG_ 806 PARK_infoAssemblyID "Parking assist sensors: info assembly ID";
CM_ SG_ 806 PARK_infoUsageID "Parking assist sensors: info usage ID";
CM_ SG_ 806 PARK_infoApplicationCRC "Parking assist sensors: info application CRC";
CM_ SG_ 806 PARK_infoBootUdsProtoVersion "Parking assist sensors: info boot uds proto version";
CM_ SG_ 806 PARK_infoBootloaderCRC "Parking assist sensors: info bootloader CRC";
CM_ BO_ 846 "Parking assist sensors message: pas front middle; frame length from the layout, not yet observed on a vehicle bus";
CM_ SG_ 846 PARK_frontLeftMiddleRawDistData "Zone defined as -38 degrees -> +12 degrees, distance to object in units of centimeters; raw 255 = signal not available (SNA)";
CM_ SG_ 846 PARK_frontMiddleRawDistData "Zone defined as -12 degrees to +12 degrees, distance to object in units of centimeters; raw 255 = signal not available (SNA)";
CM_ SG_ 846 PARK_frontRightMiddleRawDistData "Zone defined +12 degrees to +38 degreees, distance to object in units of centimeters; raw 255 = signal not available (SNA)";
CM_ SG_ 846 PARK_pasFrontMiddleCounter "Parking assist sensors: pas front middle counter";
CM_ SG_ 846 PARK_pasFrontMiddleChecksum "Parking assist sensors: pas front middle checksum";
CM_ BO_ 862 "Parking assist sensors message: pas rear middle; frame length from the layout, not yet observed on a vehicle bus";
CM_ SG_ 862 PARK_rearLeftMiddleRawDistData "Zone defined as -124 degrees to -166 degrees, distance to object in units of centimeters; raw 255 = signal not available (SNA)";
CM_ SG_ 862 PARK_rearMiddleRawDistData "Zone defined as -166 degrees to +166 degrees, distance to object in units of centimeters; raw 255 = signal not available (SNA)";
CM_ SG_ 862 PARK_rearRightMiddleRawDistData "Zone defined as +166 degrees to +124 degrees, distance to object in units of centimeters; raw 255 = signal not available (SNA)";
CM_ SG_ 862 PARK_pasRearMiddleCounter "Parking assist sensors: pas rear middle counter";
CM_ SG_ 862 PARK_pasRearMiddleChecksum "Parking assist sensors: pas rear middle checksum";
CM_ BO_ 926 "Parking assist sensors message: pas sides; frame length from the layout, not yet observed on a vehicle bus";
CM_ SG_ 926 PARK_rightSideFrontRawDistData "Right side (from inside the car) towards the front of the car (split evenly between axles); raw 255 = signal not available (SNA)";
CM_ SG_ 926 PARK_rightSideRearRawDistData "Right side (from inside the car) towards the rear of the car (split evenly between axles); raw 255 = signal not available (SNA)";
CM_ SG_ 926 PARK_leftSideFrontRawDistData "Left side (from inside the car) towards the front of the car (split evenly between axles); raw 255 = signal not available (SNA)";
CM_ SG_ 926 PARK_leftSideRearRawDistData "Left side (from inside the car) towards the rear of the car (split evenly between axles); raw 255 = signal not available (SNA)";
CM_ SG_ 926 PARK_pasSidesCounter "Parking assist sensors: pas sides counter";
CM_ SG_ 926 PARK_pasSidesChecksum "Parking assist sensors: pas sides checksum";
CM_ BO_ 606 "Parking assist sensors message: psc env slot; frame length from the layout, not yet observed on a vehicle bus";
CM_ SG_ 606 PARK_pscEnvSlotType "Parking assist sensors: psc env slot type";
CM_ SG_ 606 PARK_pscLeftParallelObj1X "Parking assist sensors: psc left parallel obj1 x; raw 2047 = signal not available (SNA)";
CM_ SG_ 606 PARK_pscLeftParallelObj1Y "Parking assist sensors: psc left parallel obj1 y; raw 2047 = signal not available (SNA)";
CM_ SG_ 606 PARK_pscLeftParallelObj1Alpha "Parking assist sensors: psc left parallel obj1 alpha; raw 127 = signal not available (SNA)";
CM_ SG_ 606 PARK_pscLeftParallelObj2Y "Parking assist sensors: psc left parallel obj2 y; raw 2047 = signal not available (SNA)";
CM_ SG_ 606 PARK_pscLeftParallelObj2X "Parking assist sensors: psc left parallel obj2 x; raw 2047 = signal not available (SNA)";
CM_ SG_ 606 PARK_pscLeftParallelObj2Alpha "Parking assist sensors: psc left parallel obj2 alpha; raw 127 = signal not available (SNA)";
CM_ SG_ 606 PARK_pscLeftCrossObj1X "Parking assist sensors: psc left cross obj1 x; raw 2047 = signal not available (SNA)";
CM_ SG_ 606 PARK_pscLeftCrossObj1Y "Parking assist sensors: psc left cross obj1 y; raw 2047 = signal not available (SNA)";
CM_ SG_ 606 PARK_pscLeftCrossObj1Alpha "Parking assist sensors: psc left cross obj1 alpha; raw 127 = signal not available (SNA)";
CM_ SG_ 606 PARK_pscLeftCrossObj2Y "Parking assist sensors: psc left cross obj2 y; raw 2047 = signal not available (SNA)";
CM_ SG_ 606 PARK_pscLeftCrossObj2X "Parking assist sensors: psc left cross obj2 x; raw 2047 = signal not available (SNA)";
CM_ SG_ 606 PARK_pscLeftCrossObj2Alpha "Parking assist sensors: psc left cross obj2 alpha; raw 127 = signal not available (SNA)";
CM_ SG_ 606 PARK_pscRightParallelObj1X "Parking assist sensors: psc right parallel obj1 x; raw 2047 = signal not available (SNA)";
CM_ SG_ 606 PARK_pscRightParallelObj1Y "Parking assist sensors: psc right parallel obj1 y; raw 2047 = signal not available (SNA)";
CM_ SG_ 606 PARK_pscRightParallelObj1Alpha "Parking assist sensors: psc right parallel obj1 alpha; raw 127 = signal not available (SNA)";
CM_ SG_ 606 PARK_pscRightParallelObj2Y "Parking assist sensors: psc right parallel obj2 y; raw 2047 = signal not available (SNA)";
CM_ SG_ 606 PARK_pscRightParallelObj2X "Parking assist sensors: psc right parallel obj2 x; raw 2047 = signal not available (SNA)";
CM_ SG_ 606 PARK_pscRightParallelObj2Alpha "Parking assist sensors: psc right parallel obj2 alpha; raw 127 = signal not available (SNA)";
CM_ SG_ 606 PARK_pscRightCrossObj1X "Parking assist sensors: psc right cross obj1 x; raw 2047 = signal not available (SNA)";
CM_ SG_ 606 PARK_pscRightCrossObj1Y "Parking assist sensors: psc right cross obj1 y; raw 2047 = signal not available (SNA)";
CM_ SG_ 606 PARK_pscRightCrossObj1Alpha "Parking assist sensors: psc right cross obj1 alpha; raw 127 = signal not available (SNA)";
CM_ SG_ 606 PARK_pscRightCrossObj2Y "Parking assist sensors: psc right cross obj2 y; raw 2047 = signal not available (SNA)";
CM_ SG_ 606 PARK_pscRightCrossObj2X "Parking assist sensors: psc right cross obj2 x; raw 2047 = signal not available (SNA)";
CM_ SG_ 606 PARK_pscRightCrossObj2Alpha "Parking assist sensors: psc right cross obj2 alpha; raw 127 = signal not available (SNA)";
CM_ BO_ 542 "Parking assist sensors message: psc status; frame length from the layout, not yet observed on a vehicle bus";
CM_ SG_ 542 PARK_pscParkStatus "Parking assist sensors: psc park status; raw 7 = signal not available (SNA)";
CM_ SG_ 542 PARK_pscParkAbortReason "Parking assist sensors: psc park abort reason; raw 31 = signal not available (SNA)";
CM_ SG_ 542 PARK_pscParallelSpace "The existence and type of a parallel parking slot identified by the ultrasonics.";
CM_ SG_ 542 PARK_pscCrossSpace "The type and existence of perpendicular parking slot identified through the ultrasonics";
CM_ SG_ 542 PARK_pscParallelRightParkable "Whether or not there is a valid path into a parallel parking slot on the right; raw 3 = signal not available (SNA)";
CM_ SG_ 542 PARK_pscParallelLeftParkable "Whether or not there is a valid path into a parallel parking slot on the left; raw 3 = signal not available (SNA)";
CM_ SG_ 542 PARK_pscCrossRightParkable "Parking assist sensors: psc cross right parkable; raw 3 = signal not available (SNA)";
CM_ SG_ 542 PARK_pscMaxVelocity "Parking assist sensors: psc max velocity; raw 63 = signal not available (SNA)";
CM_ SG_ 542 PARK_pscCrossLeftParkable "Parking assist sensors: psc cross left parkable; raw 3 = signal not available (SNA)";
CM_ SG_ 542 PARK_pscParkInstruction "The control request from PARK ECU during autopark manuever; raw 7 = signal not available (SNA)";
CM_ SG_ 542 PARK_pscManeuverDistance "Real time updated path length from center of vehicle reference frame to desired center of vehicle at end of current parking manuever; raw 2047 = signal not available (SNA)";
CM_ SG_ 542 PARK_pscAngleActive "Parking assist sensors: psc angle active";
CM_ SG_ 542 PARK_pscAngleRequest "Parking assist sensors: psc angle request";
CM_ SG_ 542 PARK_pscStatusCounter "Parking assist sensors: psc status counter";
CM_ SG_ 542 PARK_pscStatusChecksum "Parking assist sensors: psc status checksum";
CM_ BO_ 590 "Parking assist sensors message: psc veh slot; frame length from the layout, not yet observed on a vehicle bus";
CM_ SG_ 590 PARK_pscVehSlotType "Parking assist sensors: psc veh slot type";
CM_ SG_ 590 PARK_pscLeftParallelVehX "Parking assist sensors: psc left parallel veh x; raw 2047 = signal not available (SNA)";
CM_ SG_ 590 PARK_pscLeftParallelVehY "Parking assist sensors: psc left parallel veh y; raw 2047 = signal not available (SNA)";
CM_ SG_ 590 PARK_pscLeftParallelPsi "Parking assist sensors: psc left parallel psi; raw 8191 = signal not available (SNA)";
CM_ SG_ 590 PARK_pscLeftParallelSizeX "Parking assist sensors: psc left parallel size x; raw 255 = signal not available (SNA)";
CM_ SG_ 590 PARK_pscLeftParallelSizeY "Parking assist sensors: psc left parallel size y; raw 255 = signal not available (SNA)";
CM_ SG_ 590 PARK_pscLeftCrossVehX "Parking assist sensors: psc left cross veh x; raw 2047 = signal not available (SNA)";
CM_ SG_ 590 PARK_pscLeftCrossVehY "Parking assist sensors: psc left cross veh y; raw 2047 = signal not available (SNA)";
CM_ SG_ 590 PARK_pscLeftCrossPsi "Parking assist sensors: psc left cross psi; raw 8191 = signal not available (SNA)";
CM_ SG_ 590 PARK_pscLeftCrossSizeX "Parking assist sensors: psc left cross size x; raw 255 = signal not available (SNA)";
CM_ SG_ 590 PARK_pscLeftCrossSizeY "Parking assist sensors: psc left cross size y; raw 255 = signal not available (SNA)";
CM_ SG_ 590 PARK_pscRightParallelVehX "Parking assist sensors: psc right parallel veh x; raw 2047 = signal not available (SNA)";
CM_ SG_ 590 PARK_pscRightParallelVehY "Parking assist sensors: psc right parallel veh y; raw 2047 = signal not available (SNA)";
CM_ SG_ 590 PARK_pscRightParallelPsi "Parking assist sensors: psc right parallel psi; raw 8191 = signal not available (SNA)";
CM_ SG_ 590 PARK_pscRightParallelSizeX "Parking assist sensors: psc right parallel size x; raw 255 = signal not available (SNA)";
CM_ SG_ 590 PARK_pscRightParallelSizeY "Parking assist sensors: psc right parallel size y; raw 255 = signal not available (SNA)";
CM_ SG_ 590 PARK_pscRightCrossVehX "Parking assist sensors: psc right cross veh x; raw 2047 = signal not available (SNA)";
CM_ SG_ 590 PARK_pscRightCrossVehY "Parking assist sensors: psc right cross veh y; raw 2047 = signal not available (SNA)";
CM_ SG_ 590 PARK_pscRightCrossPsi "Parking assist sensors: psc right cross psi; raw 8191 = signal not available (SNA)";
CM_ SG_ 590 PARK_pscRightCrossSizeX "Parking assist sensors: psc right cross size x; raw 255 = signal not available (SNA)";
CM_ SG_ 590 PARK_pscRightCrossSizeY "Parking assist sensors: psc right cross size y; raw 255 = signal not available (SNA)";
CM_ BO_ 526 "Parking assist sensors message: sdi front; frame length from the layout, not yet observed on a vehicle bus";
CM_ SG_ 526 PARK_sdiSensor1RawDistData "Parking assist sensors: sdi sensor1 raw dist data; raw 511 = signal not available (SNA)";
CM_ SG_ 526 PARK_sdiSensor2RawDistData "Parking assist sensors: sdi sensor2 raw dist data; raw 511 = signal not available (SNA)";
CM_ SG_ 526 PARK_sdiSensor3RawDistData "Parking assist sensors: sdi sensor3 raw dist data; raw 511 = signal not available (SNA)";
CM_ SG_ 526 PARK_sdiSensor4RawDistData "Parking assist sensors: sdi sensor4 raw dist data; raw 511 = signal not available (SNA)";
CM_ SG_ 526 PARK_sdiSensor5RawDistData "Parking assist sensors: sdi sensor5 raw dist data; raw 511 = signal not available (SNA)";
CM_ SG_ 526 PARK_sdiSensor6RawDistData "Parking assist sensors: sdi sensor6 raw dist data; raw 511 = signal not available (SNA)";
CM_ SG_ 526 PARK_sdiFrontCounter "Parking assist sensors: sdi front counter";
CM_ SG_ 526 PARK_sdiFrontChecksum "Parking assist sensors: sdi front checksum";
CM_ BO_ 558 "Parking assist sensors message: sdi rear; frame length from the layout, not yet observed on a vehicle bus";
CM_ SG_ 558 PARK_sdiSensor7RawDistData "Parking assist sensors: sdi sensor7 raw dist data; raw 511 = signal not available (SNA)";
CM_ SG_ 558 PARK_sdiSensor8RawDistData "Parking assist sensors: sdi sensor8 raw dist data; raw 511 = signal not available (SNA)";
CM_ SG_ 558 PARK_sdiSensor9RawDistData "Parking assist sensors: sdi sensor9 raw dist data; raw 511 = signal not available (SNA)";
CM_ SG_ 558 PARK_sdiSensor10RawDistData "Parking assist sensors: sdi sensor10 raw dist data; raw 511 = signal not available (SNA)";
CM_ SG_ 558 PARK_sdiSensor11RawDistData "Parking assist sensors: sdi sensor11 raw dist data; raw 511 = signal not available (SNA)";
CM_ SG_ 558 PARK_sdiSensor12RawDistData "Parking assist sensors: sdi sensor12 raw dist data; raw 511 = signal not available (SNA)";
CM_ SG_ 558 PARK_sdiRearCounter "Parking assist sensors: sdi rear counter";
CM_ SG_ 558 PARK_sdiRearChecksum "Parking assist sensors: sdi rear checksum";
CM_ BO_ 814 "Parking assist sensors message: sensor status front; frame length from the layout, not yet observed on a vehicle bus";
CM_ SG_ 814 PARK_frontRightSensorState "Reports the state of the front right ultrasonic sensor; raw 3 = signal not available (SNA)";
CM_ SG_ 814 PARK_frontRightMiddleSensorState "Reports the state of the front right middle ultrasonic sensor; raw 3 = signal not available (SNA)";
CM_ SG_ 814 PARK_frontLeftMiddleSensorState "Reports the state of the front left middle ultrasonic sensor; raw 3 = signal not available (SNA)";
CM_ SG_ 814 PARK_frontLeftSensorState "Reports the state of the front left ultrasonic sensor; raw 3 = signal not available (SNA)";
CM_ SG_ 814 PARK_frontLeftRawDistData "Zone defined as -90 degrees -> -38 degrees, distance to object in units of centimeters; raw 255 = signal not available (SNA)";
CM_ SG_ 814 PARK_frontRightRawDistData "Zone defined as +38 degrees -> +90 degrees, distance to object in units of centimeters; raw 255 = signal not available (SNA)";
CM_ SG_ 814 PARK_systemStatusFront "Parking assist sensors: system status front; raw 3 = signal not available (SNA)";
CM_ SG_ 814 PARK_frontDtcPresent "Parking assist sensors: front dtc present; raw 3 = signal not available (SNA)";
CM_ SG_ 814 PARK_sensorStatusFrontCounter "Parking assist sensors: sensor status front counter";
CM_ SG_ 814 PARK_sensorStatusFrontChecksum "Parking assist sensors: sensor status front checksum";
CM_ BO_ 830 "Parking assist sensors message: sensor status rear; frame length from the layout, not yet observed on a vehicle bus";
CM_ SG_ 830 PARK_rearRightSensorState "Reports the state of the rear right ultrasonic sensor; raw 3 = signal not available (SNA)";
CM_ SG_ 830 PARK_rearRightMiddleSensorState "Reports the state of the rear right middle ultrasonic sensor; raw 3 = signal not available (SNA)";
CM_ SG_ 830 PARK_rearLeftMiddleSensorState "Reports the state of the rear left middle ultrasonic sensor; raw 3 = signal not available (SNA)";
CM_ SG_ 830 PARK_rearLeftSensorState "Reports the state of the rear left ultrasonic sensor; raw 3 = signal not available (SNA)";
CM_ SG_ 830 PARK_rearLeftRawDistData "Zone defined as -90 degrees to -125 degrees, distance to object in units of centimeters; raw 255 = signal not available (SNA)";
CM_ SG_ 830 PARK_rearRightRawDistData "Zone defined as +125 degrees to +90 degrees, distance to object in units of centimeters; raw 255 = signal not available (SNA)";
CM_ SG_ 830 PARK_systemStatusRear "Parking assist sensors: system status rear; raw 3 = signal not available (SNA)";
CM_ SG_ 830 PARK_rearDtcPresent "Parking assist sensors: rear dtc present; raw 3 = signal not available (SNA)";
CM_ SG_ 830 PARK_sensorStatusRearCounter "Parking assist sensors: sensor status rear counter";
CM_ SG_ 830 PARK_sensorStatusRearChecksum "Parking assist sensors: sensor status rear checksum";
CM_ BO_ 798 "Parking assist sensors message: status; frame length from the layout, not yet observed on a vehicle bus";
CM_ SG_ 798 PARK_status "Indicates status of park assist function; raw 3 = signal not available (SNA)";
CM_ SG_ 798 PARK_serviceRequest "Indicates whether or not PARK sensors/ECU require service; raw 3 = signal not available (SNA)";
CM_ SG_ 798 PARK_systemDtcPresent "Boolean indicating whether or not there is a DTC present; raw 3 = signal not available (SNA)";
CM_ SG_ 798 PARK_statusCounter "Parking assist sensors: status counter";
CM_ SG_ 798 PARK_statusChecksum "Parking assist sensors: status checksum";
CM_ SG_ 798 PARK_majorVersion "Parking assist sensors: major version; raw 255 = signal not available (SNA)";
CM_ SG_ 798 PARK_minorVersion "Parking assist sensors: minor version; raw 255 = signal not available (SNA)";
CM_ SG_ 798 PARK_subMinorVersion "Parking assist sensors: sub minor version; raw 255 = signal not available (SNA)";
BA_DEF_ BO_ "GenMsgCycleTime" INT 0 3600000;
BA_DEF_ BO_ "GenMsgSendType" ENUM "Cyclic","NotUsed","NotUsed","NotUsed","NotUsed","NotUsed","NotUsed","IfActive","NoMsgSendType","NotUsed";
BA_DEF_ BO_ "VFrameFormat" ENUM "StandardCAN","ExtendedCAN","reserved","J1939PG","reserved","reserved","reserved","reserved","reserved","reserved","reserved","reserved","reserved","reserved","StandardCAN_FD","ExtendedCAN_FD";
BA_DEF_ BO_ "CANFD_BRS" ENUM "0","1";
BA_DEF_ SG_ "GenSigSNA" STRING;
BA_DEF_ SG_ "SystemSignalLongSymbol" STRING;
BA_DEF_ SG_ "Confidence" ENUM "validated","plausible","layout-only","contradicted";
BA_DEF_DEF_ "GenMsgCycleTime" 0;
BA_DEF_DEF_ "GenMsgSendType" "NoMsgSendType";
BA_DEF_DEF_ "VFrameFormat" "StandardCAN";
BA_DEF_DEF_ "CANFD_BRS" "1";
BA_DEF_DEF_ "GenSigSNA" "";
BA_DEF_DEF_ "SystemSignalLongSymbol" "";
BA_DEF_DEF_ "Confidence" "layout-only";
BA_ "GenMsgCycleTime" BO_ 841 1000;
BA_ "GenMsgSendType" BO_ 841 0;
BA_ "GenMsgCycleTime" BO_ 1082 1000;
BA_ "GenMsgSendType" BO_ 1082 0;
BA_ "GenMsgCycleTime" BO_ 977 1000;
BA_ "GenMsgSendType" BO_ 977 0;
BA_ "GenMsgCycleTime" BO_ 785 1000;
BA_ "GenMsgSendType" BO_ 785 0;
BA_ "GenMsgCycleTime" BO_ 920 1000;
BA_ "GenMsgSendType" BO_ 920 0;
BA_ "GenMsgCycleTime" BO_ 805 10000;
BA_ "GenMsgSendType" BO_ 805 0;
BA_ "GenMsgCycleTime" BO_ 813 10000;
BA_ "GenMsgSendType" BO_ 813 0;
BA_ "GenMsgCycleTime" BO_ 828 10000;
BA_ "GenMsgSendType" BO_ 828 0;
BA_ "GenMsgCycleTime" BO_ 806 1000;
BA_ "GenMsgSendType" BO_ 806 0;
BA_ "GenMsgCycleTime" BO_ 846 100;
BA_ "GenMsgSendType" BO_ 846 0;
BA_ "GenMsgCycleTime" BO_ 862 100;
BA_ "GenMsgSendType" BO_ 862 0;
BA_ "GenMsgCycleTime" BO_ 926 100;
BA_ "GenMsgSendType" BO_ 926 0;
BA_ "GenMsgCycleTime" BO_ 606 100;
BA_ "GenMsgSendType" BO_ 606 0;
BA_ "GenMsgCycleTime" BO_ 542 40;
BA_ "GenMsgSendType" BO_ 542 0;
BA_ "GenMsgCycleTime" BO_ 590 100;
BA_ "GenMsgSendType" BO_ 590 0;
BA_ "GenMsgCycleTime" BO_ 526 40;
BA_ "GenMsgSendType" BO_ 526 0;
BA_ "GenMsgCycleTime" BO_ 558 40;
BA_ "GenMsgSendType" BO_ 558 0;
BA_ "GenMsgCycleTime" BO_ 814 100;
BA_ "GenMsgSendType" BO_ 814 0;
BA_ "GenMsgCycleTime" BO_ 830 100;
BA_ "GenMsgSendType" BO_ 830 0;
BA_ "GenMsgCycleTime" BO_ 798 500;
BA_ "GenMsgSendType" BO_ 798 0;
BA_ "Confidence" SG_ 977 EPAS3S_appliedAngleOffset 0;
BA_ "Confidence" SG_ 977 EPAS3S_calculatedAngleOffset 0;
BA_ "Confidence" SG_ 977 EPAS3S_resyncStatus 0;
BA_ "Confidence" SG_ 977 EPAS3S_pullDriftLongTermTrq 0;
BA_ "Confidence" SG_ 977 EPAS3S_pullDriftCompTrq 0;
BA_ "Confidence" SG_ 977 EPAS3S_learnedSCCMOffset 0;
BA_ "Confidence" SG_ 785 EPAS3S_infoIndex 1;
BA_ "Confidence" SG_ 785 EPAS3S_infoBuildType 0;
BA_ "Confidence" SG_ 785 EPAS3S_infoComponentID 0;
BA_ "Confidence" SG_ 785 EPAS3S_infoPcbaID 0;
BA_ "Confidence" SG_ 785 EPAS3S_infoAssemblyID 0;
BA_ "Confidence" SG_ 785 EPAS3S_infoUsageID 0;
BA_ "Confidence" SG_ 785 EPAS3S_infoApplicationCRC 0;
BA_ "Confidence" SG_ 785 EPAS3S_infoBootUdsProtoVersion 0;
BA_ "Confidence" SG_ 785 EPAS3S_infoBootloaderCRC 0;
BA_ "Confidence" SG_ 785 EPAS3S_infoSubcomponent2 0;
BA_ "Confidence" SG_ 920 EPASTS_matrixIndex 1;
BA_ "SystemSignalLongSymbol" SG_ 920 EPASTS_a001_adcCalibrationOrInit "EPASTS_a001_adcCalibrationOrInitFail";
BA_ "SystemSignalLongSymbol" SG_ 920 EPASTS_a005_scpUnknownResetSourc "EPASTS_a005_scpUnknownResetSource";
BA_ "SystemSignalLongSymbol" SG_ 920 EPASTS_a006_swrhResetByInvalidEr "EPASTS_a006_swrhResetByInvalidErrid";
BA_ "SystemSignalLongSymbol" SG_ 920 EPASTS_a009_mcusscLbistPermanent "EPASTS_a009_mcusscLbistPermanentFail";
BA_ "SystemSignalLongSymbol" SG_ 920 EPASTS_a010_svcIncompatibleSwVer "EPASTS_a010_svcIncompatibleSwVersions";
BA_ "SystemSignalLongSymbol" SG_ 920 EPASTS_a013_mcusscSffMonitoringF "EPASTS_a013_mcusscSffMonitoringFailed";
BA_ "SystemSignalLongSymbol" SG_ 920 EPASTS_a014_mcusscSffMonitoringM "EPASTS_a014_mcusscSffMonitoringMia";
BA_ "SystemSignalLongSymbol" SG_ 920 EPASTS_a015_mcusscCsErrorCheckFa "EPASTS_a015_mcusscCsErrorCheckFail";
BA_ "SystemSignalLongSymbol" SG_ 920 EPASTS_a016_mcufcCsErrorCheckFai "EPASTS_a016_mcufcCsErrorCheckFail";
BA_ "SystemSignalLongSymbol" SG_ 920 EPASTS_a017_stmdStmPlausibilityC "EPASTS_a017_stmdStmPlausibilityCheckErr";
BA_ "SystemSignalLongSymbol" SG_ 920 EPASTS_a019_rsthHwResetInfoCorru "EPASTS_a019_rsthHwResetInfoCorruptionCheck";
BA_ "SystemSignalLongSymbol" SG_ 920 EPASTS_a020_mcusscEolEcuIdIntegr "EPASTS_a020_mcusscEolEcuIdIntegritiyFail";
BA_ "SystemSignalLongSymbol" SG_ 920 EPASTS_a022_swrhSwResetInfoCorru "EPASTS_a022_swrhSwResetInfoCorruptionCheck";
BA_ "SystemSignalLongSymbol" SG_ 920 EPASTS_a028_smuhNonInitDataCorru "EPASTS_a028_smuhNonInitDataCorruption";
BA_ "SystemSignalLongSymbol" SG_ 920 EPASTS_a029_smuhSmuCoreCntErrorT "EPASTS_a029_smuhSmuCoreCntErrorTestFail";
BA_ "SystemSignalLongSymbol" SG_ 920 EPASTS_a031_pmsProductionModeFai "EPASTS_a031_pmsProductionModeFailed";
BA_ "SystemSignalLongSymbol" SG_ 920 EPASTS_a033_icsvcPswVersionMisma "EPASTS_a033_icsvcPswVersionMismatch";
BA_ "SystemSignalLongSymbol" SG_ 920 EPASTS_a038_csohCh1CsErrorErrAtR "EPASTS_a038_csohCh1CsErrorErrAtReset";
BA_ "SystemSignalLongSymbol" SG_ 920 EPASTS_a039_csohCh2CsErrorErrAtR "EPASTS_a039_csohCh2CsErrorErrAtReset";
BA_ "SystemSignalLongSymbol" SG_ 920 EPASTS_a040_swrhLimitedResetRetr "EPASTS_a040_swrhLimitedResetRetriesExpired";
BA_ "SystemSignalLongSymbol" SG_ 920 EPASTS_a041_imcmCoreConfiguratio "EPASTS_a041_imcmCoreConfigurationMismatch";
BA_ "SystemSignalLongSymbol" SG_ 920 EPASTS_a045_psumSbcBandgapVoltEr "EPASTS_a045_psumSbcBandgapVoltErr";
BA_ "SystemSignalLongSymbol" SG_ 920 EPASTS_a046_mcusscOscillatorNotR "EPASTS_a046_mcusscOscillatorNotReliable";
BA_ "SystemSignalLongSymbol" SG_ 920 EPASTS_a052_ermSdcInputBufferOve "EPASTS_a052_ermSdcInputBufferOverflow";
BA_ "SystemSignalLongSymbol" SG_ 920 EPASTS_a053_adcUnexpectedNumOfDa "EPASTS_a053_adcUnexpectedNumOfData";
BA_ "SystemSignalLongSymbol" SG_ 920 EPASTS_a056_amGduConfigCsErrorCh "EPASTS_a056_amGduConfigCsErrorCheck";
BA_ "SystemSignalLongSymbol" SG_ 920 EPASTS_a067_tspmPowermoduleTempI "EPASTS_a067_tspmPowermoduleTempImplausible";
BA_ "SystemSignalLongSymbol" SG_ 920 EPASTS_a068_rsthCoreRedundancyEr "EPASTS_a068_rsthCoreRedundancyErr";
BA_ "SystemSignalLongSymbol" SG_ 920 EPASTS_a069_rsthCoreTempOutOfRan "EPASTS_a069_rsthCoreTempOutOfRangeHwCheck";
BA_ "SystemSignalLongSymbol" SG_ 920 EPASTS_a072_rsthFlashUncorrEccOr "EPASTS_a072_rsthFlashUncorrEccOrOvfl";
BA_ "SystemSignalLongSymbol" SG_ 920 EPASTS_a075_rsthUnusedOtherModul "EPASTS_a075_rsthUnusedOtherModuleAlarm";
BA_ "SystemSignalLongSymbol" SG_ 920 EPASTS_a081_exchFloatingPointExc "EPASTS_a081_exchFloatingPointException";
BA_ "SystemSignalLongSymbol" SG_ 920 EPASTS_a083_tdaDclinkcapacitorTe "EPASTS_a083_tdaDclinkcapacitorTempChecker";
BA_ "SystemSignalLongSymbol" SG_ 920 EPASTS_a085_amGduSwitchOffTestBy "EPASTS_a085_amGduSwitchOffTestByMcu";
BA_ "SystemSignalLongSymbol" SG_ 920 EPASTS_a088_tedMainboardTempChec "EPASTS_a088_tedMainboardTempChecker";
BA_ "SystemSignalLongSymbol" SG_ 920 EPASTS_a089_tedRevercebattfetjun "EPASTS_a089_tedRevercebattfetjunctionTempChecker";
BA_ "SystemSignalLongSymbol" SG_ 920 EPASTS_a091_bvpBattVoltCrossChkF "EPASTS_a091_bvpBattVoltCrossChkFailed";
BA_ "SystemSignalLongSymbol" SG_ 920 EPASTS_a092_amGduSwitchOffTestBy "EPASTS_a092_amGduSwitchOffTestBySbc";
BA_ "SystemSignalLongSymbol" SG_ 920 EPASTS_a093_sctpTsuSingleStaticF "EPASTS_a093_sctpTsuSingleStaticFail";
BA_ "SystemSignalLongSymbol" SG_ 920 EPASTS_a094_sctpTsuMultipleStati "EPASTS_a094_sctpTsuMultipleStaticFail";
BA_ "SystemSignalLongSymbol" SG_ 920 EPASTS_a095_mdModelBasedMotorInt "EPASTS_a095_mdModelBasedMotorIntegrityCheck";
BA_ "SystemSignalLongSymbol" SG_ 920 EPASTS_a096_rppRpsSingleStaticFa "EPASTS_a096_rppRpsSingleStaticFail";
BA_ "SystemSignalLongSymbol" SG_ 920 EPASTS_a097_rppRpsMultipleStatic "EPASTS_a097_rppRpsMultipleStaticFail";
BA_ "SystemSignalLongSymbol" SG_ 920 EPASTS_a099_mcdTorqueMismatchFau "EPASTS_a099_mcdTorqueMismatchFault";
BA_ "SystemSignalLongSymbol" SG_ 920 EPASTS_a103_exhaUnusedInterruptC "EPASTS_a103_exhaUnusedInterruptCallException";
BA_ "SystemSignalLongSymbol" SG_ 920 EPASTS_a105_exhaSriBusErrExcepti "EPASTS_a105_exhaSriBusErrException";
BA_ "SystemSignalLongSymbol" SG_ 920 EPASTS_a106_exhaSpbBusErrExcepti "EPASTS_a106_exhaSpbBusErrException";
BA_ "SystemSignalLongSymbol" SG_ 920 EPASTS_a107_exhaOtherNmiExceptio "EPASTS_a107_exhaOtherNmiException";
BA_ "SystemSignalLongSymbol" SG_ 920 EPASTS_a108_exhaInternalProtecti "EPASTS_a108_exhaInternalProtectionException";
BA_ "SystemSignalLongSymbol" SG_ 920 EPASTS_a109_exhaSysBusOrPeriphEr "EPASTS_a109_exhaSysBusOrPeriphErrException";
BA_ "SystemSignalLongSymbol" SG_ 920 EPASTS_a110_amPhaseRelaySwitchOf "EPASTS_a110_amPhaseRelaySwitchOffTest";
BA_ "SystemSignalLongSymbol" SG_ 920 EPASTS_a111_amCurrentSensingDisc "EPASTS_a111_amCurrentSensingDisconnection";
BA_ "SystemSignalLongSymbol" SG_ 920 EPASTS_a112_rsthSafetyFlipflopEr "EPASTS_a112_rsthSafetyFlipflopErr";
BA_ "SystemSignalLongSymbol" SG_ 920 EPASTS_a113_rsthUncorrectableEnd "EPASTS_a113_rsthUncorrectableEndToEndBusErr";
BA_ "SystemSignalLongSymbol" SG_ 920 EPASTS_a115_mcusscLbistSingleFai "EPASTS_a115_mcusscLbistSingleFail";
BA_ "SystemSignalLongSymbol" SG_ 920 EPASTS_a116_mrccStartupRegCsErro "EPASTS_a116_mrccStartupRegCsErrorStaticErr";
BA_ "SystemSignalLongSymbol" SG_ 920 EPASTS_a117_mrccStartupRegCsErro "EPASTS_a117_mrccStartupRegCsErrorTransientErr";
BA_ "SystemSignalLongSymbol" SG_ 920 EPASTS_a118_mcusscFlashCsErrorEr "EPASTS_a118_mcusscFlashCsErrorErr";
BA_ "SystemSignalLongSymbol" SG_ 920 EPASTS_a119_mcusscFlashEccCritic "EPASTS_a119_mcusscFlashEccCriticalErr";
BA_ "SystemSignalLongSymbol" SG_ 920 EPASTS_a120_mcusscFlashEccLatent "EPASTS_a120_mcusscFlashEccLatentErr";
BA_ "SystemSignalLongSymbol" SG_ 920 EPASTS_a124_mcusscMbistEccTransi "EPASTS_a124_mcusscMbistEccTransientErr";
BA_ "SystemSignalLongSymbol" SG_ 920 EPASTS_a127_exchAdditionalExcept "EPASTS_a127_exchAdditionalExceptionAfterRst";
BA_ "SystemSignalLongSymbol" SG_ 920 EPASTS_a128_exchExceptionStopRes "EPASTS_a128_exchExceptionStopRestart";
BA_ "SystemSignalLongSymbol" SG_ 920 EPASTS_a129_exchAdditionalExcept "EPASTS_a129_exchAdditionalExceptionStopRestart";
BA_ "SystemSignalLongSymbol" SG_ 920 EPASTS_a131_exchGuardedResetAfte "EPASTS_a131_exchGuardedResetAfterPartitionStop";
BA_ "SystemSignalLongSymbol" SG_ 920 EPASTS_a132_mcusscNotSupportedMc "EPASTS_a132_mcusscNotSupportedMcu";
BA_ "SystemSignalLongSymbol" SG_ 920 EPASTS_a133_mcusscLbistEcuIdIsNo "EPASTS_a133_mcusscLbistEcuIdIsNotSupported";
BA_ "SystemSignalLongSymbol" SG_ 920 EPASTS_a134_osehGuardedResetAfte "EPASTS_a134_osehGuardedResetAfterErrWithoutReset";
BA_ "SystemSignalLongSymbol" SG_ 920 EPASTS_a135_tmpsfetjCalculationO "EPASTS_a135_tmpsfetjCalculationOverflowErr";
BA_ "SystemSignalLongSymbol" SG_ 920 EPASTS_a137_osehErrWithoutImmedi "EPASTS_a137_osehErrWithoutImmediateReset";
BA_ "SystemSignalLongSymbol" SG_ 920 EPASTS_a138_osehAdditionalErrWit "EPASTS_a138_osehAdditionalErrWithoutImmReset";
BA_ "SystemSignalLongSymbol" SG_ 920 EPASTS_a142_tedEmifilterDmcTempC "EPASTS_a142_tedEmifilterDmcTempChecker";
BA_ "SystemSignalLongSymbol" SG_ 920 EPASTS_a143_tedEmifilterCmcTempC "EPASTS_a143_tedEmifilterCmcTempChecker";
BA_ "SystemSignalLongSymbol" SG_ 920 EPASTS_a145_mriPeripheralRaminit "EPASTS_a145_mriPeripheralRaminitFailed";
BA_ "SystemSignalLongSymbol" SG_ 920 EPASTS_a148_mrccExitFromStandbyD "EPASTS_a148_mrccExitFromStandbyDetected";
BA_ "SystemSignalLongSymbol" SG_ 920 EPASTS_a149_amReversibleEmergenc "EPASTS_a149_amReversibleEmergencyOffRequested";
BA_ "SystemSignalLongSymbol" SG_ 920 EPASTS_a150_amExternalEmergencyO "EPASTS_a150_amExternalEmergencyOffRequested";
BA_ "SystemSignalLongSymbol" SG_ 920 EPASTS_a151_amPermanentEmergency "EPASTS_a151_amPermanentEmergencyOffRequested";
BA_ "SystemSignalLongSymbol" SG_ 920 EPASTS_a152_exchFlashEccExceptio "EPASTS_a152_exchFlashEccException";
BA_ "SystemSignalLongSymbol" SG_ 920 EPASTS_a153_sdsmBlockSelectorInv "EPASTS_a153_sdsmBlockSelectorInvalid";
BA_ "SystemSignalLongSymbol" SG_ 920 EPASTS_a154_sdsmCsErrorInvalidPr "EPASTS_a154_sdsmCsErrorInvalidPrimary";
BA_ "SystemSignalLongSymbol" SG_ 920 EPASTS_a156_amIntSerialErrSafety "EPASTS_a156_amIntSerialErrSafetyReset";
BA_ "SystemSignalLongSymbol" SG_ 920 EPASTS_a158_amGduFailDuringRecov "EPASTS_a158_amGduFailDuringRecovery";
BA_ "SystemSignalLongSymbol" SG_ 920 EPASTS_a159_exchFlashWordlineTra "EPASTS_a159_exchFlashWordlineTransientErr";
BA_ "SystemSignalLongSymbol" SG_ 920 EPASTS_a160_rsthCpu1UnexpectedAl "EPASTS_a160_rsthCpu1UnexpectedAlarm";
BA_ "SystemSignalLongSymbol" SG_ 920 EPASTS_a161_tdaRelayfetjunctionT "EPASTS_a161_tdaRelayfetjunctionTempChecker";
BA_ "SystemSignalLongSymbol" SG_ 920 EPASTS_a162_tdaBridgefetjunction "EPASTS_a162_tdaBridgefetjunctionTempChecker";
BA_ "SystemSignalLongSymbol" SG_ 920 EPASTS_a163_tdaPowermoduleTempCh "EPASTS_a163_tdaPowermoduleTempChecker";
BA_ "SystemSignalLongSymbol" SG_ 920 EPASTS_a164_tdaBattfetjunctionTe "EPASTS_a164_tdaBattfetjunctionTempChecker";
BA_ "SystemSignalLongSymbol" SG_ 920 EPASTS_a165_tdaDcbusshuntTempChe "EPASTS_a165_tdaDcbusshuntTempChecker";
BA_ "SystemSignalLongSymbol" SG_ 920 EPASTS_a166_tdaPhasecurrentshunt "EPASTS_a166_tdaPhasecurrentshuntTempChecker";
BA_ "SystemSignalLongSymbol" SG_ 920 EPASTS_a167_iccd1ErrQueueOverflo "EPASTS_a167_iccd1ErrQueueOverflow";
BA_ "SystemSignalLongSymbol" SG_ 920 EPASTS_a172_pmpElangMotorcurrent "EPASTS_a172_pmpElangMotorcurrentAge";
BA_ "SystemSignalLongSymbol" SG_ 920 EPASTS_a175_exchFlashStoredConfi "EPASTS_a175_exchFlashStoredConfigErr";
BA_ "SystemSignalLongSymbol" SG_ 920 EPASTS_a176_exchCpu1ExceptionRes "EPASTS_a176_exchCpu1ExceptionReset";
BA_ "SystemSignalLongSymbol" SG_ 920 EPASTS_a179_tedMotorcoilTempChec "EPASTS_a179_tedMotorcoilTempChecker";
BA_ "SystemSignalLongSymbol" SG_ 920 EPASTS_a180_dmDeadlineViolationC "EPASTS_a180_dmDeadlineViolationC1";
BA_ "SystemSignalLongSymbol" SG_ 920 EPASTS_a181_dmDeadlineViolationC "EPASTS_a181_dmDeadlineViolationC1";
BA_ "SystemSignalLongSymbol" SG_ 920 EPASTS_a184_sbcmCommBufferOverfl "EPASTS_a184_sbcmCommBufferOverflow";
BA_ "SystemSignalLongSymbol" SG_ 920 EPASTS_a185_sbcscpQAWatchdogRese "EPASTS_a185_sbcscpQAWatchdogReset";
BA_ "SystemSignalLongSymbol" SG_ 920 EPASTS_a186_wdhCommBufferOverflo "EPASTS_a186_wdhCommBufferOverflow";
BA_ "SystemSignalLongSymbol" SG_ 920 EPASTS_a188_epmCommBufferOverflo "EPASTS_a188_epmCommBufferOverflow";
BA_ "SystemSignalLongSymbol" SG_ 920 EPASTS_a190_sbchCommBufferOverfl "EPASTS_a190_sbchCommBufferOverflow";
BA_ "SystemSignalLongSymbol" SG_ 920 EPASTS_a191_sbcscpVcp2VucVoltFai "EPASTS_a191_sbcscpVcp2VucVoltFail";
BA_ "SystemSignalLongSymbol" SG_ 920 EPASTS_a196_topEolTasOffsetInval "EPASTS_a196_topEolTasOffsetInvalid";
BA_ "SystemSignalLongSymbol" SG_ 920 EPASTS_a200_ammInputBufferOverfl "EPASTS_a200_ammInputBufferOverflow";
BA_ "SystemSignalLongSymbol" SG_ 920 EPASTS_a201_ammOutputBufferOverf "EPASTS_a201_ammOutputBufferOverflow";
BA_ "SystemSignalLongSymbol" SG_ 920 EPASTS_a202_ohnvmpStoredOffsetLo "EPASTS_a202_ohnvmpStoredOffsetLost";
BA_ "SystemSignalLongSymbol" SG_ 920 EPASTS_a206_fdrOclPartialBlockin "EPASTS_a206_fdrOclPartialBlocking";
BA_ "SystemSignalLongSymbol" SG_ 920 EPASTS_a208_fdrLowSeverityBlocki "EPASTS_a208_fdrLowSeverityBlocking";
BA_ "SystemSignalLongSymbol" SG_ 920 EPASTS_a209_fdrLowSeverityFreezi "EPASTS_a209_fdrLowSeverityFreezing";
BA_ "SystemSignalLongSymbol" SG_ 920 EPASTS_a213_frmHighFrictionDetec "EPASTS_a213_frmHighFrictionDetected";
BA_ "SystemSignalLongSymbol" SG_ 920 EPASTS_a218_aadApplicationStateE "EPASTS_a218_aadApplicationStateErr";
BA_ "SystemSignalLongSymbol" SG_ 920 EPASTS_a220_transceiverInputqueu "EPASTS_a220_transceiverInputqueueOverflow";
BA_ "SystemSignalLongSymbol" SG_ 920 EPASTS_a258_pspInvalidProjectPar "EPASTS_a258_pspInvalidProjectParamset";
BA_ "SystemSignalLongSymbol" SG_ 920 EPASTS_a270_oscillationCompTrqLi "EPASTS_a270_oscillationCompTrqLimReached";
BA_ "Confidence" SG_ 805 ESP_infoIndex 1;
BA_ "Confidence" SG_ 805 ESP_infoBuildType 0;
BA_ "Confidence" SG_ 805 ESP_vehFlashMode 0;
BA_ "Confidence" SG_ 805 ESP_infoComponentID 0;
BA_ "Confidence" SG_ 805 ESP_infoPcbaID 0;
BA_ "Confidence" SG_ 805 ESP_infoAssemblyID 0;
BA_ "Confidence" SG_ 805 ESP_infoUsageID 0;
BA_ "Confidence" SG_ 805 ESP_infoSubUsageID 0;
BA_ "Confidence" SG_ 805 ESP_infoApplicationCRC 1;
BA_ "Confidence" SG_ 805 ESP_infoVehicleVariant 0;
BA_ "Confidence" SG_ 805 ESP_infoSubcomponent1 0;
BA_ "Confidence" SG_ 805 ESP_infoBootUdsProtoVersion 0;
BA_ "Confidence" SG_ 805 ESP_infoBootloaderCRC 0;
BA_ "Confidence" SG_ 805 ESP_infoVariantCRC 1;
BA_ "Confidence" SG_ 813 IBST_infoIndex 1;
BA_ "Confidence" SG_ 813 IBST_infoBuildType 0;
BA_ "Confidence" SG_ 813 IBST_infoPcbaID 0;
BA_ "Confidence" SG_ 813 IBST_infoAssemblyID 0;
BA_ "Confidence" SG_ 813 IBST_infoUsageID 0;
BA_ "Confidence" SG_ 813 IBST_infoSubUsageID 0;
BA_ "Confidence" SG_ 813 IBST_infoApplicationCRC 0;
BA_ "Confidence" SG_ 813 IBST_infoBootUdsProtoVersion 0;
BA_ "Confidence" SG_ 813 IBST_infoBootloaderCRC 0;
BA_ "Confidence" SG_ 813 IBST_infoVariantCRC 0;
BA_ "Confidence" SG_ 828 IDB_infoIndex 1;
BA_ "Confidence" SG_ 828 IDB_infoPcbaID 0;
BA_ "Confidence" SG_ 828 IDB_infoAssemblyID 0;
BA_ "Confidence" SG_ 828 IDB_infoUsageID 0;
BA_ "Confidence" SG_ 828 IDB_infoSubUsageID 0;
BA_ "Confidence" SG_ 1486 PARK_alertID 1;
BA_ "Confidence" SG_ 1486 PARK_alertState 1;
BA_ "Confidence" SG_ 1486 PARK_sw001_sensorTemperature 1;
BA_ "SystemSignalLongSymbol" SG_ 1486 PARK_sw002_diagnosticTransferErr "PARK_sw002_diagnosticTransferError";
BA_ "Confidence" SG_ 1486 PARK_sw004_reverbPeriod 1;
BA_ "Confidence" SG_ 1486 PARK_sw004_reverbTime 1;
BA_ "Confidence" SG_ 1486 PARK_sw006_sensorTemperature 1;
BA_ "SystemSignalLongSymbol" SG_ 1486 PARK_sw007_diagnosticTransferErr "PARK_sw007_diagnosticTransferError";
BA_ "Confidence" SG_ 1486 PARK_sw009_reverbPeriod 1;
BA_ "Confidence" SG_ 1486 PARK_sw009_reverbTime 1;
BA_ "Confidence" SG_ 1486 PARK_sw011_sensorTemperature 1;
BA_ "SystemSignalLongSymbol" SG_ 1486 PARK_sw012_diagnosticTransferErr "PARK_sw012_diagnosticTransferError";
BA_ "Confidence" SG_ 1486 PARK_sw014_reverbPeriod 1;
BA_ "Confidence" SG_ 1486 PARK_sw014_reverbTime 1;
BA_ "Confidence" SG_ 1486 PARK_sw016_sensorTemperature 1;
BA_ "SystemSignalLongSymbol" SG_ 1486 PARK_sw017_diagnosticTransferErr "PARK_sw017_diagnosticTransferError";
BA_ "Confidence" SG_ 1486 PARK_sw019_reverbPeriod 1;
BA_ "Confidence" SG_ 1486 PARK_sw019_reverbTime 1;
BA_ "Confidence" SG_ 1486 PARK_sw021_sensorTemperature 1;
BA_ "SystemSignalLongSymbol" SG_ 1486 PARK_sw022_diagnosticTransferErr "PARK_sw022_diagnosticTransferError";
BA_ "Confidence" SG_ 1486 PARK_sw024_reverbPeriod 1;
BA_ "Confidence" SG_ 1486 PARK_sw024_reverbTime 1;
BA_ "Confidence" SG_ 1486 PARK_sw026_sensorTemperature 1;
BA_ "SystemSignalLongSymbol" SG_ 1486 PARK_sw027_diagnosticTransferErr "PARK_sw027_diagnosticTransferError";
BA_ "Confidence" SG_ 1486 PARK_sw029_reverbPeriod 1;
BA_ "Confidence" SG_ 1486 PARK_sw029_reverbTime 1;
BA_ "Confidence" SG_ 1486 PARK_sw031_sensorTemperature 1;
BA_ "SystemSignalLongSymbol" SG_ 1486 PARK_sw032_diagnosticTransferErr "PARK_sw032_diagnosticTransferError";
BA_ "Confidence" SG_ 1486 PARK_sw034_reverbPeriod 1;
BA_ "Confidence" SG_ 1486 PARK_sw034_reverbTime 1;
BA_ "Confidence" SG_ 1486 PARK_sw036_sensorTemperature 1;
BA_ "SystemSignalLongSymbol" SG_ 1486 PARK_sw037_diagnosticTransferErr "PARK_sw037_diagnosticTransferError";
BA_ "Confidence" SG_ 1486 PARK_sw039_reverbPeriod 1;
BA_ "Confidence" SG_ 1486 PARK_sw039_reverbTime 1;
BA_ "Confidence" SG_ 1486 PARK_sw041_sensorTemperature 1;
BA_ "SystemSignalLongSymbol" SG_ 1486 PARK_sw042_diagnosticTransferErr "PARK_sw042_diagnosticTransferError";
BA_ "Confidence" SG_ 1486 PARK_sw044_reverbPeriod 1;
BA_ "Confidence" SG_ 1486 PARK_sw044_reverbTime 1;
BA_ "Confidence" SG_ 1486 PARK_sw046_sensorTemperature 1;
BA_ "SystemSignalLongSymbol" SG_ 1486 PARK_sw047_diagnosticTransferErr "PARK_sw047_diagnosticTransferError";
BA_ "Confidence" SG_ 1486 PARK_sw049_reverbPeriod 1;
BA_ "Confidence" SG_ 1486 PARK_sw049_reverbTime 1;
BA_ "Confidence" SG_ 1486 PARK_sw051_sensorTemperature 1;
BA_ "SystemSignalLongSymbol" SG_ 1486 PARK_sw052_diagnosticTransferErr "PARK_sw052_diagnosticTransferError";
BA_ "Confidence" SG_ 1486 PARK_sw054_reverbPeriod 1;
BA_ "Confidence" SG_ 1486 PARK_sw054_reverbTime 1;
BA_ "Confidence" SG_ 1486 PARK_sw056_sensorTemperature 1;
BA_ "SystemSignalLongSymbol" SG_ 1486 PARK_sw057_diagnosticTransferErr "PARK_sw057_diagnosticTransferError";
BA_ "Confidence" SG_ 1486 PARK_sw059_reverbPeriod 1;
BA_ "Confidence" SG_ 1486 PARK_sw059_reverbTime 1;
BA_ "Confidence" SG_ 1486 PARK_sw061_voltage 1;
BA_ "Confidence" SG_ 1486 PARK_sw063_voltage 1;
BA_ "Confidence" SG_ 1486 PARK_sw077_errorType 1;
BA_ "Confidence" SG_ 1486 PARK_sw078_errorType 1;
BA_ "Confidence" SG_ 1486 PARK_sw079_errorType 1;
BA_ "Confidence" SG_ 1486 PARK_sw080_errorType 1;
BA_ "Confidence" SG_ 1486 PARK_sw081_errorType 1;
BA_ "Confidence" SG_ 1486 PARK_sw082_errorType 1;
BA_ "Confidence" SG_ 1486 PARK_sw083_errorType 1;
BA_ "Confidence" SG_ 1486 PARK_sw084_errorType 1;
BA_ "Confidence" SG_ 1486 PARK_sw087_s1_sensorType 1;
BA_ "GenSigSNA" SG_ 1486 PARK_sw087_s1_sensorType "3";
BA_ "Confidence" SG_ 1486 PARK_sw087_s2_sensorType 1;
BA_ "GenSigSNA" SG_ 1486 PARK_sw087_s2_sensorType "3";
BA_ "Confidence" SG_ 1486 PARK_sw087_s3_sensorType 1;
BA_ "GenSigSNA" SG_ 1486 PARK_sw087_s3_sensorType "3";
BA_ "Confidence" SG_ 1486 PARK_sw087_s4_sensorType 1;
BA_ "GenSigSNA" SG_ 1486 PARK_sw087_s4_sensorType "3";
BA_ "Confidence" SG_ 1486 PARK_sw087_s5_sensorType 1;
BA_ "GenSigSNA" SG_ 1486 PARK_sw087_s5_sensorType "3";
BA_ "Confidence" SG_ 1486 PARK_sw087_s6_sensorType 1;
BA_ "GenSigSNA" SG_ 1486 PARK_sw087_s6_sensorType "3";
BA_ "Confidence" SG_ 1486 PARK_sw087_s7_sensorType 1;
BA_ "GenSigSNA" SG_ 1486 PARK_sw087_s7_sensorType "3";
BA_ "Confidence" SG_ 1486 PARK_sw087_s8_sensorType 1;
BA_ "GenSigSNA" SG_ 1486 PARK_sw087_s8_sensorType "3";
BA_ "Confidence" SG_ 1486 PARK_sw087_s9_sensorType 1;
BA_ "GenSigSNA" SG_ 1486 PARK_sw087_s9_sensorType "3";
BA_ "Confidence" SG_ 1486 PARK_sw087_s10_sensorType 1;
BA_ "GenSigSNA" SG_ 1486 PARK_sw087_s10_sensorType "3";
BA_ "Confidence" SG_ 1486 PARK_sw087_s11_sensorType 1;
BA_ "GenSigSNA" SG_ 1486 PARK_sw087_s11_sensorType "3";
BA_ "Confidence" SG_ 1486 PARK_sw087_s12_sensorType 1;
BA_ "GenSigSNA" SG_ 1486 PARK_sw087_s12_sensorType "3";
BA_ "Confidence" SG_ 806 PARK_infoIndex 1;
BA_ "Confidence" SG_ 806 PARK_infoBuildType 0;
BA_ "Confidence" SG_ 806 PARK_infoComponentID 0;
BA_ "Confidence" SG_ 806 PARK_infoPcbaID 0;
BA_ "Confidence" SG_ 806 PARK_infoAssemblyID 0;
BA_ "Confidence" SG_ 806 PARK_infoUsageID 0;
BA_ "Confidence" SG_ 806 PARK_infoApplicationCRC 0;
BA_ "Confidence" SG_ 806 PARK_infoBootUdsProtoVersion 0;
BA_ "Confidence" SG_ 806 PARK_infoBootloaderCRC 0;
BA_ "Confidence" SG_ 846 PARK_frontLeftMiddleRawDistData 0;
BA_ "GenSigSNA" SG_ 846 PARK_frontLeftMiddleRawDistData "255";
BA_ "Confidence" SG_ 846 PARK_frontMiddleRawDistData 0;
BA_ "GenSigSNA" SG_ 846 PARK_frontMiddleRawDistData "255";
BA_ "Confidence" SG_ 846 PARK_frontRightMiddleRawDistData 0;
BA_ "GenSigSNA" SG_ 846 PARK_frontRightMiddleRawDistData "255";
BA_ "Confidence" SG_ 846 PARK_pasFrontMiddleCounter 0;
BA_ "Confidence" SG_ 846 PARK_pasFrontMiddleChecksum 0;
BA_ "Confidence" SG_ 862 PARK_rearLeftMiddleRawDistData 0;
BA_ "GenSigSNA" SG_ 862 PARK_rearLeftMiddleRawDistData "255";
BA_ "Confidence" SG_ 862 PARK_rearMiddleRawDistData 0;
BA_ "GenSigSNA" SG_ 862 PARK_rearMiddleRawDistData "255";
BA_ "Confidence" SG_ 862 PARK_rearRightMiddleRawDistData 0;
BA_ "GenSigSNA" SG_ 862 PARK_rearRightMiddleRawDistData "255";
BA_ "Confidence" SG_ 862 PARK_pasRearMiddleCounter 0;
BA_ "Confidence" SG_ 862 PARK_pasRearMiddleChecksum 0;
BA_ "Confidence" SG_ 926 PARK_rightSideFrontRawDistData 0;
BA_ "GenSigSNA" SG_ 926 PARK_rightSideFrontRawDistData "255";
BA_ "Confidence" SG_ 926 PARK_rightSideRearRawDistData 0;
BA_ "GenSigSNA" SG_ 926 PARK_rightSideRearRawDistData "255";
BA_ "Confidence" SG_ 926 PARK_leftSideFrontRawDistData 0;
BA_ "GenSigSNA" SG_ 926 PARK_leftSideFrontRawDistData "255";
BA_ "Confidence" SG_ 926 PARK_leftSideRearRawDistData 0;
BA_ "GenSigSNA" SG_ 926 PARK_leftSideRearRawDistData "255";
BA_ "Confidence" SG_ 926 PARK_pasSidesCounter 0;
BA_ "Confidence" SG_ 926 PARK_pasSidesChecksum 0;
BA_ "Confidence" SG_ 606 PARK_pscEnvSlotType 1;
BA_ "Confidence" SG_ 606 PARK_pscLeftParallelObj1X 0;
BA_ "GenSigSNA" SG_ 606 PARK_pscLeftParallelObj1X "2047";
BA_ "Confidence" SG_ 606 PARK_pscLeftParallelObj1Y 0;
BA_ "GenSigSNA" SG_ 606 PARK_pscLeftParallelObj1Y "2047";
BA_ "Confidence" SG_ 606 PARK_pscLeftParallelObj1Alpha 0;
BA_ "GenSigSNA" SG_ 606 PARK_pscLeftParallelObj1Alpha "127";
BA_ "Confidence" SG_ 606 PARK_pscLeftParallelObj2Y 0;
BA_ "GenSigSNA" SG_ 606 PARK_pscLeftParallelObj2Y "2047";
BA_ "Confidence" SG_ 606 PARK_pscLeftParallelObj2X 0;
BA_ "GenSigSNA" SG_ 606 PARK_pscLeftParallelObj2X "2047";
BA_ "Confidence" SG_ 606 PARK_pscLeftParallelObj2Alpha 0;
BA_ "GenSigSNA" SG_ 606 PARK_pscLeftParallelObj2Alpha "127";
BA_ "Confidence" SG_ 606 PARK_pscLeftCrossObj1X 0;
BA_ "GenSigSNA" SG_ 606 PARK_pscLeftCrossObj1X "2047";
BA_ "Confidence" SG_ 606 PARK_pscLeftCrossObj1Y 0;
BA_ "GenSigSNA" SG_ 606 PARK_pscLeftCrossObj1Y "2047";
BA_ "Confidence" SG_ 606 PARK_pscLeftCrossObj1Alpha 0;
BA_ "GenSigSNA" SG_ 606 PARK_pscLeftCrossObj1Alpha "127";
BA_ "Confidence" SG_ 606 PARK_pscLeftCrossObj2Y 0;
BA_ "GenSigSNA" SG_ 606 PARK_pscLeftCrossObj2Y "2047";
BA_ "Confidence" SG_ 606 PARK_pscLeftCrossObj2X 0;
BA_ "GenSigSNA" SG_ 606 PARK_pscLeftCrossObj2X "2047";
BA_ "Confidence" SG_ 606 PARK_pscLeftCrossObj2Alpha 0;
BA_ "GenSigSNA" SG_ 606 PARK_pscLeftCrossObj2Alpha "127";
BA_ "Confidence" SG_ 606 PARK_pscRightParallelObj1X 0;
BA_ "GenSigSNA" SG_ 606 PARK_pscRightParallelObj1X "2047";
BA_ "Confidence" SG_ 606 PARK_pscRightParallelObj1Y 0;
BA_ "GenSigSNA" SG_ 606 PARK_pscRightParallelObj1Y "2047";
BA_ "Confidence" SG_ 606 PARK_pscRightParallelObj1Alpha 0;
BA_ "GenSigSNA" SG_ 606 PARK_pscRightParallelObj1Alpha "127";
BA_ "Confidence" SG_ 606 PARK_pscRightParallelObj2Y 0;
BA_ "GenSigSNA" SG_ 606 PARK_pscRightParallelObj2Y "2047";
BA_ "Confidence" SG_ 606 PARK_pscRightParallelObj2X 0;
BA_ "GenSigSNA" SG_ 606 PARK_pscRightParallelObj2X "2047";
BA_ "Confidence" SG_ 606 PARK_pscRightParallelObj2Alpha 0;
BA_ "GenSigSNA" SG_ 606 PARK_pscRightParallelObj2Alpha "127";
BA_ "Confidence" SG_ 606 PARK_pscRightCrossObj1X 0;
BA_ "GenSigSNA" SG_ 606 PARK_pscRightCrossObj1X "2047";
BA_ "Confidence" SG_ 606 PARK_pscRightCrossObj1Y 0;
BA_ "GenSigSNA" SG_ 606 PARK_pscRightCrossObj1Y "2047";
BA_ "Confidence" SG_ 606 PARK_pscRightCrossObj1Alpha 0;
BA_ "GenSigSNA" SG_ 606 PARK_pscRightCrossObj1Alpha "127";
BA_ "Confidence" SG_ 606 PARK_pscRightCrossObj2Y 0;
BA_ "GenSigSNA" SG_ 606 PARK_pscRightCrossObj2Y "2047";
BA_ "Confidence" SG_ 606 PARK_pscRightCrossObj2X 0;
BA_ "GenSigSNA" SG_ 606 PARK_pscRightCrossObj2X "2047";
BA_ "Confidence" SG_ 606 PARK_pscRightCrossObj2Alpha 0;
BA_ "GenSigSNA" SG_ 606 PARK_pscRightCrossObj2Alpha "127";
BA_ "Confidence" SG_ 542 PARK_pscParkStatus 0;
BA_ "GenSigSNA" SG_ 542 PARK_pscParkStatus "7";
BA_ "Confidence" SG_ 542 PARK_pscParkAbortReason 0;
BA_ "GenSigSNA" SG_ 542 PARK_pscParkAbortReason "31";
BA_ "Confidence" SG_ 542 PARK_pscParallelSpace 0;
BA_ "Confidence" SG_ 542 PARK_pscCrossSpace 0;
BA_ "Confidence" SG_ 542 PARK_pscParallelRightParkable 0;
BA_ "GenSigSNA" SG_ 542 PARK_pscParallelRightParkable "3";
BA_ "Confidence" SG_ 542 PARK_pscParallelLeftParkable 0;
BA_ "GenSigSNA" SG_ 542 PARK_pscParallelLeftParkable "3";
BA_ "Confidence" SG_ 542 PARK_pscCrossRightParkable 0;
BA_ "GenSigSNA" SG_ 542 PARK_pscCrossRightParkable "3";
BA_ "Confidence" SG_ 542 PARK_pscMaxVelocity 0;
BA_ "GenSigSNA" SG_ 542 PARK_pscMaxVelocity "63";
BA_ "Confidence" SG_ 542 PARK_pscCrossLeftParkable 0;
BA_ "GenSigSNA" SG_ 542 PARK_pscCrossLeftParkable "3";
BA_ "Confidence" SG_ 542 PARK_pscParkInstruction 0;
BA_ "GenSigSNA" SG_ 542 PARK_pscParkInstruction "7";
BA_ "Confidence" SG_ 542 PARK_pscManeuverDistance 0;
BA_ "GenSigSNA" SG_ 542 PARK_pscManeuverDistance "2047";
BA_ "Confidence" SG_ 542 PARK_pscAngleActive 0;
BA_ "Confidence" SG_ 542 PARK_pscAngleRequest 0;
BA_ "Confidence" SG_ 542 PARK_pscStatusCounter 0;
BA_ "Confidence" SG_ 542 PARK_pscStatusChecksum 0;
BA_ "Confidence" SG_ 590 PARK_pscVehSlotType 1;
BA_ "Confidence" SG_ 590 PARK_pscLeftParallelVehX 0;
BA_ "GenSigSNA" SG_ 590 PARK_pscLeftParallelVehX "2047";
BA_ "Confidence" SG_ 590 PARK_pscLeftParallelVehY 0;
BA_ "GenSigSNA" SG_ 590 PARK_pscLeftParallelVehY "2047";
BA_ "Confidence" SG_ 590 PARK_pscLeftParallelPsi 0;
BA_ "GenSigSNA" SG_ 590 PARK_pscLeftParallelPsi "8191";
BA_ "Confidence" SG_ 590 PARK_pscLeftParallelSizeX 0;
BA_ "GenSigSNA" SG_ 590 PARK_pscLeftParallelSizeX "255";
BA_ "Confidence" SG_ 590 PARK_pscLeftParallelSizeY 0;
BA_ "GenSigSNA" SG_ 590 PARK_pscLeftParallelSizeY "255";
BA_ "Confidence" SG_ 590 PARK_pscLeftCrossVehX 0;
BA_ "GenSigSNA" SG_ 590 PARK_pscLeftCrossVehX "2047";
BA_ "Confidence" SG_ 590 PARK_pscLeftCrossVehY 0;
BA_ "GenSigSNA" SG_ 590 PARK_pscLeftCrossVehY "2047";
BA_ "Confidence" SG_ 590 PARK_pscLeftCrossPsi 0;
BA_ "GenSigSNA" SG_ 590 PARK_pscLeftCrossPsi "8191";
BA_ "Confidence" SG_ 590 PARK_pscLeftCrossSizeX 0;
BA_ "GenSigSNA" SG_ 590 PARK_pscLeftCrossSizeX "255";
BA_ "Confidence" SG_ 590 PARK_pscLeftCrossSizeY 0;
BA_ "GenSigSNA" SG_ 590 PARK_pscLeftCrossSizeY "255";
BA_ "Confidence" SG_ 590 PARK_pscRightParallelVehX 0;
BA_ "GenSigSNA" SG_ 590 PARK_pscRightParallelVehX "2047";
BA_ "Confidence" SG_ 590 PARK_pscRightParallelVehY 0;
BA_ "GenSigSNA" SG_ 590 PARK_pscRightParallelVehY "2047";
BA_ "Confidence" SG_ 590 PARK_pscRightParallelPsi 0;
BA_ "GenSigSNA" SG_ 590 PARK_pscRightParallelPsi "8191";
BA_ "Confidence" SG_ 590 PARK_pscRightParallelSizeX 0;
BA_ "GenSigSNA" SG_ 590 PARK_pscRightParallelSizeX "255";
BA_ "Confidence" SG_ 590 PARK_pscRightParallelSizeY 0;
BA_ "GenSigSNA" SG_ 590 PARK_pscRightParallelSizeY "255";
BA_ "Confidence" SG_ 590 PARK_pscRightCrossVehX 0;
BA_ "GenSigSNA" SG_ 590 PARK_pscRightCrossVehX "2047";
BA_ "Confidence" SG_ 590 PARK_pscRightCrossVehY 0;
BA_ "GenSigSNA" SG_ 590 PARK_pscRightCrossVehY "2047";
BA_ "Confidence" SG_ 590 PARK_pscRightCrossPsi 0;
BA_ "GenSigSNA" SG_ 590 PARK_pscRightCrossPsi "8191";
BA_ "Confidence" SG_ 590 PARK_pscRightCrossSizeX 0;
BA_ "GenSigSNA" SG_ 590 PARK_pscRightCrossSizeX "255";
BA_ "Confidence" SG_ 590 PARK_pscRightCrossSizeY 0;
BA_ "GenSigSNA" SG_ 590 PARK_pscRightCrossSizeY "255";
BA_ "Confidence" SG_ 526 PARK_sdiSensor1RawDistData 0;
BA_ "GenSigSNA" SG_ 526 PARK_sdiSensor1RawDistData "511";
BA_ "Confidence" SG_ 526 PARK_sdiSensor2RawDistData 0;
BA_ "GenSigSNA" SG_ 526 PARK_sdiSensor2RawDistData "511";
BA_ "Confidence" SG_ 526 PARK_sdiSensor3RawDistData 0;
BA_ "GenSigSNA" SG_ 526 PARK_sdiSensor3RawDistData "511";
BA_ "Confidence" SG_ 526 PARK_sdiSensor4RawDistData 0;
BA_ "GenSigSNA" SG_ 526 PARK_sdiSensor4RawDistData "511";
BA_ "Confidence" SG_ 526 PARK_sdiSensor5RawDistData 0;
BA_ "GenSigSNA" SG_ 526 PARK_sdiSensor5RawDistData "511";
BA_ "Confidence" SG_ 526 PARK_sdiSensor6RawDistData 0;
BA_ "GenSigSNA" SG_ 526 PARK_sdiSensor6RawDistData "511";
BA_ "Confidence" SG_ 526 PARK_sdiFrontCounter 0;
BA_ "Confidence" SG_ 526 PARK_sdiFrontChecksum 0;
BA_ "Confidence" SG_ 558 PARK_sdiSensor7RawDistData 0;
BA_ "GenSigSNA" SG_ 558 PARK_sdiSensor7RawDistData "511";
BA_ "Confidence" SG_ 558 PARK_sdiSensor8RawDistData 0;
BA_ "GenSigSNA" SG_ 558 PARK_sdiSensor8RawDistData "511";
BA_ "Confidence" SG_ 558 PARK_sdiSensor9RawDistData 0;
BA_ "GenSigSNA" SG_ 558 PARK_sdiSensor9RawDistData "511";
BA_ "Confidence" SG_ 558 PARK_sdiSensor10RawDistData 0;
BA_ "GenSigSNA" SG_ 558 PARK_sdiSensor10RawDistData "511";
BA_ "Confidence" SG_ 558 PARK_sdiSensor11RawDistData 0;
BA_ "GenSigSNA" SG_ 558 PARK_sdiSensor11RawDistData "511";
BA_ "Confidence" SG_ 558 PARK_sdiSensor12RawDistData 0;
BA_ "GenSigSNA" SG_ 558 PARK_sdiSensor12RawDistData "511";
BA_ "Confidence" SG_ 558 PARK_sdiRearCounter 0;
BA_ "Confidence" SG_ 558 PARK_sdiRearChecksum 0;
BA_ "Confidence" SG_ 814 PARK_frontRightSensorState 0;
BA_ "GenSigSNA" SG_ 814 PARK_frontRightSensorState "3";
BA_ "Confidence" SG_ 814 PARK_frontRightMiddleSensorState 0;
BA_ "GenSigSNA" SG_ 814 PARK_frontRightMiddleSensorState "3";
BA_ "Confidence" SG_ 814 PARK_frontLeftMiddleSensorState 0;
BA_ "GenSigSNA" SG_ 814 PARK_frontLeftMiddleSensorState "3";
BA_ "Confidence" SG_ 814 PARK_frontLeftSensorState 0;
BA_ "GenSigSNA" SG_ 814 PARK_frontLeftSensorState "3";
BA_ "Confidence" SG_ 814 PARK_frontLeftRawDistData 0;
BA_ "GenSigSNA" SG_ 814 PARK_frontLeftRawDistData "255";
BA_ "Confidence" SG_ 814 PARK_frontRightRawDistData 0;
BA_ "GenSigSNA" SG_ 814 PARK_frontRightRawDistData "255";
BA_ "Confidence" SG_ 814 PARK_systemStatusFront 0;
BA_ "GenSigSNA" SG_ 814 PARK_systemStatusFront "3";
BA_ "Confidence" SG_ 814 PARK_frontDtcPresent 0;
BA_ "GenSigSNA" SG_ 814 PARK_frontDtcPresent "3";
BA_ "Confidence" SG_ 814 PARK_sensorStatusFrontCounter 0;
BA_ "Confidence" SG_ 814 PARK_sensorStatusFrontChecksum 0;
BA_ "Confidence" SG_ 830 PARK_rearRightSensorState 0;
BA_ "GenSigSNA" SG_ 830 PARK_rearRightSensorState "3";
BA_ "Confidence" SG_ 830 PARK_rearRightMiddleSensorState 0;
BA_ "GenSigSNA" SG_ 830 PARK_rearRightMiddleSensorState "3";
BA_ "Confidence" SG_ 830 PARK_rearLeftMiddleSensorState 0;
BA_ "GenSigSNA" SG_ 830 PARK_rearLeftMiddleSensorState "3";
BA_ "Confidence" SG_ 830 PARK_rearLeftSensorState 0;
BA_ "GenSigSNA" SG_ 830 PARK_rearLeftSensorState "3";
BA_ "Confidence" SG_ 830 PARK_rearLeftRawDistData 0;
BA_ "GenSigSNA" SG_ 830 PARK_rearLeftRawDistData "255";
BA_ "Confidence" SG_ 830 PARK_rearRightRawDistData 0;
BA_ "GenSigSNA" SG_ 830 PARK_rearRightRawDistData "255";
BA_ "Confidence" SG_ 830 PARK_systemStatusRear 0;
BA_ "GenSigSNA" SG_ 830 PARK_systemStatusRear "3";
BA_ "Confidence" SG_ 830 PARK_rearDtcPresent 0;
BA_ "GenSigSNA" SG_ 830 PARK_rearDtcPresent "3";
BA_ "Confidence" SG_ 830 PARK_sensorStatusRearCounter 0;
BA_ "Confidence" SG_ 830 PARK_sensorStatusRearChecksum 0;
BA_ "Confidence" SG_ 798 PARK_status 0;
BA_ "GenSigSNA" SG_ 798 PARK_status "3";
BA_ "Confidence" SG_ 798 PARK_serviceRequest 0;
BA_ "GenSigSNA" SG_ 798 PARK_serviceRequest "3";
BA_ "Confidence" SG_ 798 PARK_systemDtcPresent 0;
BA_ "GenSigSNA" SG_ 798 PARK_systemDtcPresent "3";
BA_ "Confidence" SG_ 798 PARK_statusCounter 0;
BA_ "Confidence" SG_ 798 PARK_statusChecksum 0;
BA_ "Confidence" SG_ 798 PARK_majorVersion 0;
BA_ "GenSigSNA" SG_ 798 PARK_majorVersion "255";
BA_ "Confidence" SG_ 798 PARK_minorVersion 0;
BA_ "GenSigSNA" SG_ 798 PARK_minorVersion "255";
BA_ "Confidence" SG_ 798 PARK_subMinorVersion 0;
BA_ "GenSigSNA" SG_ 798 PARK_subMinorVersion "255";
VAL_ 977 EPAS3S_resyncStatus 1 "RESYNC_COMPLETE" 0 "RESYNC_PENDING" ;
VAL_ 785 EPAS3S_infoIndex 255 "END" 31 "SUBCOMPONENT_GITHASH" 30 "PACKAGE_SN_8_14" 29 "PACKAGE_SN_1_7" 27 "PACKAGE_PN_15_20" 26 "PACKAGE_PN_8_14" 25 "PACKAGE_PN_1_7" 23 "SUBCOMPONENT2" 22 "VARIANTCRC" 20 "UDS_PROTOCOL_BOOTCRC" 19 "VERSION_DEPRECATED" 18 "BOOTLOADER_GITHASH" 17 "APP_GITHASH" 16 "SUBCOMPONENT" 15 "BOOTLOADER_CRC" 14 "BOOTLOADER_SVN" 13 "APP_CRC" 11 "PCBAID_ASSYID_USAGEID" 10 "BUILD_HWID_COMPONENTID" 9 "DEPRECATED_9" 8 "DEPRECATED_8" 7 "DEPRECATED_7" 6 "DEPRECATED_6" 5 "DEPRECATED_5" 4 "DEPRECATED_4" 3 "DEPRECATED_3" 2 "DEPRECATED_2" 1 "DEPRECATED_1" 0 "DEPRECATED_0" ;
VAL_ 785 EPAS3S_infoBuildType 4 "INFO_MFG_BUILD" 3 "INFO_TRACEABLE_CI_BUILD" 2 "INFO_LOCAL_BUILD" 1 "INFO_PLATFORM_BUILD" 0 "INFO_UNKNOWN_BUILD" ;
VAL_ 920 EPASTS_matrixIndex 4 "AlertMatrix4" 3 "AlertMatrix3" 2 "AlertMatrix2" 1 "AlertMatrix1" 0 "AlertMatrix0" ;
VAL_ 805 ESP_infoIndex 255 "END" 31 "SUBCOMPONENT_GITHASH" 30 "PACKAGE_SN_8_14" 29 "PACKAGE_SN_1_7" 27 "PACKAGE_PN_15_20" 26 "PACKAGE_PN_8_14" 25 "PACKAGE_PN_1_7" 23 "SUBCOMPONENT2" 22 "VARIANTCRC" 20 "UDS_PROTOCOL_BOOTCRC" 19 "VERSION_DEPRECATED" 18 "BOOTLOADER_GITHASH" 17 "APP_GITHASH" 16 "SUBCOMPONENT" 15 "BOOTLOADER_CRC" 14 "BOOTLOADER_SVN" 13 "APP_CRC" 11 "PCBAID_ASSYID_USAGEID" 10 "BUILD_HWID_COMPONENTID" 9 "DEPRECATED_9" 8 "DEPRECATED_8" 7 "DEPRECATED_7" 6 "DEPRECATED_6" 5 "DEPRECATED_5" 4 "DEPRECATED_4" 3 "DEPRECATED_3" 2 "DEPRECATED_2" 1 "DEPRECATED_1" 0 "DEPRECATED_0" ;
VAL_ 805 ESP_infoBuildType 4 "INFO_MFG_BUILD" 3 "INFO_TRACEABLE_CI_BUILD" 2 "INFO_LOCAL_BUILD" 1 "INFO_PLATFORM_BUILD" 0 "INFO_UNKNOWN_BUILD" ;
VAL_ 805 ESP_vehFlashMode 1 "Development_Mode" 0 "Production_Mode" ;
VAL_ 805 ESP_infoSubUsageID 16 "XCP_Dfive_ESP_CP_CB" 8 "nonXCP_Dfour_ESP_CP_CB" 4 "XCP_Gladiator_ESP" 2 "nonXCP_Rev_C_ESP_Cappella" 0 "nonXCP_Rev_B_ESP_Cappella" ;
VAL_ 805 ESP_infoVehicleVariant 9 "MODEL_3_VARIANT_09" 8 "MODEL_3_VARIANT_08" 7 "MODEL_3_VARIANT_07" 6 "MODEL_3_VARIANT_06" 5 "MODEL_3_VARIANT_05" 4 "MODEL_3_VARIANT_04" 3 "MODEL_3_VARIANT_03" 2 "MODEL_3_VARIANT_02" 1 "MODEL_3_VARIANT_01" ;
VAL_ 813 IBST_infoIndex 255 "END" 31 "SUBCOMPONENT_GITHASH" 30 "PACKAGE_SN_8_14" 29 "PACKAGE_SN_1_7" 27 "PACKAGE_PN_15_20" 26 "PACKAGE_PN_8_14" 25 "PACKAGE_PN_1_7" 23 "SUBCOMPONENT2" 22 "VARIANTCRC" 20 "UDS_PROTOCOL_BOOTCRC" 19 "VERSION_DEPRECATED" 18 "BOOTLOADER_GITHASH" 17 "APP_GITHASH" 16 "SUBCOMPONENT" 15 "BOOTLOADER_CRC" 14 "BOOTLOADER_SVN" 13 "APP_CRC" 11 "PCBAID_ASSYID_USAGEID" 10 "BUILD_HWID_COMPONENTID" 9 "DEPRECATED_9" 8 "DEPRECATED_8" 7 "DEPRECATED_7" 6 "DEPRECATED_6" 5 "DEPRECATED_5" 4 "DEPRECATED_4" 3 "DEPRECATED_3" 2 "DEPRECATED_2" 1 "DEPRECATED_1" 0 "DEPRECATED_0" ;
VAL_ 813 IBST_infoBuildType 4 "INFO_MFG_BUILD" 3 "INFO_TRACEABLE_CI_BUILD" 2 "INFO_LOCAL_BUILD" 1 "INFO_PLATFORM_BUILD" 0 "INFO_UNKNOWN_BUILD" ;
VAL_ 828 IDB_infoIndex 255 "END" 31 "SUBCOMPONENT_GITHASH" 30 "PACKAGE_SN_8_14" 29 "PACKAGE_SN_1_7" 27 "PACKAGE_PN_15_20" 26 "PACKAGE_PN_8_14" 25 "PACKAGE_PN_1_7" 23 "SUBCOMPONENT2" 22 "VARIANTCRC" 20 "UDS_PROTOCOL_BOOTCRC" 19 "VERSION_DEPRECATED" 18 "BOOTLOADER_GITHASH" 17 "APP_GITHASH" 16 "SUBCOMPONENT" 15 "BOOTLOADER_CRC" 14 "BOOTLOADER_SVN" 13 "APP_CRC" 11 "PCBAID_ASSYID_USAGEID" 10 "BUILD_HWID_COMPONENTID" 9 "DEPRECATED_9" 8 "DEPRECATED_8" 7 "DEPRECATED_7" 6 "DEPRECATED_6" 5 "DEPRECATED_5" 4 "DEPRECATED_4" 3 "DEPRECATED_3" 2 "DEPRECATED_2" 1 "DEPRECATED_1" 0 "DEPRECATED_0" ;
VAL_ 1486 PARK_alertID 87 "a087_sensorMismatchError" 86 "a086_nvmFault" 85 "a085_watchdogReset" 84 "a084_sccmError" 83 "a083_vcFrontError" 82 "a082_rcmError" 81 "a081_espError" 80 "a080_epbError" 79 "a079_epasError" 78 "a078_diError" 77 "a077_dasError" 76 "a076_vcFrontMia" 75 "a075_rcmMia" 74 "a074_espMia" 73 "a073_epbMia" 72 "a072_epasMia" 71 "a071_diMia" 70 "a070_sccmMia" 69 "a069_dasMia" 68 "a068_hardwareWatchDog" 67 "a067_privateCANBusOff" 66 "a066_calibrationMissing" 65 "a065_crcFault" 64 "a064_ecuFault" 63 "a063_sensorVoltage" 62 "a062_ecuOverVoltage" 61 "a061_ecuUnderVoltage" 60 "a060_s12_crossTalk" 59 "a059_s12_blocked" 58 "a058_s12_linCommError" 57 "a057_s12_internalFail" 56 "a056_s12_overTemp" 55 "a055_s11_crossTalk" 54 "a054_s11_blocked" 53 "a053_s11_linCommError" 52 "a052_s11_internalFail" 51 "a051_s11_overTemp" 50 "a050_s10_crossTalk" 49 "a049_s10_blocked" 48 "a048_s10_linCommError" 47 "a047_s10_internalFail" 46 "a046_s10_overTemp" 45 "a045_s9_crossTalk" 44 "a044_s9_blocked" 43 "a043_s9_linCommError" 42 "a042_s9_internalFail" 41 "a041_s9_overTemp" 40 "a040_s8_crossTalk" 39 "a039_s8_blocked" 38 "a038_s8_linCommError" 37 "a037_s8_internalFail" 36 "a036_s8_overTemp" 35 "a035_s7_crossTalk" 34 "a034_s7_blocked" 33 "a033_s7_linCommError" 32 "a032_s7_internalFail" 31 "a031_s7_overTemp" 30 "a030_s6_crossTalk" 29 "a029_s6_blocked" 28 "a028_s6_linCommError" 27 "a027_s6_internalFail" 26 "a026_s6_overTemp" 25 "a025_s5_crossTalk" 24 "a024_s5_blocked" 23 "a023_s5_linCommError" 22 "a022_s5_internalFail" 21 "a021_s5_overTemp" 20 "a020_s4_crossTalk" 19 "a019_s4_blocked" 18 "a018_s4_linCommError" 17 "a017_s4_internalFail" 16 "a016_s4_overTemp" 15 "a015_s3_crossTalk" 14 "a014_s3_blocked" 13 "a013_s3_linCommError" 12 "a012_s3_internalFail" 11 "a011_s3_overTemp" 10 "a010_s2_crossTalk" 9 "a009_s2_blocked" 8 "a008_s2_linCommError" 7 "a007_s2_internalFail" 6 "a006_s2_overTemp" 5 "a005_s1_crossTalk" 4 "a004_s1_blocked" 3 "a003_s1_linCommError" 2 "a002_s1_internalFail" 1 "a001_s1_overTemp" 0 "ALERT_DO_NOT_USE_ZERO" ;
VAL_ 1486 PARK_alertState 1 "SET" 0 "CLEARED" ;
VAL_ 1486 PARK_sw077_errorType 5 "OVERRUN" 4 "INVALID_DATA" 3 "SEQUENCE" 2 "CHECKSUM" 1 "LENGTH" 0 "NONE" ;
VAL_ 1486 PARK_sw078_errorType 5 "OVERRUN" 4 "INVALID_DATA" 3 "SEQUENCE" 2 "CHECKSUM" 1 "LENGTH" 0 "NONE" ;
VAL_ 1486 PARK_sw079_errorType 5 "OVERRUN" 4 "INVALID_DATA" 3 "SEQUENCE" 2 "CHECKSUM" 1 "LENGTH" 0 "NONE" ;
VAL_ 1486 PARK_sw080_errorType 5 "OVERRUN" 4 "INVALID_DATA" 3 "SEQUENCE" 2 "CHECKSUM" 1 "LENGTH" 0 "NONE" ;
VAL_ 1486 PARK_sw081_errorType 5 "OVERRUN" 4 "INVALID_DATA" 3 "SEQUENCE" 2 "CHECKSUM" 1 "LENGTH" 0 "NONE" ;
VAL_ 1486 PARK_sw082_errorType 5 "OVERRUN" 4 "INVALID_DATA" 3 "SEQUENCE" 2 "CHECKSUM" 1 "LENGTH" 0 "NONE" ;
VAL_ 1486 PARK_sw083_errorType 5 "OVERRUN" 4 "INVALID_DATA" 3 "SEQUENCE" 2 "CHECKSUM" 1 "LENGTH" 0 "NONE" ;
VAL_ 1486 PARK_sw084_errorType 5 "OVERRUN" 4 "INVALID_DATA" 3 "SEQUENCE" 2 "CHECKSUM" 1 "LENGTH" 0 "NONE" ;
VAL_ 1486 PARK_sw087_s1_sensorType 3 "SNA" 2 "VALEO_HP" 1 "VALEO_HPFL" 0 "NONE" ;
VAL_ 1486 PARK_sw087_s2_sensorType 3 "SNA" 2 "VALEO_HP" 1 "VALEO_HPFL" 0 "NONE" ;
VAL_ 1486 PARK_sw087_s3_sensorType 3 "SNA" 2 "VALEO_HP" 1 "VALEO_HPFL" 0 "NONE" ;
VAL_ 1486 PARK_sw087_s4_sensorType 3 "SNA" 2 "VALEO_HP" 1 "VALEO_HPFL" 0 "NONE" ;
VAL_ 1486 PARK_sw087_s5_sensorType 3 "SNA" 2 "VALEO_HP" 1 "VALEO_HPFL" 0 "NONE" ;
VAL_ 1486 PARK_sw087_s6_sensorType 3 "SNA" 2 "VALEO_HP" 1 "VALEO_HPFL" 0 "NONE" ;
VAL_ 1486 PARK_sw087_s7_sensorType 3 "SNA" 2 "VALEO_HP" 1 "VALEO_HPFL" 0 "NONE" ;
VAL_ 1486 PARK_sw087_s8_sensorType 3 "SNA" 2 "VALEO_HP" 1 "VALEO_HPFL" 0 "NONE" ;
VAL_ 1486 PARK_sw087_s9_sensorType 3 "SNA" 2 "VALEO_HP" 1 "VALEO_HPFL" 0 "NONE" ;
VAL_ 1486 PARK_sw087_s10_sensorType 3 "SNA" 2 "VALEO_HP" 1 "VALEO_HPFL" 0 "NONE" ;
VAL_ 1486 PARK_sw087_s11_sensorType 3 "SNA" 2 "VALEO_HP" 1 "VALEO_HPFL" 0 "NONE" ;
VAL_ 1486 PARK_sw087_s12_sensorType 3 "SNA" 2 "VALEO_HP" 1 "VALEO_HPFL" 0 "NONE" ;
VAL_ 806 PARK_infoIndex 255 "END" 31 "SUBCOMPONENT_GITHASH" 30 "PACKAGE_SN_8_14" 29 "PACKAGE_SN_1_7" 27 "PACKAGE_PN_15_20" 26 "PACKAGE_PN_8_14" 25 "PACKAGE_PN_1_7" 23 "SUBCOMPONENT2" 22 "VARIANTCRC" 20 "UDS_PROTOCOL_BOOTCRC" 19 "VERSION_DEPRECATED" 18 "BOOTLOADER_GITHASH" 17 "APP_GITHASH" 16 "SUBCOMPONENT" 15 "BOOTLOADER_CRC" 14 "BOOTLOADER_SVN" 13 "APP_CRC" 11 "PCBAID_ASSYID_USAGEID" 10 "BUILD_HWID_COMPONENTID" 9 "DEPRECATED_9" 8 "DEPRECATED_8" 7 "DEPRECATED_7" 6 "DEPRECATED_6" 5 "DEPRECATED_5" 4 "DEPRECATED_4" 3 "DEPRECATED_3" 2 "DEPRECATED_2" 1 "DEPRECATED_1" 0 "DEPRECATED_0" ;
VAL_ 806 PARK_infoBuildType 4 "INFO_MFG_BUILD" 3 "INFO_TRACEABLE_CI_BUILD" 2 "INFO_LOCAL_BUILD" 1 "INFO_PLATFORM_BUILD" 0 "INFO_UNKNOWN_BUILD" ;
VAL_ 846 PARK_frontLeftMiddleRawDistData 255 "SNA" ;
VAL_ 846 PARK_frontMiddleRawDistData 255 "SNA" ;
VAL_ 846 PARK_frontRightMiddleRawDistData 255 "SNA" ;
VAL_ 862 PARK_rearLeftMiddleRawDistData 255 "SNA" ;
VAL_ 862 PARK_rearMiddleRawDistData 255 "SNA" ;
VAL_ 862 PARK_rearRightMiddleRawDistData 255 "SNA" ;
VAL_ 926 PARK_rightSideFrontRawDistData 255 "SNA" ;
VAL_ 926 PARK_rightSideRearRawDistData 255 "SNA" ;
VAL_ 926 PARK_leftSideFrontRawDistData 255 "SNA" ;
VAL_ 926 PARK_leftSideRearRawDistData 255 "SNA" ;
VAL_ 606 PARK_pscEnvSlotType 3 "RIGHT_CROSS" 2 "RIGHT_PARALLEL" 1 "LEFT_CROSS" 0 "LEFT_PARALLEL" ;
VAL_ 606 PARK_pscLeftParallelObj1X 2047 "SNA" 2046 "NO_SPACE" ;
VAL_ 606 PARK_pscLeftParallelObj1Y 2047 "SNA" 2046 "NO_SPACE" ;
VAL_ 606 PARK_pscLeftParallelObj1Alpha 127 "SNA" 126 "NO_SPACE" ;
VAL_ 606 PARK_pscLeftParallelObj2Y 2047 "SNA" 2046 "NO_SPACE" ;
VAL_ 606 PARK_pscLeftParallelObj2X 2047 "SNA" 2046 "NO_SPACE" ;
VAL_ 606 PARK_pscLeftParallelObj2Alpha 127 "SNA" 126 "NO_SPACE" ;
VAL_ 606 PARK_pscLeftCrossObj1X 2047 "SNA" 2046 "NO_SPACE" ;
VAL_ 606 PARK_pscLeftCrossObj1Y 2047 "SNA" 2046 "NO_SPACE" ;
VAL_ 606 PARK_pscLeftCrossObj1Alpha 127 "SNA" 126 "NO_SPACE" ;
VAL_ 606 PARK_pscLeftCrossObj2Y 2047 "SNA" 2046 "NO_SPACE" ;
VAL_ 606 PARK_pscLeftCrossObj2X 2047 "SNA" 2046 "NO_SPACE" ;
VAL_ 606 PARK_pscLeftCrossObj2Alpha 127 "SNA" 126 "NO_SPACE" ;
VAL_ 606 PARK_pscRightParallelObj1X 2047 "SNA" 2046 "NO_SPACE" ;
VAL_ 606 PARK_pscRightParallelObj1Y 2047 "SNA" 2046 "NO_SPACE" ;
VAL_ 606 PARK_pscRightParallelObj1Alpha 127 "SNA" 126 "NO_SPACE" ;
VAL_ 606 PARK_pscRightParallelObj2Y 2047 "SNA" 2046 "NO_SPACE" ;
VAL_ 606 PARK_pscRightParallelObj2X 2047 "SNA" 2046 "NO_SPACE" ;
VAL_ 606 PARK_pscRightParallelObj2Alpha 127 "SNA" 126 "NO_SPACE" ;
VAL_ 606 PARK_pscRightCrossObj1X 2047 "SNA" 2046 "NO_SPACE" ;
VAL_ 606 PARK_pscRightCrossObj1Y 2047 "SNA" 2046 "NO_SPACE" ;
VAL_ 606 PARK_pscRightCrossObj1Alpha 127 "SNA" 126 "NO_SPACE" ;
VAL_ 606 PARK_pscRightCrossObj2Y 2047 "SNA" 2046 "NO_SPACE" ;
VAL_ 606 PARK_pscRightCrossObj2X 2047 "SNA" 2046 "NO_SPACE" ;
VAL_ 606 PARK_pscRightCrossObj2Alpha 127 "SNA" 126 "NO_SPACE" ;
VAL_ 542 PARK_pscParkStatus 7 "SNA" 6 "FAULT" 5 "GUIDANCE_FINISHED" 4 "PRE_GUIDANCE" 3 "GUIDANCE_RIGHT" 2 "GUIDANCE_LEFT" 1 "SEARCHING" 0 "NOT_AVAILABLE" ;
VAL_ 542 PARK_pscParkAbortReason 31 "SNA" 25 "PSC_MOVEMENT_AT_ACTIVATION" 24 "PSC_MAX_WAY_BEHIND_HINT" 23 "PSC_PARK_STC_FAILED" 22 "PSC_PARK_PONR_NOT_REACHED" 21 "PSC_VCTL_GENERAL_ABORT" 20 "PSC_HIGH_TORQUE" 19 "PSC_ASYNC_CTRL_SYSTEM" 18 "ERROR" 17 "SYSTEM_SERVICE" 16 "SYSTEM_FAULT" 15 "ECU_INTERNAL_FAULT" 14 "DAS_ABORT" 13 "EPAS_FAULT" 12 "VEHICLE_DYNAMICS_INTERVENTION" 11 "HANDS_ON_DETECTED" 10 "FULL_WARNING_ON_BOTH_SIDES" 9 "PARK_SPACE_TOO_SMALL" 8 "OBSTACLE_ON_PATH" 7 "MAX_YAW_ANGLE_REACHED" 6 "MAX_SWA_DEV_EXCEEDED" 5 "OFF_TRACK" 4 "UNCONTROLLED_TRAVEL_DIST_REACHED" 3 "NO_VALID_PATH" 2 "MAX_NUM_OF_MOVES" 1 "VELOCITY_TOO_HIGH" 0 "NONE" ;
VAL_ 542 PARK_pscParallelSpace 3 "BOTH_AVAILABLE" 2 "LEFT_AVAILABLE" 1 "RIGHT_AVAILABLE" 0 "NONE_AVAILABLE" ;
VAL_ 542 PARK_pscCrossSpace 3 "BOTH_AVAILABLE" 2 "LEFT_AVAILABLE" 1 "RIGHT_AVAILABLE" 0 "NONE_AVAILABLE" ;
VAL_ 542 PARK_pscParallelRightParkable 3 "SNA" 2 "PARKING_SLOT_OK_POSITION_OK" 1 "PARKING_SLOT_OK" 0 "NONE" ;
VAL_ 542 PARK_pscParallelLeftParkable 3 "SNA" 2 "PARKING_SLOT_OK_POSITION_OK" 1 "PARKING_SLOT_OK" 0 "NONE" ;
VAL_ 542 PARK_pscCrossRightParkable 3 "SNA" 2 "PARKING_SLOT_OK_POSITION_OK" 1 "PARKING_SLOT_OK" 0 "NONE" ;
VAL_ 542 PARK_pscMaxVelocity 63 "SNA" ;
VAL_ 542 PARK_pscCrossLeftParkable 3 "SNA" 2 "PARKING_SLOT_OK_POSITION_OK" 1 "PARKING_SLOT_OK" 0 "NONE" ;
VAL_ 542 PARK_pscParkInstruction 7 "SNA" 5 "EXPLORATION" 4 "ABORTED" 3 "DRIVE_BACKWARD" 2 "DRIVE_FORWARD" 1 "STOP" 0 "NO_MESSAGE" ;
VAL_ 542 PARK_pscManeuverDistance 2047 "SNA" ;
VAL_ 542 PARK_pscAngleActive 1 "REQUEST_CONTROL" 0 "INACTIVE" ;
VAL_ 590 PARK_pscVehSlotType 3 "RIGHT_CROSS" 2 "RIGHT_PARALLEL" 1 "LEFT_CROSS" 0 "LEFT_PARALLEL" ;
VAL_ 590 PARK_pscLeftParallelVehX 2047 "SNA" 2046 "NO_SPACE" ;
VAL_ 590 PARK_pscLeftParallelVehY 2047 "SNA" 2046 "NO_SPACE" ;
VAL_ 590 PARK_pscLeftParallelPsi 8191 "SNA" 8190 "NO_SPACE" ;
VAL_ 590 PARK_pscLeftParallelSizeX 255 "SNA" 254 "NO_SPACE" ;
VAL_ 590 PARK_pscLeftParallelSizeY 255 "SNA" 254 "NO_SPACE" ;
VAL_ 590 PARK_pscLeftCrossVehX 2047 "SNA" 2046 "NO_SPACE" ;
VAL_ 590 PARK_pscLeftCrossVehY 2047 "SNA" 2046 "NO_SPACE" ;
VAL_ 590 PARK_pscLeftCrossPsi 8191 "SNA" 8190 "NO_SPACE" ;
VAL_ 590 PARK_pscLeftCrossSizeX 255 "SNA" 254 "NO_SPACE" ;
VAL_ 590 PARK_pscLeftCrossSizeY 255 "SNA" 254 "NO_SPACE" ;
VAL_ 590 PARK_pscRightParallelVehX 2047 "SNA" 2046 "NO_SPACE" ;
VAL_ 590 PARK_pscRightParallelVehY 2047 "SNA" 2046 "NO_SPACE" ;
VAL_ 590 PARK_pscRightParallelPsi 8191 "SNA" 8190 "NO_SPACE" ;
VAL_ 590 PARK_pscRightParallelSizeX 255 "SNA" 254 "NO_SPACE" ;
VAL_ 590 PARK_pscRightParallelSizeY 255 "SNA" 254 "NO_SPACE" ;
VAL_ 590 PARK_pscRightCrossVehX 2047 "SNA" 2046 "NO_SPACE" ;
VAL_ 590 PARK_pscRightCrossVehY 2047 "SNA" 2046 "NO_SPACE" ;
VAL_ 590 PARK_pscRightCrossPsi 8191 "SNA" 8190 "NO_SPACE" ;
VAL_ 590 PARK_pscRightCrossSizeX 255 "SNA" 254 "NO_SPACE" ;
VAL_ 590 PARK_pscRightCrossSizeY 255 "SNA" 254 "NO_SPACE" ;
VAL_ 526 PARK_sdiSensor1RawDistData 511 "SNA" 500 "NO_OBJECT_DETECTED" 1 "NEAR_DETECTION" 0 "BLOCKED" ;
VAL_ 526 PARK_sdiSensor2RawDistData 511 "SNA" 500 "NO_OBJECT_DETECTED" 1 "NEAR_DETECTION" 0 "BLOCKED" ;
VAL_ 526 PARK_sdiSensor3RawDistData 511 "SNA" 500 "NO_OBJECT_DETECTED" 1 "NEAR_DETECTION" 0 "BLOCKED" ;
VAL_ 526 PARK_sdiSensor4RawDistData 511 "SNA" 500 "NO_OBJECT_DETECTED" 1 "NEAR_DETECTION" 0 "BLOCKED" ;
VAL_ 526 PARK_sdiSensor5RawDistData 511 "SNA" 500 "NO_OBJECT_DETECTED" 1 "NEAR_DETECTION" 0 "BLOCKED" ;
VAL_ 526 PARK_sdiSensor6RawDistData 511 "SNA" 500 "NO_OBJECT_DETECTED" 1 "NEAR_DETECTION" 0 "BLOCKED" ;
VAL_ 558 PARK_sdiSensor7RawDistData 511 "SNA" 500 "NO_OBJECT_DETECTED" 1 "NEAR_DETECTION" 0 "BLOCKED" ;
VAL_ 558 PARK_sdiSensor8RawDistData 511 "SNA" 500 "NO_OBJECT_DETECTED" 1 "NEAR_DETECTION" 0 "BLOCKED" ;
VAL_ 558 PARK_sdiSensor9RawDistData 511 "SNA" 500 "NO_OBJECT_DETECTED" 1 "NEAR_DETECTION" 0 "BLOCKED" ;
VAL_ 558 PARK_sdiSensor10RawDistData 511 "SNA" 500 "NO_OBJECT_DETECTED" 1 "NEAR_DETECTION" 0 "BLOCKED" ;
VAL_ 558 PARK_sdiSensor11RawDistData 511 "SNA" 500 "NO_OBJECT_DETECTED" 1 "NEAR_DETECTION" 0 "BLOCKED" ;
VAL_ 558 PARK_sdiSensor12RawDistData 511 "SNA" 500 "NO_OBJECT_DETECTED" 1 "NEAR_DETECTION" 0 "BLOCKED" ;
VAL_ 814 PARK_frontRightSensorState 3 "SNA" 2 "TEMPORARY_FAILURE" 1 "PERMANENT_FAILURE" 0 "NO_FAILURE" ;
VAL_ 814 PARK_frontRightMiddleSensorState 3 "SNA" 2 "TEMPORARY_FAILURE" 1 "PERMANENT_FAILURE" 0 "NO_FAILURE" ;
VAL_ 814 PARK_frontLeftMiddleSensorState 3 "SNA" 2 "TEMPORARY_FAILURE" 1 "PERMANENT_FAILURE" 0 "NO_FAILURE" ;
VAL_ 814 PARK_frontLeftSensorState 3 "SNA" 2 "TEMPORARY_FAILURE" 1 "PERMANENT_FAILURE" 0 "NO_FAILURE" ;
VAL_ 814 PARK_frontLeftRawDistData 255 "SNA" ;
VAL_ 814 PARK_frontRightRawDistData 255 "SNA" ;
VAL_ 814 PARK_systemStatusFront 3 "SNA" 2 "UNUSED" 1 "ENABLED" 0 "DISABLED" ;
VAL_ 814 PARK_frontDtcPresent 3 "SNA" 2 "UNUSED" 1 "TRUE" 0 "FALSE" ;
VAL_ 830 PARK_rearRightSensorState 3 "SNA" 2 "TEMPORARY_FAILURE" 1 "PERMANENT_FAILURE" 0 "NO_FAILURE" ;
VAL_ 830 PARK_rearRightMiddleSensorState 3 "SNA" 2 "TEMPORARY_FAILURE" 1 "PERMANENT_FAILURE" 0 "NO_FAILURE" ;
VAL_ 830 PARK_rearLeftMiddleSensorState 3 "SNA" 2 "TEMPORARY_FAILURE" 1 "PERMANENT_FAILURE" 0 "NO_FAILURE" ;
VAL_ 830 PARK_rearLeftSensorState 3 "SNA" 2 "TEMPORARY_FAILURE" 1 "PERMANENT_FAILURE" 0 "NO_FAILURE" ;
VAL_ 830 PARK_rearLeftRawDistData 255 "SNA" ;
VAL_ 830 PARK_rearRightRawDistData 255 "SNA" ;
VAL_ 830 PARK_systemStatusRear 3 "SNA" 2 "UNUSED" 1 "ENABLED" 0 "DISABLED" ;
VAL_ 830 PARK_rearDtcPresent 3 "SNA" 2 "UNUSED" 1 "TRUE" 0 "FALSE" ;
VAL_ 798 PARK_status 3 "SNA" 2 "TEMPORARY_FAILURE" 1 "ENABLED" 0 "DISABLED" ;
VAL_ 798 PARK_serviceRequest 3 "SNA" 2 "UNUSED" 1 "FAILURE" 0 "NO_FAILURE" ;
VAL_ 798 PARK_systemDtcPresent 3 "SNA" 2 "UNUSED" 1 "TRUE" 0 "FALSE" ;
VAL_ 798 PARK_majorVersion 255 "SNA" ;
VAL_ 798 PARK_minorVersion 255 "SNA" ;
VAL_ 798 PARK_subMinorVersion 255 "SNA" ;
